VERSION "HNNBNNNYNNNNNNNNNNNNNNNNNNNNNNNNNNNNNNNNNN/4/%%%/4/'%**4NNN///"

NS_ :

BS_:

BU_: AFS_B8 Airbag_B8 Daempfer_B8 Gateway_B8 Getriebe_AL6000 Getriebe_DL5001 Getriebe_VL3002 LWR_B8 Motor_EDC17_003 Motor_EDC17_004 Motor_MED17_B8 Motor_MED9_B8 Motor_SIMOS8_B8 Motor_Slave_B8 Getriebe_AL1000 Motor_MED17_SIMOS8 Motor_EDC17 Gateway_Routing_PAG Gateway_VW EPB_D4 Motor_EDC17_D4 Motor_MED17_003 Hybrid_MSG Hybrid_DQ200 Motor_ME17_BY Motor_MED17_SIMOS8_D4 Motor_EDC17_B8 Getriebe_AL551_951_D4_C7 Getriebe_AL551_Hybrid_D4_C7 Getriebe_DL501_C7 Getriebe_VL381_C7 Motor_MED17_SIMOS8_D4_Hybrid SCU_D4 Gateway_D4C7 Motor_MED17_Q5_Hybrid Fahrwerk STH_D4 Airbag_D4 Gateway_PAG_002 Gateway_VW_T003 Gateway_D4 LEH_Hybrid SCR_C7 BMS_Hybrid Gateway_App_PAG Getriebe_AL1004 Motor_MED17_006 Getriebe_AL5000

BO_ 779 Kombi_01: 8 Gateway_B8
 SG_ KBI_ABS_Lampe : 0|1@1+ (1,0) [0|1] "" Vector__XXX
 SG_ KBI_ESP_Lampe : 1|1@1+ (1,0) [0|1] "" Vector__XXX
 SG_ KBI_BKL_Lampe : 2|1@1+ (1,0) [0|1] "" Vector__XXX
 SG_ KBI_Airbag_Lampe : 3|1@1+ (1,0) [0|1] "" Vector__XXX
 SG_ KBI_SILA_gueltig : 4|1@1+ (1,0) [0|1] "" Vector__XXX
 SG_ KBI_Lenkung_Lampe : 5|1@1+ (1,0) [0|1] "" Vector__XXX
 SG_ KBI_Vorglueh_System_Lampe : 6|1@1+ (1,0) [0|1] "" Vector__XXX
 SG_ KBI_Oeldruck_Schalter : 15|1@1+ (1,0) [0|1] ""  Getriebe_AL551_951_D4_C7
 SG_ KBI_Tankwarnung : 16|1@1+ (1,0) [0|1] ""  Motor_EDC17_003,Motor_EDC17_004,Motor_MED17_B8,Motor_SIMOS8_B8
 SG_ KBI_MFA_v_Einheit_01 : 17|1@1+ (1,0) [0|1] ""  Motor_EDC17_003,Motor_EDC17_004,Motor_MED17_B8,Motor_SIMOS8_B8
 SG_ KBI_im_Stellgliedtest : 18|1@1+ (1,0) [0|1] "" Vector__XXX
 SG_ KBI_Anzeigefehler_LDW : 19|2@1+ (1,0) [0|3] "" Vector__XXX
 SG_ KBI_Variante_USA : 21|1@1+ (1,0) [0|1] "" Vector__XXX
 SG_ KBI_Oeldruckwarnung : 22|1@1+ (1,0) [0|1] "" Vector__XXX
 SG_ KBI_Handbremse : 23|1@1+ (1,0) [0|1] "" Vector__XXX
 SG_ KBI_angez_Geschw : 48|10@1+ (0.32,0) [0|325.12] "km/h"  Getriebe_AL6000,Getriebe_DL5001,Getriebe_VL3002,Motor_EDC17_003,Motor_EDC17_004,Motor_MED17_B8,Motor_SIMOS8_B8
 SG_ KBI_Einheit_Tacho : 58|1@1+ (1,0) [0|1] ""  Getriebe_AL6000,Motor_EDC17_003,Motor_EDC17_004,Motor_MED17_B8,Motor_SIMOS8_B8
 SG_ KBI_Konsistenz_ACC : 59|1@1+ (1,0) [0|1] "" Vector__XXX
 SG_ KBI_Fehler_Anzeige_ACC : 60|1@1+ (1,0) [0|1] "" Vector__XXX
 SG_ KBI_Anzeigefehler_SWA : 61|2@1+ (1,0) [0|3] "" Vector__XXX
 SG_ KBI_KD_Fehler : 63|1@1+ (1,0) [0|1] "" Vector__XXX

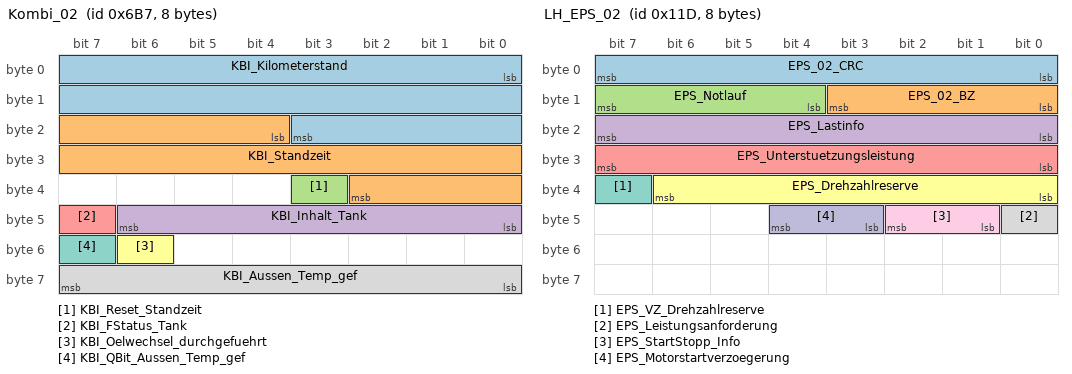
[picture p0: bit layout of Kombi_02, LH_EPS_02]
BO_ 1719 Kombi_02: 8 Gateway_B8
 SG_ KBI_Kilometerstand : 0|20@1+ (1,0) [0|1048573] "km" Vector__XXX
 SG_ KBI_Standzeit : 20|15@1+ (4,0) [0|131068] "s"  Getriebe_AL6000,Getriebe_DL5001,Getriebe_VL3002,Motor_EDC17_003,Motor_EDC17_004,Motor_MED17_B8,Motor_MED9_B8,Motor_SIMOS8_B8
 SG_ KBI_Reset_Standzeit : 35|1@1+ (1,0) [0|1] ""  Getriebe_AL6000,Getriebe_DL5001,Getriebe_VL3002,Motor_EDC17_003,Motor_EDC17_004,Motor_MED17_B8,Motor_MED9_B8,Motor_SIMOS8_B8
 SG_ KBI_Inhalt_Tank : 40|7@1+ (1,0) [0|126] "l"  Motor_EDC17_003,Motor_EDC17_004,Motor_MED17_B8,Motor_MED9_B8,Motor_SIMOS8_B8
 SG_ KBI_FStatus_Tank : 47|1@1+ (1,0) [0|1] ""  Motor_EDC17_003,Motor_EDC17_004,Motor_MED17_B8,Motor_MED9_B8,Motor_SIMOS8_B8
 SG_ KBI_Oelwechsel_durchgefuehrt : 54|1@1+ (1,0) [0|1] ""  Motor_ME17_BY,Motor_MED17_SIMOS8_D4,Motor_MED17_SIMOS8_D4_Hybrid
 SG_ KBI_QBit_Aussen_Temp_gef : 55|1@1+ (1,0) [0|1] ""  Getriebe_AL6000,Getriebe_DL5001,Getriebe_VL3002,Motor_EDC17_003,Motor_EDC17_004,Motor_MED17_B8,Motor_MED9_B8,Motor_SIMOS8_B8
 SG_ KBI_Aussen_Temp_gef : 56|8@1+ (0.5,-50) [-50|75] "°C"  Getriebe_AL6000,Getriebe_DL5001,Getriebe_VL3002,Motor_EDC17_003,Motor_EDC17_004,Motor_MED17_B8,Motor_MED9_B8,Motor_SIMOS8_B8

BO_ 1720 Kombi_03: 8 Gateway_B8
 SG_ KBI_Reifenumfang : 0|12@1+ (1,0) [0|4095] "mm"  Getriebe_AL6000,Getriebe_DL5001,Getriebe_VL3002

BO_ 285 LH_EPS_02: 8 Gateway_D4C7
 SG_ EPS_02_CRC : 0|8@1+ (1,0) [0|255] ""  SCU_D4
 SG_ EPS_02_BZ : 8|4@1+ (1,0) [0|15] ""  SCU_D4
 SG_ EPS_Notlauf : 12|4@1+ (1,0) [0|15] "" Vector__XXX
 SG_ EPS_Lastinfo : 16|8@1+ (1,0) [0|253] "Unit_Amper" Vector__XXX
 SG_ EPS_Unterstuetzungsleistung : 24|8@1+ (0.5,0) [0|100] "Unit_PerCent"  SCU_D4
 SG_ EPS_Drehzahlreserve : 32|7@1+ (10,0) [0|1000] "Unit_DegreOfArcPerSecon"  SCU_D4
 SG_ EPS_VZ_Drehzahlreserve : 39|1@1+ (1,0) [0|1] ""  SCU_D4
 SG_ EPS_Leistungsanforderung : 40|1@1+ (1,0) [0|1] "" Vector__XXX
 SG_ EPS_StartStopp_Info : 41|2@1+ (1,0) [0|3] "" Vector__XXX
 SG_ EPS_Motorstartverzoegerung : 43|2@1+ (1,0) [0|3] "" Vector__XXX

BO_ 1137 Licht_hinten_01: 8 Gateway_B8
 SG_ Licht_hinten_01_BZ : 0|4@1+ (1,0) [0|15] ""  Motor_EDC17_003,Motor_EDC17_004,Motor_MED17_B8,Motor_SIMOS8_B8
 SG_ BCM2_Bremsl_durch_ECD : 5|1@1+ (1,0) [0|1] ""  Motor_EDC17_003,Motor_EDC17_004,Motor_MED17_B8,Motor_SIMOS8_B8
 SG_ LH_Aussenlicht_def : 7|1@1+ (1,0) [0|1] "" Vector__XXX
 SG_ LH_Standlicht_H_aktiv : 8|1@1+ (1,0) [0|1] "" Vector__XXX
 SG_ LH_Parklicht_HL_aktiv : 9|1@1+ (1,0) [0|1] "" Vector__XXX
 SG_ LH_Parklicht_HR_aktiv : 10|1@1+ (1,0) [0|1] "" Vector__XXX
 SG_ LH_Bremslicht_H_aktiv : 11|1@1+ (1,0) [0|1] "" Vector__XXX
 SG_ LH_Nebelschluss_aktiv : 12|1@1+ (1,0) [0|1] "" Vector__XXX
 SG_ LH_Rueckfahrlicht_aktiv : 13|1@1+ (1,0) [0|1] "" Vector__XXX
 SG_ LH_Blinker_HL_akt : 14|1@1+ (1,0) [0|1] "" Vector__XXX
 SG_ LH_Blinker_HR_akt : 15|1@1+ (1,0) [0|1] "" Vector__XXX
 SG_ LH_Blinker_li_def : 16|1@1+ (1,0) [0|1] "" Vector__XXX
 SG_ LH_Bremsl_li_def : 17|1@1+ (1,0) [0|1] "" Vector__XXX
 SG_ LH_Schlusslicht_li_def : 18|1@1+ (1,0) [0|1] "" Vector__XXX
 SG_ LH_Rueckf_li_def : 19|1@1+ (1,0) [0|1] "" Vector__XXX
 SG_ LH_Nebel_li_def : 20|1@1+ (1,0) [0|1] "" Vector__XXX
 SG_ LH_Schluss_Brems_li_def : 24|1@1+ (1,0) [0|1] "" Vector__XXX
 SG_ LH_Schluss_Nebel_li_def : 25|1@1+ (1,0) [0|1] "" Vector__XXX
 SG_ LH_SL_BRL_BLK_li_def : 26|1@1+ (1,0) [0|1] "" Vector__XXX
 SG_ LH_Brems_Blk_li_def : 27|1@1+ (1,0) [0|1] "" Vector__XXX
 SG_ LH_Blinker_re_def : 32|1@1+ (1,0) [0|1] "" Vector__XXX
 SG_ LH_Bremsl_re_def : 33|1@1+ (1,0) [0|1] "" Vector__XXX
 SG_ LH_Schlusslicht_re_def : 34|1@1+ (1,0) [0|1] "" Vector__XXX
 SG_ LH_Rueckf_re_def : 35|1@1+ (1,0) [0|1] "" Vector__XXX
 SG_ LH_Nebel_re_def : 36|1@1+ (1,0) [0|1] "" Vector__XXX
 SG_ LH_Schluss_Brems_re_def : 40|1@1+ (1,0) [0|1] "" Vector__XXX
 SG_ LH_Schluss_Nebel_re_def : 41|1@1+ (1,0) [0|1] "" Vector__XXX
 SG_ LH_SL_BRL_BLK_re_def : 42|1@1+ (1,0) [0|1] "" Vector__XXX
 SG_ LH_Brems_Blk_re_def : 43|1@1+ (1,0) [0|1] "" Vector__XXX
 SG_ LH_Kennzl_def : 48|1@1+ (1,0) [0|1] "" Vector__XXX
 SG_ LH_3_Bremsl_def : 49|1@1+ (1,0) [0|1] ""  Motor_EDC17_003,Motor_EDC17_004,Motor_MED17_B8,Motor_SIMOS8_B8
 SG_ LH_Nebel_mi_def : 50|1@1+ (1,0) [0|1] "" Vector__XXX
 SG_ LH_Rueckf_mi_def : 51|1@1+ (1,0) [0|1] "" Vector__XXX
 SG_ LH_Bremsl_li_ges_def : 54|1@1+ (1,0) [0|1] ""  Motor_EDC17_003,Motor_EDC17_004,Motor_MED17_B8,Motor_SIMOS8_B8
 SG_ LH_Bremsl_re_ges_def : 55|1@1+ (1,0) [0|1] ""  Motor_EDC17_003,Motor_EDC17_004,Motor_MED17_B8,Motor_SIMOS8_B8

BO_ 267 LS_01: 4 Gateway_B8
 SG_ LS_01_CHK : 0|8@1+ (1,0) [0|255] ""  Getriebe_AL6000,Getriebe_DL5001,Getriebe_VL3002,Motor_EDC17_003,Motor_EDC17_004,Motor_MED17_B8,Motor_MED9_B8,Motor_SIMOS8_B8
 SG_ LS_01_BZ : 8|4@1+ (1,0) [0|15] ""  Getriebe_AL6000,Getriebe_DL5001,Getriebe_VL3002,Motor_EDC17_003,Motor_EDC17_004,Motor_MED17_B8,Motor_MED9_B8,Motor_SIMOS8_B8
 SG_ LS_Hauptschalter : 12|1@1+ (1,0) [0|1] ""  Motor_EDC17_003,Motor_EDC17_004,Motor_MED17_B8,Motor_MED9_B8,Motor_SIMOS8_B8
 SG_ LS_Abbrechen : 13|1@1+ (1,0) [0|1] ""  Motor_EDC17_003,Motor_EDC17_004,Motor_MED17_B8,Motor_MED9_B8,Motor_SIMOS8_B8
 SG_ LS_Typ_Hauptschalter : 14|1@1+ (1,0) [0|1] ""  Motor_EDC17_003,Motor_EDC17_004,Motor_MED17_B8,Motor_MED9_B8,Motor_SIMOS8_B8
 SG_ LS_Limiter : 15|1@1+ (1,0) [0|1] ""  Motor_EDC17_003,Motor_EDC17_004,Motor_MED17_B8,Motor_MED9_B8,Motor_SIMOS8_B8
 SG_ LS_Tip_Setzen : 16|1@1+ (1,0) [0|1] ""  Motor_EDC17_003,Motor_EDC17_004,Motor_MED17_B8,Motor_MED9_B8,Motor_SIMOS8_B8
 SG_ LS_Tip_Hoch : 17|1@1+ (1,0) [0|1] ""  Motor_EDC17_003,Motor_EDC17_004,Motor_MED17_B8,Motor_MED9_B8,Motor_SIMOS8_B8
 SG_ LS_Tip_Runter : 18|1@1+ (1,0) [0|1] ""  Motor_EDC17_003,Motor_EDC17_004,Motor_MED17_B8,Motor_MED9_B8,Motor_SIMOS8_B8
 SG_ LS_Tip_Wiederaufnahme : 19|1@1+ (1,0) [0|1] ""  Motor_EDC17_003,Motor_EDC17_004,Motor_MED17_B8,Motor_MED9_B8,Motor_SIMOS8_B8
 SG_ LS_Verstellung_Zeitluecke : 20|2@1+ (1,0) [0|3] "" Vector__XXX
 SG_ MFL_Tip_Down : 22|1@1+ (1,0) [0|1] ""  Getriebe_AL6000,Getriebe_DL5001,Getriebe_VL3002
 SG_ MFL_Tip_Up : 23|1@1+ (1,0) [0|1] ""  Getriebe_AL6000,Getriebe_DL5001,Getriebe_VL3002
 SG_ LS_Tiptronic_Fehler : 24|1@1+ (1,0) [0|1] ""  Getriebe_AL6000,Getriebe_DL5001
 SG_ LS_Fehler : 25|1@1+ (1,0) [0|1] ""  Motor_EDC17_003,Motor_EDC17_004,Motor_MED17_B8,Motor_MED9_B8,Motor_SIMOS8_B8
 SG_ LS_Tip_Stufe_2 : 29|1@1+ (1,0) [0|1] ""  Motor_EDC17,Motor_MED17_SIMOS8
 SG_ LS_GRA_ACC_2stufig : 30|1@1+ (1,0) [0|1] ""  Motor_EDC17,Motor_MED17_SIMOS8
 SG_ LS_Codierung : 26|3@1+ (1,0) [0|7] ""  Motor_EDC17_003,Motor_EDC17_004,Motor_MED17_B8,Motor_MED9_B8,Motor_SIMOS8_B8

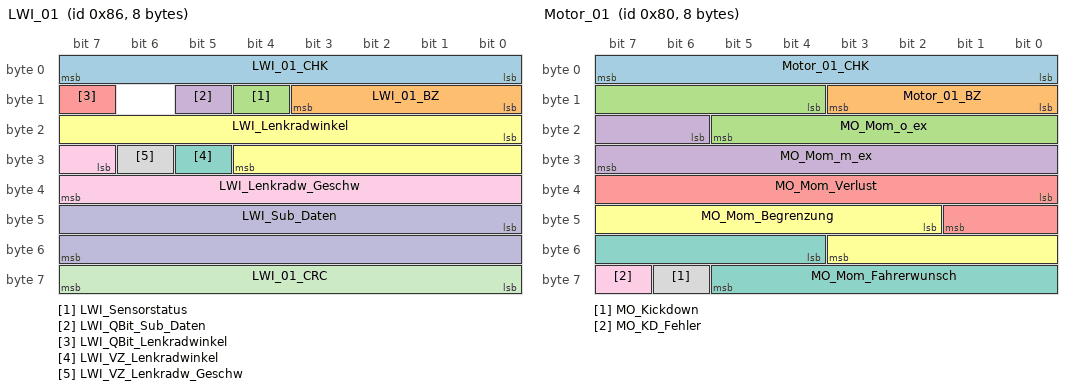
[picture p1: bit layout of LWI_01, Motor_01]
BO_ 134 LWI_01: 8 Gateway_B8
 SG_ LWI_01_CHK : 0|8@1+ (1,0) [0|255] ""  Daempfer_B8,Getriebe_AL6000,Getriebe_DL5001,Getriebe_VL3002,Motor_EDC17_003,Motor_EDC17_004,Motor_MED17_B8,Motor_MED9_B8,Motor_SIMOS8_B8
 SG_ LWI_01_BZ : 8|4@1+ (1,0) [0|15] ""  Daempfer_B8,Getriebe_AL6000,Getriebe_DL5001,Getriebe_VL3002,Motor_EDC17_003,Motor_EDC17_004,Motor_MED17_B8,Motor_MED9_B8,Motor_SIMOS8_B8
 SG_ LWI_Sensorstatus : 12|1@1+ (1,0) [0|1] ""  AFS_B8,Getriebe_AL6000,Motor_EDC17_003,Motor_EDC17_004,Motor_MED17_B8,Motor_MED9_B8,Motor_SIMOS8_B8
 SG_ LWI_QBit_Sub_Daten : 13|1@1+ (1,0) [0|1] "" Vector__XXX
 SG_ LWI_QBit_Lenkradwinkel : 15|1@1+ (1,0) [0|1] ""  Daempfer_B8,Getriebe_AL6000,Motor_EDC17_003,Motor_EDC17_004,Motor_MED17_B8,Motor_MED9_B8,Motor_SIMOS8_B8
 SG_ LWI_Lenkradwinkel : 16|13@1+ (0.1,0) [0|800] "Grad"  AFS_B8,Daempfer_B8,Getriebe_AL6000,Getriebe_DL5001,Getriebe_VL3002,Motor_EDC17_003,Motor_EDC17_004,Motor_MED17_B8,Motor_MED9_B8,Motor_SIMOS8_B8
 SG_ LWI_VZ_Lenkradwinkel : 29|1@1+ (1,0) [0|1] ""  AFS_B8,Daempfer_B8,Getriebe_AL6000,Motor_EDC17_003,Motor_EDC17_004,Motor_MED17_B8,Motor_MED9_B8,Motor_SIMOS8_B8
 SG_ LWI_VZ_Lenkradw_Geschw : 30|1@1+ (1,0) [0|1] "" Vector__XXX
 SG_ LWI_Lenkradw_Geschw : 31|9@1+ (5,0) [0|2500] "Grad/s" Vector__XXX
 SG_ LWI_Sub_Daten : 40|16@1+ (1,0) [0|65535] "" Vector__XXX
 SG_ LWI_01_CRC : 56|8@1+ (1,0) [0|255] "" Vector__XXX

BO_ 917 LWR_AFS_01: 8 AFS_B8
 SG_ LWR_AFS_01_BZ : 8|4@1+ (1,0) [0|15] ""  Gateway_B8
 SG_ AFS_Lampe : 12|1@1+ (1,0) [0|1] ""  Gateway_B8
 SG_ LWR_Lampe : 13|1@1+ (1,0) [0|1] ""  Gateway_B8
 SG_ AFS_Fehlertext : 14|1@1+ (1,0) [0|1] ""  Gateway_B8
 SG_ AFS_LED_Blinkmode : 15|1@1+ (1,0) [0|1] ""  Gateway_B8
 SG_ LWR_Touristenmodus_aktiv : 16|1@1+ (1,0) [0|1] ""  Gateway_B8
 SG_ AFS_Sollwert_LD_EVG : 24|8@1+ (0.4,50) [50|151.2] "%"  Gateway_B8
 SG_ LWR_Pos_Schrittmotor : 32|8@1+ (0.4,0) [0|100] "%"  Gateway_B8
 SG_ LWR_Hoehenwert_VL : 40|8@1+ (1,-127) [-127|126] ""  Gateway_B8
 SG_ LWR_Hoehenwert_HL : 48|8@1+ (1,-127) [-127|126] ""  Gateway_B8
 SG_ AFS_Ersatzlicht_Links : 56|1@1+ (1,0) [0|1] ""  Gateway_B8
 SG_ AFS_Ersatzlicht_Rechts : 57|1@1+ (1,0) [0|1] ""  Gateway_B8
 SG_ LWR_AFS_Grundeinstellung : 58|1@1+ (1,0) [0|1] ""  Gateway_B8
 SG_ LWR_AFS_Parametrisierung : 59|1@1+ (1,0) [0|1] ""  Gateway_B8
 SG_ LWR_Initialisierungslauf : 60|1@1+ (1,0) [0|1] ""  Gateway_B8
 SG_ LWR_Sicherheitsposition : 61|1@1+ (1,0) [0|1] ""  Gateway_B8
 SG_ LWR_Modus : 62|1@1+ (1,0) [0|1] ""  Gateway_B8
 SG_ LWR_KD_Fehler : 63|1@1+ (1,0) [0|1] ""  Gateway_B8

BO_ 128 Motor_01: 8 Motor_EDC17_003
 SG_ Motor_01_CHK : 0|8@1+ (1,0) [0|255] ""  Daempfer_B8,Gateway_B8,Getriebe_AL6000,Getriebe_DL5001,Getriebe_VL3002
 SG_ Motor_01_BZ : 8|4@1+ (1,0) [0|15] ""  Daempfer_B8,Gateway_B8,Getriebe_AL6000,Getriebe_DL5001,Getriebe_VL3002
 SG_ MO_Mom_o_ex : 12|10@1+ (1,0) [0|1021] ""  Gateway_B8,Getriebe_AL6000,Getriebe_DL5001,Getriebe_VL3002
 SG_ MO_Mom_m_ex : 22|10@1+ (1,0) [0|1021] ""  Gateway_B8,Getriebe_AL6000,Getriebe_DL5001,Getriebe_VL3002
 SG_ MO_Mom_Verlust : 32|10@1+ (1,0) [0|1021] ""  Gateway_B8,Getriebe_AL6000,Getriebe_DL5001,Getriebe_VL3002
 SG_ MO_Mom_Begrenzung : 42|10@1+ (1,0) [0|1021] ""  Gateway_B8,Getriebe_AL6000,Getriebe_DL5001,Getriebe_VL3002
 SG_ MO_Mom_Fahrerwunsch : 52|10@1+ (1,0) [0|1021] ""  Daempfer_B8,Gateway_B8,Getriebe_AL6000,Getriebe_DL5001,Getriebe_VL3002
 SG_ MO_Kickdown : 62|1@1+ (1,0) [0|1] ""  Gateway_B8,Getriebe_AL6000,Getriebe_DL5001,Getriebe_VL3002
 SG_ MO_KD_Fehler : 63|1@1+ (1,0) [0|1] ""  Gateway_B8

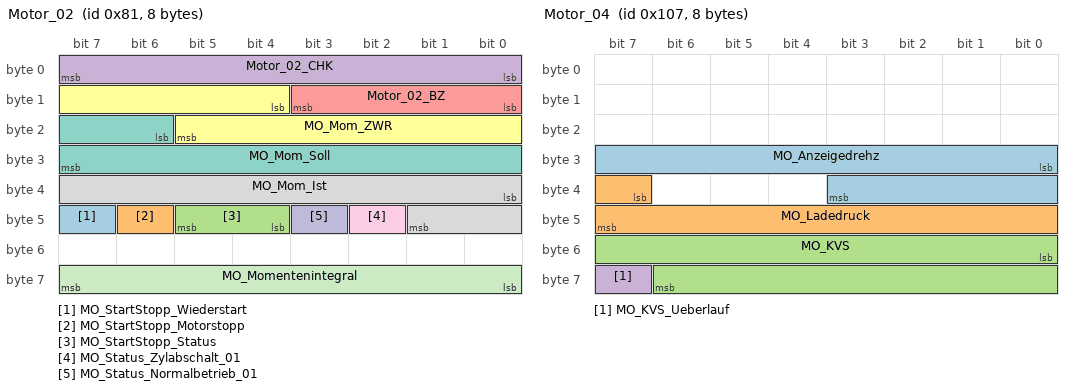
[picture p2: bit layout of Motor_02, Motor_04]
BO_ 129 Motor_02: 8 Motor_EDC17_003
 SG_ MO_StartStopp_Wiederstart : 47|1@1+ (1,0) [0|0] "" Vector__XXX
 SG_ MO_StartStopp_Motorstopp : 46|1@1+ (1,0) [0|0] "" Vector__XXX
 SG_ MO_StartStopp_Status : 44|2@1+ (1,0) [0|0] "" Vector__XXX
 SG_ Motor_02_CHK : 0|8@1+ (1,0) [0|255] ""  Gateway_B8,Getriebe_AL6000,Getriebe_DL5001,Getriebe_VL3002
 SG_ Motor_02_BZ : 8|4@1+ (1,0) [0|15] ""  Gateway_B8,Getriebe_AL6000,Getriebe_DL5001,Getriebe_VL3002
 SG_ MO_Mom_ZWR : 12|10@1+ (1,0) [0|1021] ""  Gateway_B8
 SG_ MO_Mom_Soll : 22|10@1+ (1,0) [0|1021] ""  Gateway_B8,Getriebe_AL6000,Getriebe_DL5001,Getriebe_VL3002
 SG_ MO_Mom_Ist : 32|10@1+ (1,0) [0|1021] ""  Gateway_B8,Getriebe_AL6000,Getriebe_DL5001,Getriebe_VL3002
 SG_ MO_Status_Zylabschalt_01 : 42|1@1+ (1,0) [0|1] ""  Gateway_B8,Getriebe_AL6000,Getriebe_DL5001,Getriebe_VL3002
 SG_ MO_Status_Normalbetrieb_01 : 43|1@1+ (1,0) [0|1] ""  Gateway_B8,Getriebe_AL6000,Getriebe_DL5001,Getriebe_VL3002
 SG_ MO_Momentenintegral : 56|8@1+ (0.3921,0) [0|99.9855] ""  Gateway_B8,Getriebe_AL6000,Getriebe_DL5001,Getriebe_VL3002

BO_ 261 Motor_03: 8 Motor_EDC17_003
 SG_ Motor_03_CHK : 0|8@1+ (1,0) [0|255] ""  Daempfer_B8,Gateway_B8,Getriebe_AL6000,Getriebe_DL5001,Getriebe_VL3002
 SG_ Motor_03_BZ : 8|4@1+ (1,0) [0|15] ""  Daempfer_B8,Gateway_B8,Getriebe_AL6000,Getriebe_DL5001,Getriebe_VL3002
 SG_ MO_QBit_Fahrpedalwerte_01 : 12|1@1+ (1,0) [0|1] ""  Gateway_B8
 SG_ MO_QBit_Motormomente : 13|1@1+ (1,0) [0|1] ""  Gateway_B8,Getriebe_AL6000,Getriebe_DL5001,Getriebe_VL3002
 SG_ MO_QBit_Fahrer_bremst : 14|1@1+ (1,0) [0|1] ""  Gateway_B8,Getriebe_AL6000,Getriebe_DL5001,Getriebe_VL3002
 SG_ MO_QBit_Drehzahl_01 : 15|1@1+ (1,0) [0|1] ""  Gateway_B8
 SG_ MO_Drehzahl_01 : 16|16@1+ (0.25,0) [0|16383] "1/min"  AFS_B8,Gateway_B8,LWR_B8
 SG_ MO_Moment_im_Leerlauf : 32|1@1+ (1,0) [0|1] ""  Gateway_B8
 SG_ MO_Interlock : 33|1@1+ (1,0) [0|1] ""  Gateway_B8
 SG_ MO_BLS : 34|1@1+ (1,0) [0|1] ""  AFS_B8,Daempfer_B8,Gateway_B8,Getriebe_AL6000,Getriebe_DL5001,Getriebe_VL3002,LWR_B8
 SG_ MO_Fahrer_bremst : 35|1@1+ (1,0) [0|1] ""  Gateway_B8,Getriebe_AL6000,Getriebe_DL5001,Getriebe_VL3002
 SG_ MO_Konsistenz_Bremsped : 36|1@1+ (1,0) [0|1] ""  Gateway_B8,Getriebe_AL6000,Getriebe_DL5001,Getriebe_VL3002
 SG_ MO_Kuppl_schalter : 37|1@1+ (1,0) [0|1] ""  Gateway_B8
 SG_ MO_Timeout_ESP : 38|1@1+ (1,0) [0|1] ""  Gateway_B8
 SG_ MO_Motor_laeuft : 39|1@1+ (1,0) [0|1] ""  Gateway_B8
 SG_ MO_Solldrehz_Leerlauf : 40|8@1+ (10,0) [0|2540] "1/min"  Gateway_B8,Getriebe_AL6000,Getriebe_DL5001,Getriebe_VL3002
 SG_ MO_Fahrpedalrohwert_01 : 48|8@1+ (0.4,0) [0|101.6] "%"  Gateway_B8
 SG_ MO_erste_Ungenauschwelle : 56|1@1+ (1,0) [0|1] ""  Gateway_B8,Getriebe_AL6000,Getriebe_DL5001,Getriebe_VL3002
 SG_ MO_QBit_Stressfaktor : 57|1@1+ (1,0) [0|1] ""  Gateway_B8,Getriebe_AL6000,Getriebe_DL5001,Getriebe_VL3002
 SG_ MO_Stressfaktor : 58|6@1+ (1.6,0) [0|100.8] "%"  Gateway_B8,Getriebe_AL6000,Getriebe_DL5001,Getriebe_VL3002

BO_ 263 Motor_04: 8 Motor_EDC17_003
 SG_ MO_Anzeigedrehz : 24|12@1+ (3,0) [0|12282] "1/min"  Gateway_B8
 SG_ MO_Ladedruck : 39|9@1+ (0.01,0) [0|5.1] "bar"  Gateway_B8
 SG_ MO_KVS : 48|15@1+ (1,0) [0|32767] "ul"  Gateway_B8
 SG_ MO_KVS_Ueberlauf : 63|1@1+ (1,0) [0|1] ""  Gateway_B8

BO_ 782 Motor_05: 8 Motor_EDC17_003
 SG_ Motor_05_CHK : 0|8@1+ (1,0) [0|255] ""  Getriebe_AL6000,Getriebe_DL5001,Getriebe_VL3002
 SG_ Motor_05_BZ : 8|4@1+ (1,0) [0|15] ""  Getriebe_AL6000,Getriebe_DL5001,Getriebe_VL3002
 SG_ MO_EKlKomLeiRed : 12|2@1+ (1,0) [0|3] ""  Gateway_PAG_002,Gateway_VW_T003
 SG_ MO_Freig_Reku : 14|2@1+ (1,0) [0|3] ""  Getriebe_AL6000,Getriebe_DL5001,Getriebe_VL3002
 SG_ MO_Klima_Eingr : 16|2@1+ (1,0) [0|3] ""  Gateway_B8
 SG_ MO_Status_Normalbetrieb : 18|1@1+ (1,0) [0|1] ""  Getriebe_AL6000,Getriebe_DL5001
 SG_ MO_Schaltbeeinfl_Leistungsbegr : 19|1@1+ (1,0) [0|1] ""  Getriebe_AL6000,Getriebe_DL5001
 SG_ MO_Schaltbeeinfl_Partikelfilter : 20|1@1+ (1,0) [0|1] ""  Getriebe_AL6000,Getriebe_DL5001
 SG_ MO_Prio_MIN_Wunschdrehzahl : 21|1@1+ (1,0) [0|1] ""  Getriebe_AL6000,Getriebe_DL5001,Getriebe_VL3002
 SG_ MO_Freig_Anlass : 22|1@1+ (1,0) [0|1] ""  Gateway_B8
 SG_ MO_Aussp_Anlass : 23|1@1+ (1,0) [0|1] ""  Gateway_B8
 SG_ MO_MAX_Wunschdrehzahl : 24|9@1+ (25,0) [0|12750] "1/min"  Getriebe_AL6000,Getriebe_DL5001,Getriebe_VL3002
 SG_ MO_Prio_MAX_Wunschdrehzahl : 33|1@1+ (1,0) [0|1] ""  Getriebe_AL6000,Getriebe_DL5001,Getriebe_VL3002
 SG_ MO_Luftpfad_aktiv : 34|1@1+ (1,0) [0|1] ""  Getriebe_AL6000,Getriebe_DL5001
 SG_ MO_v_Begrenz_Aktiv : 35|1@1+ (1,0) [0|1] "" Vector__XXX
 SG_ MO_v_Begrenz_Aktivierbar : 36|1@1+ (1,0) [0|1] "" Vector__XXX
 SG_ MO_Verbot_EKP : 37|1@1+ (1,0) [0|1] ""  Gateway_B8
 SG_ MO_Anf_Pruefimpuls : 38|1@1+ (1,0) [0|1] ""  Gateway_B8
 SG_ MO_Anf_KL75 : 39|1@1+ (1,0) [0|1] ""  Gateway_B8
 SG_ MO_Charisma_FahrPr : 40|3@1+ (1,0) [0|7] ""  Gateway_B8
 SG_ MO_Charisma_Status : 43|2@1+ (1,0) [0|3] ""  Gateway_B8
 SG_ MO_Charisma_Umschaltung : 45|2@1+ (1,0) [0|3] ""  Gateway_B8
 SG_ MO_Handshake_STH : 47|1@1+ (1,0) [0|1] ""  Gateway_B8
 SG_ MO_MIN_Wunschdrehzahl : 48|8@1+ (25,0) [0|6350] "1/min"  Getriebe_AL6000,Getriebe_DL5001,Getriebe_VL3002
 SG_ MO_Drehzahlbeeinflussung : 56|8@1+ (0.39,0) [0|99.45] "%"  Getriebe_AL6000,Getriebe_DL5001,Getriebe_VL3002

BO_ 1088 Motor_06: 8 Motor_EDC17_003
 SG_ MO_Kuehlerluefter_MUX M : 0|1@1+ (1,0) [0|1] ""  Gateway_D4
 SG_ MO_Kuehlerluefter_1 m0 : 1|7@1+ (1,0) [0|100] "Unit_PerCent"  Gateway_D4
 SG_ MO_Kuehlerluefter_2 m1 : 1|7@1+ (1,0) [0|100] "Unit_PerCent"  Gateway_D4
 SG_ WIV_Anzeige_aktiv : 12|1@1+ (1,0) [0|1] ""  Gateway_B8
 SG_ WIV_Oelmin_Warn : 13|1@1+ (1,0) [0|1] ""  Gateway_B8
 SG_ WIV_Sensorfehler : 14|1@1+ (1,0) [0|1] ""  Gateway_B8
 SG_ WIV_Schieflage : 15|1@1+ (1,0) [0|1] ""  Gateway_B8
 SG_ WIV_Oelstand : 16|4@1+ (12.5,0) [0|100] "%"  Gateway_B8
 SG_ WIV_Oelsystem_aktiv : 24|1@1+ (1,0) [0|1] ""  Gateway_B8
 SG_ WIV_nicht_betriebswarm : 25|1@1+ (1,0) [0|1] ""  Gateway_B8
 SG_ WIV_Ueberfuell_Warn : 26|1@1+ (1,0) [0|1] ""  Gateway_B8
 SG_ WIV_laufender_Motor : 27|1@1+ (1,0) [0|1] ""  Gateway_B8
 SG_ MO_Text_Motorstart : 32|4@1+ (1,0) [0|15] ""  Gateway_B8
 SG_ MO_Text_MSG_Werkstatt : 40|1@1+ (1,0) [0|1] ""  Gateway_B8
 SG_ MO_Text_Partikelfil_Reg : 41|1@1+ (1,0) [0|1] ""  Gateway_B8
 SG_ MO_Text_Fehler_Kraftstoffsys : 42|1@1+ (1,0) [0|1] ""  Gateway_B8
 SG_ WIV_Oelmenge : 43|5@1+ (125,0) [0|3875] "ml"  Gateway_B8
 SG_ MO_Systemlampe : 48|1@1+ (1,0) [0|1] ""  Gateway_B8
 SG_ MO_OBD2_Lampe : 49|1@1+ (1,0) [0|1] ""  Gateway_B8
 SG_ MO_Heissleuchte : 50|1@1+ (1,0) [0|1] ""  Gateway_B8
 SG_ MO_Partikel_Lampe : 51|1@1+ (1,0) [0|1] ""  Gateway_B8
 SG_ MO_Winterfahrprog : 52|1@1+ (1,0) [0|1] ""  Gateway_B8
 SG_ WIV_Oelstand_nicht_vorhanden : 53|1@1+ (1,0) [0|1] ""  Gateway_B8
 SG_ WIV_nachfuellanzeige_ein : 54|1@1+ (1,0) [0|1] ""  Gateway_B8
 SG_ WIV_Check_Oil : 55|1@1+ (1,0) [0|1] ""  Gateway_B8
 SG_ WIV_Unterfuell_Warn : 56|1@1+ (1,0) [0|1] ""  Gateway_B8
 SG_ MO_Tankdeckel_Lampe : 57|1@1+ (1,0) [0|1] ""  Gateway_B8
 SG_ MO_Text_Tankdeckelwarn : 58|1@1+ (1,0) [0|1] ""  Gateway_B8
 SG_ WIV_Enable_Oeldr_Motor : 59|1@1+ (1,0) [0|1] ""  Gateway_B8
 SG_ WIV_Oeldr_Warn_Motor : 60|1@1+ (1,0) [0|1] ""  Gateway_B8
 SG_ MO_Avus_Motorschutz : 61|2@1+ (1,0) [0|3] ""  Gateway_B8

BO_ 1600 Motor_07: 8 Motor_EDC17_D4
 SG_ MO_QBit_Ansaugluft_Temp : 0|1@1+ (1,0) [0|1] ""  Gateway_D4C7,Getriebe_AL551_951_D4_C7,Getriebe_AL551_Hybrid_D4_C7,Getriebe_DL501_C7,Getriebe_VL381_C7
 SG_ MO_QBit_Oel_Temp : 1|1@1+ (1,0) [0|1] ""  Gateway_D4C7,Getriebe_AL551_951_D4_C7,Getriebe_AL551_Hybrid_D4_C7
 SG_ MO_QBit_Kuehlmittel_Temp : 2|1@1+ (1,0) [0|1] ""  Gateway_D4C7,Getriebe_AL551_951_D4_C7,Getriebe_AL551_Hybrid_D4_C7,Getriebe_DL501_C7,Getriebe_VL381_C7,LEH_Hybrid
 SG_ MO_Stellgliedtest_Soundaktuator : 3|1@1+ (1,0) [0|1] ""  Gateway_D4C7
 SG_ MO_HYB_Fehler_HV_Netz : 4|1@1+ (1,0) [0|1] ""  Gateway_D4C7
 SG_ MO_aktives_Getriebeheizen : 5|1@1+ (1,0) [0|1] ""  Gateway_D4C7,Getriebe_AL551_951_D4_C7,Getriebe_AL551_Hybrid_D4_C7,Getriebe_DL501_C7,Getriebe_VL381_C7
 SG_ MO_Absperrventil_oeffnen : 6|2@1+ (1,0) [0|3] ""  Gateway_D4C7
 SG_ MO_Ansaugluft_Temp : 8|8@1+ (0.75,-48) [-48|141.75] "Unit_DegreCelsi"  Gateway_D4C7,Getriebe_AL551_951_D4_C7,Getriebe_AL551_Hybrid_D4_C7,Getriebe_DL501_C7,Getriebe_VL381_C7
 SG_ MO_Oel_Temp : 16|8@1+ (1,-60) [-60|192] "Unit_DegreCelsi"  Gateway_D4C7,Getriebe_AL551_951_D4_C7,Getriebe_AL551_Hybrid_D4_C7
 SG_ MO_Kuehlmittel_Temp : 24|8@1+ (0.75,-48) [-48|141.75] "Unit_DegreCelsi"  Gateway_D4C7,Getriebe_AL551_951_D4_C7,Getriebe_AL551_Hybrid_D4_C7,Getriebe_DL501_C7,Getriebe_VL381_C7,LEH_Hybrid
 SG_ MO_Hoeheninfo : 32|8@1+ (0.00781,0) [0|1.98374] ""  Gateway_D4C7,Getriebe_AL551_951_D4_C7,Getriebe_AL551_Hybrid_D4_C7,Getriebe_DL501_C7,Getriebe_VL381_C7
 SG_ MO_Kennfeldk : 40|1@1+ (1,0) [0|1] ""  Gateway_D4C7
 SG_ MO_Versionsinfo : 41|6@1+ (1,0) [0|63] ""  Gateway_D4C7
 SG_ MO_Getriebe_kuehlen : 47|1@1+ (1,0) [0|1] ""  Gateway_D4C7,Getriebe_AL551_951_D4_C7,Getriebe_AL551_Hybrid_D4_C7,Getriebe_DL501_C7,Getriebe_VL381_C7
 SG_ MO_Mom_Traegheit_02 : 48|5@1+ (0.01,0) [0|0.31] "Unit_KiloGramMeterSquar"  Gateway_D4C7,Getriebe_AL551_951_D4_C7,Getriebe_AL551_Hybrid_D4_C7,Getriebe_DL501_C7,Getriebe_VL381_C7
 SG_ MO_Heizungspumpenansteuerung : 53|4@1+ (10,0) [0|100] "Unit_PerCent"  Gateway_D4C7
 SG_ MO_SpannungsAnf : 57|1@1+ (1,0) [0|1] ""  Gateway_D4C7
 SG_ MO_Nachlaufzeit_Heizungspumpe : 58|6@1+ (15,0) [0|945] "Unit_Secon"  Gateway_D4C7

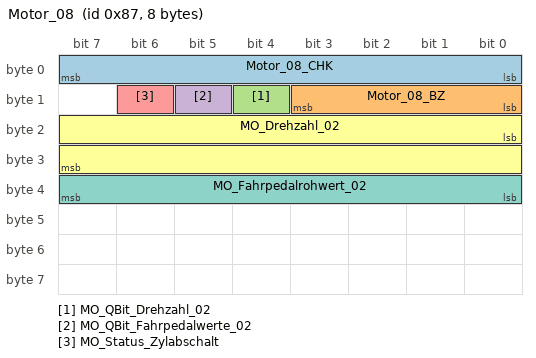
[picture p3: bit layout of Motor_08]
BO_ 135 Motor_08: 8 Motor_EDC17_003
 SG_ Motor_08_CHK : 0|8@1+ (1,0) [0|255] ""  Getriebe_AL6000,Getriebe_DL5001,Getriebe_VL3002
 SG_ Motor_08_BZ : 8|4@1+ (1,0) [0|15] ""  Getriebe_AL6000,Getriebe_DL5001,Getriebe_VL3002
 SG_ MO_QBit_Drehzahl_02 : 12|1@1+ (1,0) [0|1] ""  Getriebe_AL6000,Getriebe_DL5001,Getriebe_VL3002
 SG_ MO_QBit_Fahrpedalwerte_02 : 13|1@1+ (1,0) [0|1] ""  Getriebe_AL6000,Getriebe_DL5001,Getriebe_VL3002
 SG_ MO_Status_Zylabschalt : 14|1@1+ (1,0) [0|1] ""  Getriebe_AL6000,Getriebe_DL5001,Getriebe_VL3002
 SG_ MO_Drehzahl_02 : 16|16@1+ (0.25,0) [0|16383] "1/min"  Getriebe_AL6000,Getriebe_DL5001,Getriebe_VL3002
 SG_ MO_Fahrpedalrohwert_02 : 32|8@1+ (0.4,0) [0|101.6] "%"  Getriebe_AL6000,Getriebe_DL5001,Getriebe_VL3002

BO_ 1607 Motor_09: 8 Motor_EDC17_D4
 SG_ MO_ITM_Kuehlmittel_Temp : 0|8@1+ (0.75,-48) [-45.75|143.25] "Unit_DegreCelsi"  Gateway_D4C7
 SG_ MO_E85_Sensor : 8|4@1+ (10,0) [0|100] "Unit_PerCent"  Gateway_D4C7
 SG_ SCR_Anz_Motorstarts : 12|4@1+ (1,0) [0|8] ""  Gateway_D4C7
 SG_ SCR_Reichweite : 16|15@1+ (1,0) [0|32766] ""  Gateway_D4C7
 SG_ SCR_Warnstufe_1 : 32|1@1+ (1,0) [0|1] ""  Gateway_D4C7
 SG_ SCR_Warnstufe_2 : 33|1@1+ (1,0) [0|1] ""  Gateway_D4C7
 SG_ SCR_Text : 34|3@1+ (1,0) [0|7] ""  Gateway_D4C7
 SG_ SCR_Akustik : 37|2@1+ (1,0) [0|3] ""  Gateway_D4C7
 SG_ MO_Kraftstofffilter_Wasser : 40|1@1+ (1,0) [0|1] ""  Gateway_D4C7
 SG_ SCR_Systemfehler : 41|1@1+ (1,0) [0|1] ""  Gateway_D4C7
 SG_ SCR_Inducement_Strategie : 42|2@1+ (1,0) [0|3] ""  Gateway_D4C7
 SG_ MO_CO2_Faktor : 44|12@1+ (1,0) [1|4094] "Unit_GramPerLiter"  Gateway_D4C7
 SG_ MO_MKB_MUX M : 56|2@1+ (1,0) [0|3] ""  Gateway_D4C7
 SG_ MO_MKB_01 m0 : 59|5@1+ (1,0) [0|31] ""  Gateway_D4C7
 SG_ MO_MKB_02 m1 : 59|5@1+ (1,0) [0|31] ""  Gateway_D4C7
 SG_ MO_MKB_03 m2 : 59|5@1+ (1,0) [0|31] ""  Gateway_D4C7
 SG_ MO_MKB_04 m3 : 59|5@1+ (1,0) [0|31] ""  Gateway_D4C7

BO_TX_BU_ 917 : AFS_B8,LWR_B8;
BO_TX_BU_ 128 : Motor_EDC17_003,Motor_EDC17_004,Motor_MED17_B8,Motor_MED9_B8,Motor_SIMOS8_B8;
BO_TX_BU_ 129 : Motor_EDC17_003,Motor_EDC17_004,Motor_MED17_B8,Motor_MED9_B8,Motor_SIMOS8_B8;
BO_TX_BU_ 261 : Motor_EDC17_003,Motor_EDC17_004,Motor_MED17_B8,Motor_MED9_B8,Motor_SIMOS8_B8;
BO_TX_BU_ 263 : Motor_EDC17_003,Motor_EDC17_004,Motor_MED17_B8,Motor_MED9_B8,Motor_SIMOS8_B8;
BO_TX_BU_ 782 : Motor_EDC17_003,Motor_EDC17_004,Motor_MED17_B8,Motor_MED9_B8,Motor_SIMOS8_B8;
BO_TX_BU_ 1088 : Motor_EDC17_003,Motor_EDC17_004,Motor_MED17_B8,Motor_MED9_B8,Motor_SIMOS8_B8;
BO_TX_BU_ 1600 : Motor_EDC17_003,Motor_EDC17_004,Motor_MED17_B8,Motor_MED9_B8,Motor_SIMOS8_B8;
BO_TX_BU_ 135 : Motor_EDC17_003,Motor_EDC17_004,Motor_MED17_B8,Motor_MED9_B8,Motor_SIMOS8_B8;
CM_ SG_ 779 KBI_ABS_Lampe "ABS-Sicherheits-Lampe wurde eingeschaltet.";
CM_ SG_ 779 KBI_ESP_Lampe "ESP-Sicherheits-Lampe wurde eingeschaltet ";
CM_ SG_ 779 KBI_BKL_Lampe "Sicherheits-Lampe Bremskontrolle wurde eingeschaltet; Besonderheit (VW PQ35/46): Lampe wird auch zur Handbremskontrolle (Audi: auch von EPB) und Bremsflüssigkeitswarnung (auch bei Audi) verwendet und vom Kombi aufgeprüft
";
CM_ SG_ 779 KBI_Airbag_Lampe "Airbag Sicherheits-Lampe wurde eingeschaltet ";
CM_ SG_ 779 KBI_SILA_gueltig "Rückmeldeinformation (Bit 1-6) ist gültig";
CM_ SG_ 779 KBI_Lenkung_Lampe "Sicherheits-Lampe der Lenkung (Lenkhilfe EPS, Audi-Dynamic-Steering ...) wurde eingeschaltet.

0x0 = Lenkungs-Lampe aus
0x1 = Lenkungs-Lampe ein";
CM_ SG_ 779 KBI_Vorglueh_System_Lampe "Rückmeldung der Vorglühlampe bzw. Motor Systemlampe (MO_Systemlampe) an den Motor (bei Diesel und Otto!). Hardwaremässig gleiche LED im Kombi (EPC- oder Glühwendel), Unterscheidung nur über Ziffernblatt.";
CM_ SG_ 779 KBI_Tankwarnung "Fahrer wird gewarnt, z.Zt. liegt die Warnschwelle bei 7 Liter.";
CM_ SG_ 779 KBI_MFA_v_Einheit_01 "Einheit der Geschwindigkeit, die vom Fahrer im Car-Menü gewählt wurde. Veränderliche Grösse, im Gegensatz zur Einheit des Tachokranzes.";
CM_ SG_ 779 KBI_im_Stellgliedtest "Kombi im Stellgliedtest, Signal muss eingelesen werden, um Fehlfunktion aufgrund der Bewegung der Stellglieder (Drehzahlmesser, Tacho) des Kombis zu verhindern";
CM_ SG_ 779 KBI_Variante_USA "In diesem Signal wird die HW-Variante des Kombis ausgegeben, ACC plausibilisiert auf dieses Signal hin seine US-Codierung";
CM_ SG_ 779 KBI_Oeldruckwarnung "Öldruckwarnung im Kombi aktiv";
CM_ SG_ 779 KBI_angez_Geschw "Im Tacho angezeigte Geschwindigkeit inklusive der Voreilung

";
CM_ SG_ 779 KBI_Einheit_Tacho "Information, ob es sich um Meilen- oder Kmh-Kombi handelt, Einheit des Tachos entspricht dem Zifferblatt, Grösse ist nicht veränderlich";
CM_ SG_ 779 KBI_Konsistenz_ACC "Rückmeldung an ACC, dass die Botschaften zur Ansteuerung von Anzeigen nicht bzw. nicht konsistent empfangen wurden (Timeout-, BZ-, CHK- und DLC-Fehler)                                                                                                        ";
CM_ SG_ 779 KBI_Fehler_Anzeige_ACC "Rückmeldung an ACC, dass mindestens eine der ACC-relevanten Anzeigen -rote Fahrerübernahme, Mitteldisplay, Gong - fehlerhaft sind.";
CM_ SG_ 779 KBI_Anzeigefehler_SWA "Signal bezieht sich nur auf die SWA-Lampe, Vorhalt für Kombis mit SWA-Lampe. ";
CM_ SG_ 1719 KBI_Kilometerstand "Fehler wird ausgegeben, falls Kilometerstand nicht restaurierbar
";
CM_ SG_ 1719 KBI_Standzeit "Low Byte 4, High Byte 5;
Standzeit in 4 Sekunden Auflösung; mit diesen 15 Bits läßt sich eine Zeit bis 36 Stunden, 24 Minuten und 28 Sekunden darstellen;
Der Standzeitzähler wird mit KL15_Aus gestartet, er bleibt 2 Minuten vor einem Überlauf stehen, di";
CM_ SG_ 1719 KBI_Inhalt_Tank "Restmenge 2 bzw. 2,5l nicht auflösbar

0x7F = Fehler

";
CM_ SG_ 1719 KBI_FStatus_Tank "Signal wird gesetzt:

a) Während der Fehlerentprellzeit (20 s Entprellung)

b) Bei erkanntem Fehler wird der Tankinhalt während der laufenden KL15-Phase über den
    Verbrauch zurückgerechnet. In dieser Zeit ist das Bit ebenfalls gesetzt. Nach einem";
CM_ SG_ 1719 KBI_QBit_Aussen_Temp_gef "0x0 = gültiger Wert
0x1 = Ersatz-, Init- oder Fehlerwert";
CM_ SG_ 1720 KBI_Reifenumfang "Mittlerer Radumfang aus der K-Zahl gerechnet in Millimeter.  Byte 2 Bit 5,4 reserviert, Byte 2 Bit 3..0 und Byte 1 Bit 7..0; Wertebereich 0..4096 mm
";
CM_ SG_ 1137 Licht_hinten_01_BZ "überlaufender 4bit Botschaftszaehler; wird in jeder Sendebotschaft inkrementiert";
CM_ SG_ 1137 BCM2_Bremsl_durch_ECD "Bremslicht (ECD-Bremsung)
";
CM_ SG_ 1137 LH_Aussenlicht_def "Aussenlicht kann nicht mehr korrekt angesteuert werden (EEPROM Codierung kann nicht mehr ausgelesen werden)
";
CM_ SG_ 1137 LH_Standlicht_H_aktiv "Standlicht hinten
";
CM_ SG_ 1137 LH_Parklicht_HL_aktiv "Parklicht hinten links
";
CM_ SG_ 1137 LH_Parklicht_HR_aktiv "Parklicht hinten rechts
";
CM_ SG_ 1137 LH_Bremslicht_H_aktiv "Bremslicht hinten
";
CM_ SG_ 1137 LH_Nebelschluss_aktiv "Nebelschlusslicht
";
CM_ SG_ 1137 LH_Rueckfahrlicht_aktiv "Rueckfahrlicht
";
CM_ SG_ 1137 LH_Blinker_HL_akt "Blinker hinten links
";
CM_ SG_ 1137 LH_Blinker_HR_akt "Blinker hinten rechts
";
CM_ SG_ 1137 LH_Blinker_li_def "Fehlerstatus Blinker hinten links
";
CM_ SG_ 1137 LH_Bremsl_li_def "Fehlerstatus Bremslicht hinten links (Detektion Einzelausfall)
";
CM_ SG_ 1137 LH_Schlusslicht_li_def "Fehlererkennung Schlusslicht hinten links
";
CM_ SG_ 1137 LH_Rueckf_li_def "Fehlererkennung Rückfahrlicht hinten links
";
CM_ SG_ 1137 LH_Nebel_li_def "Fehlererkennung Nebelschlusslicht hinten links
";
CM_ SG_ 1137 LH_Schluss_Brems_li_def "Konfiguration SL+ BRL + PL links und SL+ BRL  links
";
CM_ SG_ 1137 LH_Schluss_Nebel_li_def "Konfiguration SL + NSL links oder SL + NSL + PL links
";
CM_ SG_ 1137 LH_SL_BRL_BLK_li_def "Konfiguration SL + BRL + BLK links oder SL + BRL + BLK + PL links
";
CM_ SG_ 1137 LH_Brems_Blk_li_def "Konfiguration BRL + BLK links
";
CM_ SG_ 1137 LH_Blinker_re_def "Fehlerstatus Blinker hinten rechts
";
CM_ SG_ 1137 LH_Bremsl_re_def "Fehlerstatus Bremslicht hinten rechts  (Detektion Einzelausfall)
";
CM_ SG_ 1137 LH_Schlusslicht_re_def "Fehlererkennung Schlusslicht hinten rechts
";
CM_ SG_ 1137 LH_Rueckf_re_def "Fehlererkennung Rückfahrlicht hinten rechts
";
CM_ SG_ 1137 LH_Nebel_re_def "Fehlererkennung Nebelschlusslicht hinten rechts
";
CM_ SG_ 1137 LH_Schluss_Brems_re_def "Konfiguration SL+ BRL + PL rechts und SL+ BRL  rechts
";
CM_ SG_ 1137 LH_Schluss_Nebel_re_def "Konfiguration SL + NSL rechts oder SL + NSL + PL rechts
";
CM_ SG_ 1137 LH_SL_BRL_BLK_re_def "Konfiguration SL + BRL + BLK rechts oder SL + BRL + BLK + PL rechts
";
CM_ SG_ 1137 LH_Brems_Blk_re_def "Konfiguration BRL + BLK rechts
";
CM_ SG_ 1137 LH_Kennzl_def "Fehlerstatus Kennzeichenbeleuchtung hinten
";
CM_ SG_ 1137 LH_3_Bremsl_def "Fehlerstatus 3. Bremsleuchte
";
CM_ SG_ 1137 LH_Nebel_mi_def "Fehlererkennung Nebelschlusslicht hinten Mitte


";
CM_ SG_ 1137 LH_Rueckf_mi_def "Fehlererkennung Rückfahrlicht Mitte
";
CM_ SG_ 1137 LH_Bremsl_li_ges_def "Fehlerstatus Bremslicht hinten links (Detektion Totalausfall)
";
CM_ SG_ 1137 LH_Bremsl_re_ges_def "Fehlerstatus Bremslicht hinten links (Detektion Totalausfall)
";
CM_ BO_ 267 "Botschaft vom Lenkstockschalter, enthält Information zur Bedienung der GRA und ACC, sowie MFL-Tasten zum Getriebe für TipTronic.";
CM_ SG_ 267 LS_01_CHK "Bildung der CHK: XOR Byte2 XOR Byte 3 ... XOR Byte n  XOR CHK-Endwert  = CHK

Ab B8 ist CHK-Endwert abhängig vom CAN-ID: CHK-Endwert = MSB XOR LSB
MSB: High-Byte des Identifiers der CAN-Botschaft
LSB: Low-Byte des Identifiers der CAN-Botschaft";
CM_ SG_ 267 LS_Abbrechen "GRA : aus mit speichern
ACC : Soft aus";
CM_ SG_ 267 LS_Limiter "Limiter setzen";
CM_ SG_ 267 LS_Tip_Setzen "ACC : Tippschalter Set";
CM_ SG_ 267 LS_Tip_Hoch "GRA : Tip Up
ACC : Tip Up";
CM_ SG_ 267 LS_Tip_Runter "GRA : Tip Down
ACC : Tip Down";
CM_ SG_ 267 LS_Tip_Wiederaufnahme "ACC : Tippschalter Wiederaufnahme";
CM_ SG_ 267 LS_Verstellung_Zeitluecke "Verstellung der Zeitlücke für ACC

DIST -1 = Zeitluecke um 1 Stufe kleiner
DIST +1 = Zeitluecke um 1 Stufe groeßer";
CM_ SG_ 267 MFL_Tip_Down "Tiptronic Tasten vom MFL für Getriebe

0x0 = kein Tip_Down
0x1 = Tip_Down";
CM_ SG_ 267 MFL_Tip_Up "Tiptronic Tasten vom MFL für Getriebe

0x0 = kein Tip_Up
0x1 = Tip_Up";
CM_ SG_ 267 LS_Fehler "0 = in Ordnung
1 = Fehler Bedienteil";
CM_ SG_ 134 LWI_01_CHK "Bildung der CHK:

XOR Byte2 XOR Byte 3 ... XOR Byte n  XOR CHK-Endwert  = CHK

Ab B8 ist CHK-Endwert abhängig vom CAN-ID: CHK-Endwert = MSB XOR LSB
MSB: High-Byte des Identifiers der CAN-Botschaft
LSB: Low-Byte des Identifiers der CAN-Botschaft";
CM_ SG_ 134 LWI_QBit_Sub_Daten "Im B8 gilt die Signalspezifikation: LAH 8K0953B";
CM_ SG_ 134 LWI_QBit_Lenkradwinkel "Ab B8 wird es möglich sein ungenaue Werte des Lenkradwinkels zu detektieren, und dem Empfänger mitzuteilen. Das QBit wird auch bei nicht abgeglichenem Lenkradwinkelsensor gesetzt";
CM_ SG_ 134 LWI_Lenkradwinkel "Wertebereich = +/- 800 Grad
Auflösung = 0,1 Grad
ACHTUNG: spezifizierte Interne Auflösung des Sensors beträgt aber nur Schrittweite 0,5 Grad!

Im B8 gilt die Signalspezifikation: LAH 8K0953B";
CM_ SG_ 134 LWI_VZ_Lenkradwinkel "Vorzeichen Lenkradwinkel gemäss DIN70000;

Nullstellung = +0";
CM_ SG_ 134 LWI_VZ_Lenkradw_Geschw "Vorzeichen Lenkradwinkelgeschwindigkeit gemäss DIN70000; ";
CM_ SG_ 134 LWI_Lenkradw_Geschw "Wertebereich = +/- 2500 Grad/s
Auflösung = 5 Grad/s

Im B8 gilt die Signalspezifikation: LAH 8K0953B ";
CM_ SG_ 134 LWI_Sub_Daten "Verschlüsseltes Datenpaket vom Sub-Rechner des LWS, Verwendung nur durch SCU und ESP_ADS
Verwendung gemäß 'Sicherheitsanforderungen an Empfängersteuergeräte'

Im B8 gilt die Signalspezifikation: LAH 8K0953B";
CM_ SG_ 134 LWI_01_CRC "CRC8 nach Polynom C2";
CM_ SG_ 917 AFS_Lampe "Status der Fehlerlampe: aktuell anliegender Fehlerzustand des dynamischen oder statischen Kurvenlichtes";
CM_ SG_ 917 LWR_Lampe "Status der Fehlerlampe: aktuell anliegender Fehlerzustand";
CM_ SG_ 917 AFS_Fehlertext "Fehlertext wird im Kombi angezeigt (z.Zt nur bei VW)";
CM_ SG_ 917 AFS_LED_Blinkmode "Lampe soll im Warnfall mit 1Hz blinken, wenn das Bit gesetzt ist (z.Zt nur bei VW)";
CM_ SG_ 917 LWR_Touristenmodus_aktiv "Über MMI sendet BCM1 eine Anforderung Touristenmodus an die LWR. Diese sendet als Rückmeldung an BCM1, dass der Touristenmodus aktiv geschaltet wurde";
CM_ SG_ 917 AFS_Sollwert_LD_EVG "100 % entsprechen 35 Watt. Die Last schaltet nur das ILM

";
CM_ SG_ 917 LWR_Pos_Schrittmotor "Position des Aktuators in Prozent des maximalen Stellweges; vor dem Initialisierungslauf (Motorstart) wird der Initwert ausgegeben:
0% : tiefste Stellung (auf Block) des Schrittmotors;
100% : maximaler Verstellweg des Schrittmotors (nicht die Grenze de";
CM_ SG_ 917 LWR_Hoehenwert_VL "Aktueller Höhensensorwert Vorne Links

0x7F = 0 mm";
CM_ SG_ 917 LWR_Hoehenwert_HL "Aktueller Höhensensorwert Hinten Links

0x7F = 0 mm
";
CM_ SG_ 917 AFS_Ersatzlicht_Links "Bei aktivierter Ersatzlichtfunktion wird das Abblendlicht ausgeschaltet und eine Ersatzlichtquelle eingeschaltet (z.Zt. B7)";
CM_ SG_ 917 AFS_Ersatzlicht_Rechts "Bei aktivierter Ersatzlichtfunktion wird das Abblendlicht ausgeschaltet und eine Ersatzlichtquelle eingeschaltet (z.Zt. B7)";
CM_ SG_ 917 LWR_AFS_Grundeinstellung "Grundeinstellung des Abblendlichtes am Lichteinstellkasten im Service oder Bandende mit Tester erfolgt! (auch für das dynamische Kurvernlicht)";
CM_ SG_ 917 LWR_AFS_Parametrisierung "Parametrisierung wählt die Fahrzeugvariante und die AFS-Variante aus";
CM_ SG_ 917 LWR_Initialisierungslauf "Initialisierungslauf der Schrittmotoren, erfolgt defaultmäßig beim Motorstart";
CM_ SG_ 917 LWR_Sicherheitsposition "LWR Sicherheitsposition beider Scheinwerfers";
CM_ SG_ 917 LWR_Modus "Schnelle oder langsame Regelart der LWR";
CM_ SG_ 917 LWR_KD_Fehler "Bei gesetztem Bit ist mindestens ein Kundendienstfehler eingetragen";
CM_ SG_ 128 Motor_01_CHK "Bildung der CHK:

XOR Byte2 XOR Byte 3 ... XOR Byte n  XOR CHK-Endwert  = CHK

Ab B8 ist CHK-Endwert abhängig vom CAN-ID: CHK-Endwert = MSB XOR LSB
MSB: High-Byte des Identifiers der CAN-Botschaft
LSB: Low-Byte des Identifiers der CAN-Botschaft";
CM_ SG_ 128 MO_Mom_o_ex "Achtung:
Einheitenloser CAN-Wert.
Faktor in MO_Faktor_Momente in Motor_Code_01 beachten!

Indiziertes Motormoment ohne externe Eingriffe (ASR, MSR, Getriebe ...) aber inklusive integrierter GRA";
CM_ SG_ 128 MO_Mom_m_ex "Achtung:
Einheitenloser CAN-Wert.
Faktor in MO_Faktor_Momente in Motor_Code_01 beachten!

Indiziertes Motormoment, d.h. idealisiertes berechnetes Moment ohne mechanische Verluste, aber mit externen Eingriffen.";
CM_ SG_ 128 MO_Mom_Verlust "Achtung:
Einheitenloser CAN-Wert.
Faktor in MO_Faktor_Momente in Motor_Code_01 beachten!

Beinhaltet z.Zt. Reibung vom Motor und Klimakompressor, beim TDI z.T. auch die Generatorverluste";
CM_ SG_ 128 MO_Mom_Begrenzung "Achtung:
Einheitenloser CAN-Wert.
Faktor in MO_Faktor_Momente in Motor_Code_01 beachten!

Inneres maximal mögliches Moment bei einer Drehzahl (z.B. Rauchbegrenzung oder Fehlerfall)";
CM_ SG_ 128 MO_Mom_Fahrerwunsch "Achtung:
Einheitenloser CAN-Wert.
Faktor in MO_Faktor_Momente in Motor_Code_01 beachten!

Moment vor Filter, nutzbar zur Zug- / Schuberkennung beim Getriebe (beim Diesel identisch mit innerem Moment ohne externe Eingriffe)";
CM_ SG_ 128 MO_Kickdown "Es gilt: Signalspec MO_Kickdown v1.0";
CM_ SG_ 128 MO_KD_Fehler "Kundendienstfehlerspeicherbit";
CM_ SG_ 129 Motor_02_CHK "Bildung der CHK:

XOR Byte2 XOR Byte 3 ... XOR Byte n  XOR CHK-Endwert  = CHK

Ab B8 ist CHK-Endwert abhängig vom CAN-ID: CHK-Endwert = MSB XOR LSB
MSB: High-Byte des Identifiers der CAN-Botschaft
LSB: Low-Byte des Identifiers der CAN-Botschaft";
CM_ SG_ 129 MO_Mom_ZWR "Minimales Motormoment bei Zündwinkelrücknahme.

Achtung:
Einheitenloser CAN-Wert.
Faktor in MO_Faktor_Momente in Motor_Code_01 beachten!";
CM_ SG_ 129 MO_Mom_Soll "Achtung:
Einheitenloser CAN-Wert.
Faktor in MO_Faktor_Momente in Motor_Code_01 beachten!

Sollmoment ohne P und D Anteil des Leerlaufreglers, ohne Antiruckelfunktion und ohne Getriebeeingriff";
CM_ SG_ 129 MO_Mom_Ist "Achtung:
Einheitenloser CAN-Wert.
Faktor in MO_Faktor_Momente in Motor_Code_01 beachten!

Istmoment ohne P und D Anteil des Leerlaufreglers, ohne Antiruckelfunktion und ohne Getriebeeingriff";
CM_ SG_ 129 MO_Momentenintegral "100 %  entspricht volle Verfügbarkeit aktuell vorhanden. 0 % entspricht Integral bis Limit gefüllt, erhöhender Eingriff kann aktuell nicht berücksichtigt werden oder erhöhender Eingriff ist in diesem Projekt nicht möglich (applikativ deaktiviert) oder auf";
CM_ SG_ 261 Motor_03_CHK "Bildung der CHK:

XOR Byte2 XOR Byte 3 ... XOR Byte n  XOR CHK-Endwert  = CHK

Ab B8 ist CHK-Endwert abhängig vom CAN-ID: CHK-Endwert = MSB XOR LSB
MSB: High-Byte des Identifiers der CAN-Botschaft
LSB: Low-Byte des Identifiers der CAN-Botschaft";
CM_ SG_ 261 MO_QBit_Fahrpedalwerte_01 "QBit für beide Fahrpedalwerte des Motors (Fahrpedalrohsignal für ESP, EPB, ACC; Fahrpedalwert für Getriebe)";
CM_ SG_ 261 MO_QBit_Motormomente "Ungenaue Momentenangaben, weil die Momente aus Ersatzwerten berechnet wurden (z.B. HFM ausgefallen). Qualifizierungsbit für die Motormomente.";
CM_ SG_ 261 MO_Drehzahl_01 "Im Fehlerfall wird die Motordrehzahl über die Nockenwellendrehzahl als Ersatzgrösse ausgegeben";
CM_ SG_ 261 MO_Moment_im_Leerlauf "Achtung:
Einheitenloser CAN-Wert.
Faktor in MO_Faktor_Momente in Motor_Code_01 beachten!

Motorbetriebszustand ist Leerlauf, keine Momentenerhöhung durch Fahrpedal, ACC, GRA+";
CM_ SG_ 261 MO_Interlock "Der Interlockschalter (= Kupplung komplett getreten) muß beim Handschalter betätigt sein, damit ein Motorstart erlaubt ist";
CM_ SG_ 261 MO_BLS "Ungefiltertes Rohsignal des Bremslichtschalters, nur wenn HW-Eingang bestückt und ausgewertet wird. Bei Motoren ohne genutzten HW-Eingang wird kein Ersatzwert (bspw. SW-Signal über CAN) ausgegeben!
Bei AUDI muss das Signal wg. Bremslichtfunktion immer be";
CM_ SG_ 261 MO_Fahrer_bremst "Redundante Bremsinformation vom Motor. Im B8 wird in diesem Bit der Wert der ESP-CAN-Information 'ESP_Fahrer_bremst' ausgegeben.";
CM_ SG_ 261 MO_Konsistenz_Bremsped "Siehe 'Funktionsspezifikation Bremslichtinfo B8'";
CM_ SG_ 261 MO_Kuppl_schalter "Nur Handschalter; aktiv, wenn Schalter verbaut; sonst konstant auf '0' gesetzt; Bit wird gesetzt, wenn Kupplungspedal betätigt wird (Kupplungsschalter hoch), Triebstrang kann noch eingekuppelt sein.";
CM_ SG_ 261 MO_Timeout_ESP "500 ms Timeout auf Bremsen-Botschaft ist >= 1 mal aufgelaufen, Löschen des Bits nach Neustart (KL15).";
CM_ SG_ 261 MO_Motor_laeuft "Es gilt: Signalspec MO_Motor_laeuft v1.0

Dieses Bit signalisiert, dass der Motor autark läuft und mechanisch belastbar ist. Das Bit wird abhängig von den Umgebungsbedingungen gesetzt, so kann in grosser Höhe (Gebirge) trotz erhöhter Drehzahl der Motor ";
CM_ SG_ 261 MO_Solldrehz_Leerlauf "Leerlaufsolldrehzahl, die im Motor eingestellt ist. Der Motor paßt aufgrund der Anforderung von anderen
Steuergeräten seine Leerlaufsolldrehzahl an, bspw. Kat-Heizen, Anforderung vom Getriebe etc.";
CM_ SG_ 261 MO_Fahrpedalrohwert_01 "Stellung des Fahrpedales (Rohwert, ohne Überlagerung durch GRA-Eingriffe etc.)";
CM_ SG_ 261 MO_erste_Ungenauschwelle "Zusätzliche Ungenauigkeit (zur Grundungenauigkeit). Motormomente ungenau >8% (kleinste Ungenauschwelle)";
CM_ SG_ 261 MO_Stressfaktor "Berücksichtigung von Höhe und Ansauglufttemperatur im aktuellen Betriebspunkt. Berücksichtigung bei Berechnung der ACC-Sollbeschleunigung. Fehlerwert existiert nicht, 0x3F ist gültiger Wert!

100%: kein Stress (Motor verfügt über das ganze Moment, z.B. ";
CM_ SG_ 263 MO_Anzeigedrehz "Optimierte Anzeigedrehzahl wegen sportlicherem Drehzahlmesser im Kombi. ";
CM_ SG_ 263 MO_Ladedruck "Zur Anzeige im Kombi, z.Zt. nur Porsche Colorado und PQ35 Biturbo, ab B8 Vorhalt";
CM_ SG_ 263 MO_KVS "Motorsteuergerätinterner Verbrauchszähler, der vom Kombi zyklisch ausgelesen wird, um die Einspritzmenge zur Verbrauchsmessung aufzusummieren; aus diesem Zählerstand werden Momentan- und Durchschnittsverbrauch berechnet; das Überlauf-Bit ist zu berücksich";
CM_ SG_ 263 MO_KVS_Ueberlauf "Der motorsteuergeräteinterne Verbrauchszähler ist mindestens einmal übergelaufen. Dieses Bit wird genutzt, um erkennen zu können, daß das Motorsteuergerät aus dem Reset-Zustand hochläuft.";
CM_ SG_ 782 Motor_05_CHK "Bildung der CHK:

XOR Byte2 XOR Byte 3 ... XOR Byte n  XOR CHK-Endwert  = CHK

Ab B8 ist CHK-Endwert abhängig vom CAN-ID: CHK-Endwert = MSB XOR LSB
MSB: High-Byte des Identifiers der CAN-Botschaft
LSB: Low-Byte des Identifiers der CAN-Botschaft";
CM_ SG_ 782 MO_Klima_Eingr "Eingriffe des Motor bei der Klima";
CM_ SG_ 782 MO_Status_Normalbetrieb "Das Motorsteuergerät sendet das Informationsbit, wenn die Initialisierungsphase des Steuergerätes abgeschlossen ist. Zusätzlich muss die Klemme 15 eingeschalten sein und eine applizierbare Mindestdrehzahlschwelle (Kennlinie in Abh. von der Kühlwassertempe";
CM_ SG_ 782 MO_Schaltbeeinfl_Leistungsbegr "Schaltbeeinflussung an das Getriebe wegen Leistungsbegrenzung";
CM_ SG_ 782 MO_Schaltbeeinfl_Partikelfilter "Schaltbeeinflussung an das Getriebe wegen Partikelfilter-Regeneration
";
CM_ SG_ 782 MO_Prio_MIN_Wunschdrehzahl "Motorwunschdrehzahl in Byte 7 ist als Zwang oder als Wunsch an das Getriebe zu interpretieren";
CM_ SG_ 782 MO_Freig_Anlass "Bit wird gesetzt, wenn der Motor beim Automatikstart gestartet werden darf (Motorstillstand, Emissionsmaßnahmen sind erfüllt).";
CM_ SG_ 782 MO_Aussp_Anlass "Bit wird gesetzt, wenn der Motorhochlauf ohne Anlasserunterstützung beendet werden kann oder ein Start-Timeout erreicht wurde.";
CM_ SG_ 782 MO_MAX_Wunschdrehzahl "Wenn das Bit 'MO_Prio_MIN_Wunschdrehzahl' gesetzt wird, wird hier vom Motor-SG eine wegen Partikelfilterregeneration bedingte minimale Motordrehzahl ausgegeben, die das Getriebe-SG nicht unterschreiten darf. Zum B8 Anpassung des Wertebereiches auf 9Bit we";
CM_ SG_ 782 MO_Prio_MAX_Wunschdrehzahl "Motorwunschdrehzahl in Byte 4 ist als Zwang oder als Wunsch an das Getriebe zu interpretieren";
CM_ SG_ 782 MO_Luftpfad_aktiv "Getriebeeingriff wird zusätzlich zum Zündungspfad auch über den Luftpfad umgesetzt, kommt zu B8 neu in die PL48-Getriebe";
CM_ SG_ 782 MO_v_Begrenz_Aktiv "Motor begrenzt aktuell die Geschwindigkeit des Fahrzeugs; Reaktion auf externe oder interne Anforderung";
CM_ SG_ 782 MO_v_Begrenz_Aktivierbar "Fehlerbit wird vom Motor-SG gesetzt, wenn dieses nicht in dieGeschwindigkeits-begrenzung gehen kann, ein Fehler während der v-Begrenzung auftritt oder v > v_Begrenzung - v_Delta";
CM_ SG_ 782 MO_Verbot_EKP "Es gilt: Signalspec MO_Verbot_EKP V1.1

MSG sendet Verbot der EKP-Ansteuerung an das BCM";
CM_ SG_ 782 MO_Anf_Pruefimpuls "Es gilt: Signalspec MO_Anf_Pruefimpuls v1.1

Anforderung des MSG an das BCM  zum Senden eines Prüfimpulses zur Diagnose der Wakeup-Leitung auf Dauerlow";
CM_ SG_ 782 MO_Anf_KL75 "Information wann die Kl. 75 während des Startvorgangs abgeschaltet werden soll. Umsetzung durch BCM2.";
CM_ SG_ 782 MO_Charisma_FahrPr "Aktuelles Fahrprogramm des Charisma-Teilnehmers";
CM_ SG_ 782 MO_Charisma_Status "Charisma Systemstatus des Charisma-Teilnehmers";
CM_ SG_ 782 MO_Charisma_Umschaltung "Erkennung  Umschaltaufforderung des Charisma-Teilnehmers";
CM_ SG_ 782 MO_Handshake_STH "Es gilt: Signalspec MO_Handshake v1.0

Handshake zwischen MSG und STH. Wenn das MSG die EKP aufgrund einer STH-Anforderung ansteuert und kein Fehlereintrag bzgl. EKP/KPE/NDR vorliegt, wird das Bit gesetzt.";
CM_ SG_ 782 MO_MIN_Wunschdrehzahl "Wenn das Bit 'MO_Prio_MAX_Wunschdrehzahl' gesetzt wird, wird hier vom Motor-SG eine wegen Partikelfilterregeneration bedingte minimale Motordrehzahl ausgegeben, die das Getriebe-SG nicht unterschreiten darf.";
CM_ SG_ 782 MO_Drehzahlbeeinflussung "Mit diesem Faktor kann das Motorsteuergerät die vom CVT-Getriebe einzustellende Sollmotodrehzahl beeinflussen. Im CVT-Steuergerät ist ein verbrauchsoptimales Kennfeld und ein abgasoptimiertes Kennfeld abgelegt. Mit dem Wert von 0-100% wird zwischen diesen";
CM_ SG_ 1088 WIV_Anzeige_aktiv "Peilstabsanzeigefunktion aktiv";
CM_ SG_ 1088 WIV_Oelmin_Warn "Min-Warnung";
CM_ SG_ 1088 WIV_Sensorfehler "Ölstand/Öltemperatursensor (TOG) defekt";
CM_ SG_ 1088 WIV_Schieflage "Fahrzeug steht nicht waagerecht, Messung ungenau";
CM_ SG_ 1088 WIV_Oelstand "8 Segmente zur Balkenanzeige des Ölstands";
CM_ SG_ 1088 WIV_Oelsystem_aktiv "Gesamtölsystem aktiv (entspricht Ölsensor verbaut)";
CM_ SG_ 1088 WIV_nicht_betriebswarm "Motor nicht betriebswarm, Messung ungenau";
CM_ SG_ 1088 WIV_Ueberfuell_Warn "Überfüllungswarnung";
CM_ SG_ 1088 WIV_laufender_Motor "Messung bei laufendem Motor nicht möglich";
CM_ SG_ 1088 MO_Text_MSG_Werkstatt "Über dieses Bit wird im Kombi ein Fehlerklartextanzeige erzeugt werden: 'Motorsteuergerät Werkstatt'.
";
CM_ SG_ 1088 MO_Text_Partikelfil_Reg "Über dieses Bit im Kombi wird ein Klartextanzeige erzeugt werden: 'Partikelfilter benötigt Regeneration'.
";
CM_ SG_ 1088 MO_Text_Fehler_Kraftstoffsys "Über dieses Bit wird im Kombi ein Fehlerklartextanzeige erzeugt wird: 'Fehler im Kraftstoffsystem'.
";
CM_ SG_ 1088 WIV_Oelmenge "Ölmenge zwischen Min und Max";
CM_ SG_ 1088 MO_Systemlampe "EGas Systemlampe (EPC) oder Vorglühlampe im Kombi, Kombi steuert immer gleiche
LED an, nur über Ziffernblatt wird die EPC von der Vorglühlampe differenziert";
CM_ SG_ 1088 MO_OBD2_Lampe "OBD bzw. MIL-Lampe wird vom Motorsteuergerät angesteuert, die Information in der Getriebe1 Botschaft (Byte 6, Bit 7...4) wird
vom Motorsteuergerät an das Kombi weitergereicht";
CM_ SG_ 1088 MO_Heissleuchte "Ansteuerung der Kühlwassertemperatur-Heißleuchte (Sensor nur noch am Motorsteuergerät): Temperaturschaltschwellen mit Hysterese (bei VW D1/Colorado Kombi derzeit noch nicht genutzt).";
CM_ SG_ 1088 MO_Partikel_Lampe "Partikelfilter-Lampe wird eingeschaltet";
CM_ SG_ 1088 WIV_Oelstand_nicht_vorhanden "Kein aktueller Ölstand vorhanden";
CM_ SG_ 1088 WIV_nachfuellanzeige_ein "Steuert das Aufblenden der Nachfüllanzeige im Kombi, nach Klemme 15 ein und geöffneter Motorhaube";
CM_ SG_ 1088 WIV_Check_Oil "Anzeige 'Check Oil' im Kombiinstrument ohne Aufruf durch Kunden";
CM_ SG_ 1088 WIV_Unterfuell_Warn "Unterfüllungswarnung";
CM_ SG_ 1088 MO_Tankdeckel_Lampe "Ansteuerung Tankdeckel-Warnlampe Kombiinstrument (nur Ottomotoren) z.Zt. Vorhalt VW";
CM_ SG_ 1088 MO_Text_Tankdeckelwarn "Textbit der Tankdeckelwarnung, z.Zt. Vorhalt VW";
CM_ SG_ 1088 WIV_Enable_Oeldr_Motor "Schaltet die interne Öldruckauswertung im Kombiinstrument ab und aktiviert die Auswertung des Bits 'WIV_Oeldr_Warn_Motor'";
CM_ SG_ 1088 WIV_Oeldr_Warn_Motor "Löst im Kombiinstrument die rote Prio1-Öldruckwarnung (inkl. 3xBeep) aus; die Warnauslösung erfolgt nur bei gleichzeitig gesetztem 'WIV_Enable_Oeldr_Motor'";
CM_ SG_ 1088 MO_Avus_Motorschutz "Warntexten zum Kombi für den Fall des Avus-Notlauf. Priowarnung, kann parallel mit anderen Warnungen
im Mitteldisplay angezeigt werden.";
CM_ SG_ 1600 MO_QBit_Ansaugluft_Temp "
";
CM_ SG_ 1600 MO_QBit_Kuehlmittel_Temp "
";
CM_ SG_ 1600 MO_Ansaugluft_Temp "In Fahrzeugen ohne Außentemperatur vom Kombi kann aus der Ansauglufttemperatur auf die Außentemperatur geschlossen werden. Beim SDI ist das mit einer gewissen Genauigkeit gegeben. Genutzt wird es vom ASG.";
CM_ SG_ 1600 MO_Oel_Temp "Realer Meßbereich ca. -40..150 Grad";
CM_ SG_ 1600 MO_Kuehlmittel_Temp "Kuehlmitteltemperatur";
CM_ SG_ 1600 MO_Hoeheninfo "Korrekturfaktor Höhe (1 entspricht 1013 mbar)";
CM_ SG_ 1600 MO_Kennfeldk "Die Kennfeldkühlung ist in diesem Fahrzeug verbaut und hat keinen Systemfehler";
CM_ SG_ 1600 MO_Versionsinfo "Versioninformation vom Motor zur Steuerung bei inkompatiblen KMatrix-Änderung bzw. Einführung von neuen Funktionen, die in den Empfängern verriegelt werden müssen. Freilaufender Zähler, der nach Änderungsereignis festgelegt wird. Zu jedem Ereignis wird ei";
CM_ SG_ 1600 MO_Mom_Traegheit_02 "Massenträgheit des Motors (J) in kgm²
Bei Handschaltern wird das Zweimassenschwungrad mit berücksichtigt.
Bei eingebautem Getriebesteuergerät wird nur das Motorträgheitsmoment angegeben (Ohne Anteile des Massenschwungrades).";
CM_ BO_ 135 "nur AUDI fuer Stufenautomaten: Teilweise redundant zu Motor_03";
CM_ SG_ 135 Motor_08_CHK "Bildung der CHK:

XOR Byte2 XOR Byte 3 ... XOR Byte n  XOR CHK-Endwert  = CHK

Ab B8 ist CHK-Endwert abhängig vom CAN-ID: CHK-Endwert = MSB XOR LSB
MSB: High-Byte des Identifiers der CAN-Botschaft
LSB: Low-Byte des Identifiers der CAN-Botschaft";
CM_ SG_ 135 MO_QBit_Drehzahl_02 "In Motor_08-Botschaft reduzierte Zykluszeit fuer AUDI Stufenautomaten:
Motor_03: 20ms (wird auf den D-CAN geroutet)
Motor_08: 10ms (reine A-CAN-Botschaft)";
CM_ SG_ 135 MO_QBit_Fahrpedalwerte_02 "QBit für beide Fahrpedalwerte des Motors (Fahrpedalrohsignal für ESP, EPB, ACC; Fahrpedalwert für Getriebe)

In Motor_08-Botschaft reduzierte Zykluszeit fuer AUDI Stufenautomaten:
Motor_03: 20ms (wird auf den D-CAN geroutet)
Motor_08: 10ms (reine A-C";
CM_ SG_ 135 MO_Status_Zylabschalt "Statusbit: Motor ist in Zylinderabschaltregelung:";
CM_ SG_ 135 MO_Drehzahl_02 "Im Fehlerfall wird die Motordrehzahl über die Nockenwellendrehzahl als Ersatzgrösse ausgegeben

In Motor_08-Botschaft reduzierte Zykluszeit fuer AUDI Stufenautomaten:
Motor_03: 20ms (wird auf den D-CAN geroutet)
Motor_08: 10ms (reine A-CAN-Botschaft)";
CM_ SG_ 135 MO_Fahrpedalrohwert_02 "Stellung des Fahrpedales (Rohwert, ohne Überlagerung durch GRA-Eingriffe etc.)

In Motor_08-Botschaft reduzierte Zykluszeit fuer AUDI Stufenautomaten:
Motor_03: 20ms (wird auf den D-CAN geroutet)
Motor_08: 10ms (reine A-CAN-Botschaft)";
CM_ SG_ 1607 MO_ITM_Kuehlmittel_Temp "Kuehlmitteltemperatur: Ersatzkühlmitteltemperatur für Motoren mit ITM (Thermomanagement)";
CM_ SG_ 1607 MO_E85_Sensor "Information über den E85 Gehalt (%-mass.) im Ottokraftstoff";
CM_ SG_ 1607 MO_Kraftstofffilter_Wasser "Für Schlechtkraftstoffländer wird das Wasserabscheidevolumen im Dieselkraftstofffilter mit einem  Wassersensor überwacht. Ist das Volumen erschöpft, erfolgt im Kombi eine entsprechende Anzeige.";
CM_ SG_ 1607 SCR_Systemfehler "Ansteuerung Anzeige für SCR-Systemfehler";
CM_ SG_ 1607 SCR_Inducement_Strategie "Art des Motor-Inducement-Konzepts. Abhängig von diesem Signal sind die Warntexte zwischen 'Kein Motorstart (in...km)' und 'eingeschränkte Fahrbarkeit (in ...km)' auszuwählen.";
CM_ SG_ 1607 MO_CO2_Faktor "dynamischer Umrechnungsfaktor von l in CO2";
CM_ SG_ 1607 MO_MKB_MUX "Die vier Motorkennbuchstaben werden gemultiplext in MO_MKB übertragen. Das Signal MO_MKB_MUX stellt das Steuersignal für diesen Multiplexer dar.";
CM_ SG_ 1607 MO_MKB_01 "Motorkennbuchstabe 1";
CM_ SG_ 1607 MO_MKB_02 "Motorkennbuchstabe 2";
CM_ SG_ 1607 MO_MKB_03 "Motorkennbuchstabe 3";
CM_ SG_ 1607 MO_MKB_04 "Motorkennbuchstabe 4";
BA_DEF_ BO_  "GenMsgAutoGenDsp" ENUM  "No","Yes";
BA_DEF_ BO_  "GenMsgAutoGenSnd" ENUM  "No","Yes";
BA_DEF_ BO_  "GenMsgCycleTime" INT 0 65535;
BA_DEF_ BO_  "GenMsgCycleTimeFast" INT 0 65535;
BA_DEF_ BO_  "GenMsgDelayTime" INT 0 100000;
BA_DEF_ BO_  "GenMsgILSupport" ENUM  "No","Yes";
BA_DEF_ BO_  "GenMsgNrOfRepetition" INT 0 100;
BA_DEF_ BO_  "GenMsgSendType" ENUM  "cyclicX","spontanX","cyclicIfActiveX","spontanWithDelay","cyclicAndSpontanX","cyclicAndSpontanWithDelay","spontanWithRepetition","cyclicIfActiveAndSpontanWD","cyclicIfActiveFast","cyclicWithRepeatOnDemand";
BA_DEF_ BO_  "GenMsgStartDelayTime" INT 0 100000;
BA_DEF_ BO_  "NmMessage" ENUM  "No","Yes";
BA_DEF_ BO_  "NmhMessage" ENUM  "No","Yes";
BA_DEF_ BO_  "NWM-Botschaft" ENUM  "No","Yes";
BA_DEF_ BO_  "VAGTP20_API" HEX 0 255;
BA_DEF_ BO_  "VAGTP20_DynConnection" ENUM  "No","Yes";
BA_DEF_ BO_  "VAGTP20_DynSetup" ENUM  "No","Yes";
BA_DEF_ BO_  "VAGTP20_StatConnection" ENUM  "No","Yes";
BA_DEF_ BO_  "Timeoutzeit" INT 0 1000000;
BA_DEF_ BO_  "akt_Dateninh_NM_Betr" ENUM  "No","Yes";
BA_DEF_ SG_  "GenSigAltSetting" STRING ;
BA_DEF_ SG_  "GenSigAssignSetting" STRING ;
BA_DEF_ SG_  "GenSigAutoGenDsp" ENUM  "No","Yes";
BA_DEF_ SG_  "GenSigAutoGenSnd" ENUM  "No","Yes";
BA_DEF_ SG_  "GenSigConditionalSend" STRING ;
BA_DEF_ SG_  "GenSigEnvVarType" ENUM  "int","float","undef";
BA_DEF_ SG_  "GenSigEVName" STRING ;
BA_DEF_ SG_  "GenSigInactiveValue" INT -2147483648 2147483647;
BA_DEF_ SG_  "GenSigPostIfSetting" STRING ;
BA_DEF_ SG_  "GenSigPostSetting" STRING ;
BA_DEF_ SG_  "GenSigPreIfSetting" STRING ;
BA_DEF_ SG_  "GenSigPreSetting" STRING ;
BA_DEF_ SG_  "GenSigSendType" ENUM  "Cyclic","OnWrite","OnWriteWithRepetition","OnChange","OnChangeWithRepetition","IfActive","IfActiveWithRepetition","NoSigSendType";
BA_DEF_ SG_  "GenSigStartValue" INT -2147483648 2147483647;
BA_DEF_ SG_  "NWM-WakeupAllowed" ENUM  "No","Yes";
BA_DEF_ SG_  "NMH-WakeupAllowed" ENUM  "No","Yes";
BA_DEF_ SG_  "GenSigTimeoutMsg_Motor_EDC17_003" HEX 0 2047;
BA_DEF_ SG_  "GenSigTimeoutMsg_Motor_EDC17_004" HEX 0 2047;
BA_DEF_ SG_  "GenSigTimeoutMsg_Motor_MED17_B8" HEX 0 2047;
BA_DEF_ SG_  "GenSigTimeoutMsg_Motor_MED9_B8" HEX 0 2047;
BA_DEF_ SG_  "GenSigTimeoutMsg_Motor_SIMOS8_B8" HEX 0 2047;
BA_DEF_ SG_  "GenSigTimeoutMsg_Daempfer_B8" HEX 0 2047;
BA_DEF_ SG_  "GenSigTimeoutMsg_Gateway_B8" HEX 0 2047;
BA_DEF_ SG_  "GenSigTimeoutMsg_Getriebe_AL6000" HEX 0 2047;
BA_DEF_ SG_  "GenSigTimeoutMsg_Getriebe_DL5001" HEX 0 2047;
BA_DEF_ SG_  "GenSigTimeoutMsg_Getriebe_VL3002" HEX 0 2047;
BA_DEF_ SG_  "GenSigTimeoutMsg_AFS_B8" HEX 0 2047;
BA_DEF_ SG_  "GenSigTimeoutMsg_Motor_Slave_B8" HEX 0 2047;
BA_DEF_ SG_  "GenSigTimeoutMsg_Airbag_B8" HEX 0 2047;
BA_DEF_ SG_  "GenSigTimeoutMsg_LWR_B8" HEX 0 2047;
BA_DEF_ SG_  "GenSigFuncType" ENUM  "NoFunction","MsgCounter","CRC-8","XOR","XOR-2","DatedBit","SW-Kl15","CHK","Constant","Protocol";
BA_DEF_ SG_  "GenSigSwitchedByIgnition" ENUM  "No","Yes";
BA_DEF_ SG_  "Fehlerwert" HEX 0 2147483647;
BA_DEF_ SG_  "GenSigMissingSourceValue" HEX 0 2147483647;
BA_DEF_ SG_  "SystemSignalLongSymbol" STRING ;
BA_DEF_DEF_  "GenMsgAutoGenDsp" "Yes";
BA_DEF_DEF_  "GenMsgAutoGenSnd" "Yes";
BA_DEF_DEF_  "GenMsgCycleTime" 0;
BA_DEF_DEF_  "GenMsgCycleTimeFast" 0;
BA_DEF_DEF_  "GenMsgDelayTime" 0;
BA_DEF_DEF_  "GenMsgILSupport" "";
BA_DEF_DEF_  "GenMsgNrOfRepetition" 0;
BA_DEF_DEF_  "GenMsgSendType" "cyclicX";
BA_DEF_DEF_  "GenMsgStartDelayTime" 0;
BA_DEF_DEF_  "NmMessage" "No";
BA_DEF_DEF_  "NmhMessage" "No";
BA_DEF_DEF_  "NWM-Botschaft" "No";
BA_DEF_DEF_  "VAGTP20_API" 0;
BA_DEF_DEF_  "VAGTP20_DynConnection" "No";
BA_DEF_DEF_  "VAGTP20_DynSetup" "No";
BA_DEF_DEF_  "VAGTP20_StatConnection" "No";
BA_DEF_DEF_  "Timeoutzeit" 0;
BA_DEF_DEF_  "akt_Dateninh_NM_Betr" "";
BA_DEF_DEF_  "GenSigAltSetting" "";
BA_DEF_DEF_  "GenSigAssignSetting" "";
BA_DEF_DEF_  "GenSigAutoGenDsp" "";
BA_DEF_DEF_  "GenSigAutoGenSnd" "";
BA_DEF_DEF_  "GenSigConditionalSend" "";
BA_DEF_DEF_  "GenSigEnvVarType" "undef";
BA_DEF_DEF_  "GenSigEVName" "";
BA_DEF_DEF_  "GenSigInactiveValue" 0;
BA_DEF_DEF_  "GenSigPostIfSetting" "";
BA_DEF_DEF_  "GenSigPostSetting" "";
BA_DEF_DEF_  "GenSigPreIfSetting" "";
BA_DEF_DEF_  "GenSigPreSetting" "";
BA_DEF_DEF_  "GenSigSendType" "Cyclic";
BA_DEF_DEF_  "GenSigStartValue" 0;
BA_DEF_DEF_  "NWM-WakeupAllowed" "";
BA_DEF_DEF_  "NMH-WakeupAllowed" "";
BA_DEF_DEF_  "GenSigTimeoutMsg_Motor_EDC17_003" 0;
BA_DEF_DEF_  "GenSigTimeoutMsg_Motor_EDC17_004" 0;
BA_DEF_DEF_  "GenSigTimeoutMsg_Motor_MED17_B8" 0;
BA_DEF_DEF_  "GenSigTimeoutMsg_Motor_MED9_B8" 0;
BA_DEF_DEF_  "GenSigTimeoutMsg_Motor_SIMOS8_B8" 0;
BA_DEF_DEF_  "GenSigTimeoutMsg_Daempfer_B8" 0;
BA_DEF_DEF_  "GenSigTimeoutMsg_Gateway_B8" 0;
BA_DEF_DEF_  "GenSigTimeoutMsg_Getriebe_AL6000" 0;
BA_DEF_DEF_  "GenSigTimeoutMsg_Getriebe_DL5001" 0;
BA_DEF_DEF_  "GenSigTimeoutMsg_Getriebe_VL3002" 0;
BA_DEF_DEF_  "GenSigTimeoutMsg_AFS_B8" 0;
BA_DEF_DEF_  "GenSigTimeoutMsg_Motor_Slave_B8" 0;
BA_DEF_DEF_  "GenSigTimeoutMsg_Airbag_B8" 0;
BA_DEF_DEF_  "GenSigTimeoutMsg_LWR_B8" 0;
BA_DEF_DEF_  "GenSigFuncType" "";
BA_DEF_DEF_  "GenSigSwitchedByIgnition" "";
BA_DEF_DEF_  "Fehlerwert" 0;
BA_DEF_DEF_  "GenSigMissingSourceValue" 0;
BA_DEF_DEF_  "SystemSignalLongSymbol" "";
BA_ "GenMsgCycleTime" BO_ 779 50;
BA_ "GenMsgILSupport" BO_ 779 1;
BA_ "akt_Dateninh_NM_Betr" BO_ 779 1;
BA_ "GenMsgCycleTime" BO_ 1719 1000;
BA_ "GenMsgILSupport" BO_ 1719 1;
BA_ "akt_Dateninh_NM_Betr" BO_ 1719 1;
BA_ "GenMsgCycleTime" BO_ 1720 1000;
BA_ "GenMsgILSupport" BO_ 1720 1;
BA_ "akt_Dateninh_NM_Betr" BO_ 1720 1;
BA_ "GenMsgCycleTime" BO_ 1137 100;
BA_ "GenMsgILSupport" BO_ 1137 1;
BA_ "akt_Dateninh_NM_Betr" BO_ 1137 1;
BA_ "GenMsgCycleTime" BO_ 267 100;
BA_ "GenMsgCycleTimeFast" BO_ 267 20;
BA_ "GenMsgDelayTime" BO_ 267 20;
BA_ "GenMsgILSupport" BO_ 267 1;
BA_ "GenMsgSendType" BO_ 267 5;
BA_ "akt_Dateninh_NM_Betr" BO_ 267 0;
BA_ "GenMsgCycleTime" BO_ 134 10;
BA_ "GenMsgILSupport" BO_ 134 1;
BA_ "akt_Dateninh_NM_Betr" BO_ 134 0;
BA_ "GenMsgCycleTime" BO_ 917 100;
BA_ "GenMsgILSupport" BO_ 917 1;
BA_ "akt_Dateninh_NM_Betr" BO_ 917 0;
BA_ "GenMsgCycleTime" BO_ 128 10;
BA_ "GenMsgILSupport" BO_ 128 1;
BA_ "akt_Dateninh_NM_Betr" BO_ 128 1;
BA_ "GenMsgCycleTime" BO_ 129 10;
BA_ "GenMsgILSupport" BO_ 129 1;
BA_ "akt_Dateninh_NM_Betr" BO_ 129 1;
BA_ "GenMsgCycleTime" BO_ 261 20;
BA_ "GenMsgILSupport" BO_ 261 1;
BA_ "akt_Dateninh_NM_Betr" BO_ 261 1;
BA_ "GenMsgCycleTime" BO_ 263 20;
BA_ "GenMsgILSupport" BO_ 263 1;
BA_ "akt_Dateninh_NM_Betr" BO_ 263 1;
BA_ "GenMsgCycleTime" BO_ 782 50;
BA_ "GenMsgILSupport" BO_ 782 1;
BA_ "akt_Dateninh_NM_Betr" BO_ 782 1;
BA_ "GenMsgCycleTime" BO_ 1088 100;
BA_ "GenMsgILSupport" BO_ 1088 1;
BA_ "akt_Dateninh_NM_Betr" BO_ 1088 1;
BA_ "GenMsgCycleTime" BO_ 1600 500;
BA_ "GenMsgILSupport" BO_ 1600 1;
BA_ "akt_Dateninh_NM_Betr" BO_ 1600 1;
BA_ "GenMsgCycleTime" BO_ 135 10;
BA_ "GenMsgILSupport" BO_ 135 1;
BA_ "akt_Dateninh_NM_Betr" BO_ 135 1;
BA_ "GenSigAutoGenDsp" SG_ 779 KBI_ABS_Lampe 1;
BA_ "GenSigAutoGenSnd" SG_ 779 KBI_ABS_Lampe 1;
BA_ "GenSigEnvVarType" SG_ 779 KBI_ABS_Lampe 0;
BA_ "GenSigSendType" SG_ 779 KBI_ABS_Lampe 7;
BA_ "NWM-WakeupAllowed" SG_ 779 KBI_ABS_Lampe 0;
BA_ "NMH-WakeupAllowed" SG_ 779 KBI_ABS_Lampe 0;
BA_ "GenSigAutoGenDsp" SG_ 779 KBI_ESP_Lampe 1;
BA_ "GenSigAutoGenSnd" SG_ 779 KBI_ESP_Lampe 1;
BA_ "GenSigEnvVarType" SG_ 779 KBI_ESP_Lampe 0;
BA_ "GenSigSendType" SG_ 779 KBI_ESP_Lampe 7;
BA_ "NWM-WakeupAllowed" SG_ 779 KBI_ESP_Lampe 0;
BA_ "NMH-WakeupAllowed" SG_ 779 KBI_ESP_Lampe 0;
BA_ "GenSigAutoGenDsp" SG_ 779 KBI_BKL_Lampe 1;
BA_ "GenSigAutoGenSnd" SG_ 779 KBI_BKL_Lampe 1;
BA_ "GenSigEnvVarType" SG_ 779 KBI_BKL_Lampe 0;
BA_ "GenSigSendType" SG_ 779 KBI_BKL_Lampe 7;
BA_ "NWM-WakeupAllowed" SG_ 779 KBI_BKL_Lampe 0;
BA_ "NMH-WakeupAllowed" SG_ 779 KBI_BKL_Lampe 0;
BA_ "GenSigAutoGenDsp" SG_ 779 KBI_Airbag_Lampe 1;
BA_ "GenSigAutoGenSnd" SG_ 779 KBI_Airbag_Lampe 1;
BA_ "GenSigEnvVarType" SG_ 779 KBI_Airbag_Lampe 0;
BA_ "GenSigSendType" SG_ 779 KBI_Airbag_Lampe 7;
BA_ "NWM-WakeupAllowed" SG_ 779 KBI_Airbag_Lampe 0;
BA_ "NMH-WakeupAllowed" SG_ 779 KBI_Airbag_Lampe 0;
BA_ "GenSigAutoGenDsp" SG_ 779 KBI_SILA_gueltig 1;
BA_ "GenSigAutoGenSnd" SG_ 779 KBI_SILA_gueltig 1;
BA_ "GenSigEnvVarType" SG_ 779 KBI_SILA_gueltig 0;
BA_ "GenSigSendType" SG_ 779 KBI_SILA_gueltig 7;
BA_ "NWM-WakeupAllowed" SG_ 779 KBI_SILA_gueltig 0;
BA_ "NMH-WakeupAllowed" SG_ 779 KBI_SILA_gueltig 0;
BA_ "GenSigAutoGenDsp" SG_ 779 KBI_Lenkung_Lampe 1;
BA_ "GenSigAutoGenSnd" SG_ 779 KBI_Lenkung_Lampe 1;
BA_ "GenSigSendType" SG_ 779 KBI_Lenkung_Lampe 7;
BA_ "NWM-WakeupAllowed" SG_ 779 KBI_Lenkung_Lampe 0;
BA_ "NMH-WakeupAllowed" SG_ 779 KBI_Lenkung_Lampe 0;
BA_ "GenSigAutoGenDsp" SG_ 779 KBI_Vorglueh_System_Lampe 1;
BA_ "GenSigAutoGenSnd" SG_ 779 KBI_Vorglueh_System_Lampe 1;
BA_ "GenSigSendType" SG_ 779 KBI_Vorglueh_System_Lampe 7;
BA_ "NWM-WakeupAllowed" SG_ 779 KBI_Vorglueh_System_Lampe 0;
BA_ "NMH-WakeupAllowed" SG_ 779 KBI_Vorglueh_System_Lampe 0;
BA_ "GenSigAutoGenDsp" SG_ 779 KBI_Tankwarnung 1;
BA_ "GenSigAutoGenSnd" SG_ 779 KBI_Tankwarnung 1;
BA_ "GenSigEnvVarType" SG_ 779 KBI_Tankwarnung 0;
BA_ "GenSigSendType" SG_ 779 KBI_Tankwarnung 7;
BA_ "NWM-WakeupAllowed" SG_ 779 KBI_Tankwarnung 0;
BA_ "NMH-WakeupAllowed" SG_ 779 KBI_Tankwarnung 0;
BA_ "GenSigTimeoutMsg_Motor_EDC17_003" SG_ 779 KBI_Tankwarnung 779;
BA_ "GenSigTimeoutMsg_Motor_EDC17_004" SG_ 779 KBI_Tankwarnung 779;
BA_ "GenSigTimeoutMsg_Motor_MED17_B8" SG_ 779 KBI_Tankwarnung 779;
BA_ "GenSigTimeoutMsg_Motor_SIMOS8_B8" SG_ 779 KBI_Tankwarnung 779;
BA_ "GenSigAutoGenDsp" SG_ 779 KBI_MFA_v_Einheit_01 1;
BA_ "GenSigAutoGenSnd" SG_ 779 KBI_MFA_v_Einheit_01 1;
BA_ "GenSigSendType" SG_ 779 KBI_MFA_v_Einheit_01 7;
BA_ "NWM-WakeupAllowed" SG_ 779 KBI_MFA_v_Einheit_01 0;
BA_ "NMH-WakeupAllowed" SG_ 779 KBI_MFA_v_Einheit_01 0;
BA_ "GenSigTimeoutMsg_Motor_EDC17_003" SG_ 779 KBI_MFA_v_Einheit_01 779;
BA_ "GenSigTimeoutMsg_Motor_EDC17_004" SG_ 779 KBI_MFA_v_Einheit_01 779;
BA_ "GenSigTimeoutMsg_Motor_MED17_B8" SG_ 779 KBI_MFA_v_Einheit_01 779;
BA_ "GenSigTimeoutMsg_Motor_SIMOS8_B8" SG_ 779 KBI_MFA_v_Einheit_01 779;
BA_ "GenSigAutoGenDsp" SG_ 779 KBI_im_Stellgliedtest 1;
BA_ "GenSigAutoGenSnd" SG_ 779 KBI_im_Stellgliedtest 1;
BA_ "GenSigSendType" SG_ 779 KBI_im_Stellgliedtest 7;
BA_ "NWM-WakeupAllowed" SG_ 779 KBI_im_Stellgliedtest 0;
BA_ "NMH-WakeupAllowed" SG_ 779 KBI_im_Stellgliedtest 0;
BA_ "GenSigAutoGenDsp" SG_ 779 KBI_Anzeigefehler_LDW 1;
BA_ "GenSigAutoGenSnd" SG_ 779 KBI_Anzeigefehler_LDW 1;
BA_ "GenSigSendType" SG_ 779 KBI_Anzeigefehler_LDW 7;
BA_ "NWM-WakeupAllowed" SG_ 779 KBI_Anzeigefehler_LDW 0;
BA_ "NMH-WakeupAllowed" SG_ 779 KBI_Anzeigefehler_LDW 0;
BA_ "GenSigAutoGenDsp" SG_ 779 KBI_Variante_USA 1;
BA_ "GenSigAutoGenSnd" SG_ 779 KBI_Variante_USA 1;
BA_ "GenSigSendType" SG_ 779 KBI_Variante_USA 7;
BA_ "NWM-WakeupAllowed" SG_ 779 KBI_Variante_USA 0;
BA_ "NMH-WakeupAllowed" SG_ 779 KBI_Variante_USA 0;
BA_ "GenSigAutoGenDsp" SG_ 779 KBI_Oeldruckwarnung 1;
BA_ "GenSigAutoGenSnd" SG_ 779 KBI_Oeldruckwarnung 1;
BA_ "GenSigSendType" SG_ 779 KBI_Oeldruckwarnung 7;
BA_ "NWM-WakeupAllowed" SG_ 779 KBI_Oeldruckwarnung 0;
BA_ "NMH-WakeupAllowed" SG_ 779 KBI_Oeldruckwarnung 0;
BA_ "GenSigAutoGenDsp" SG_ 779 KBI_angez_Geschw 1;
BA_ "GenSigAutoGenSnd" SG_ 779 KBI_angez_Geschw 1;
BA_ "GenSigEnvVarType" SG_ 779 KBI_angez_Geschw 1;
BA_ "GenSigSendType" SG_ 779 KBI_angez_Geschw 7;
BA_ "NWM-WakeupAllowed" SG_ 779 KBI_angez_Geschw 0;
BA_ "NMH-WakeupAllowed" SG_ 779 KBI_angez_Geschw 0;
BA_ "GenSigTimeoutMsg_Getriebe_AL6000" SG_ 779 KBI_angez_Geschw 779;
BA_ "GenSigTimeoutMsg_Getriebe_DL5001" SG_ 779 KBI_angez_Geschw 779;
BA_ "GenSigTimeoutMsg_Getriebe_VL3002" SG_ 779 KBI_angez_Geschw 779;
BA_ "GenSigTimeoutMsg_Motor_EDC17_003" SG_ 779 KBI_angez_Geschw 779;
BA_ "GenSigTimeoutMsg_Motor_EDC17_004" SG_ 779 KBI_angez_Geschw 779;
BA_ "GenSigTimeoutMsg_Motor_MED17_B8" SG_ 779 KBI_angez_Geschw 779;
BA_ "GenSigTimeoutMsg_Motor_SIMOS8_B8" SG_ 779 KBI_angez_Geschw 779;
BA_ "GenSigAutoGenDsp" SG_ 779 KBI_Einheit_Tacho 1;
BA_ "GenSigAutoGenSnd" SG_ 779 KBI_Einheit_Tacho 1;
BA_ "GenSigEnvVarType" SG_ 779 KBI_Einheit_Tacho 0;
BA_ "GenSigSendType" SG_ 779 KBI_Einheit_Tacho 7;
BA_ "NWM-WakeupAllowed" SG_ 779 KBI_Einheit_Tacho 0;
BA_ "NMH-WakeupAllowed" SG_ 779 KBI_Einheit_Tacho 0;
BA_ "GenSigTimeoutMsg_Getriebe_AL6000" SG_ 779 KBI_Einheit_Tacho 779;
BA_ "GenSigTimeoutMsg_Motor_EDC17_003" SG_ 779 KBI_Einheit_Tacho 779;
BA_ "GenSigTimeoutMsg_Motor_EDC17_004" SG_ 779 KBI_Einheit_Tacho 779;
BA_ "GenSigTimeoutMsg_Motor_MED17_B8" SG_ 779 KBI_Einheit_Tacho 779;
BA_ "GenSigTimeoutMsg_Motor_SIMOS8_B8" SG_ 779 KBI_Einheit_Tacho 779;
BA_ "GenSigAutoGenDsp" SG_ 779 KBI_Konsistenz_ACC 0;
BA_ "GenSigAutoGenSnd" SG_ 779 KBI_Konsistenz_ACC 0;
BA_ "GenSigSendType" SG_ 779 KBI_Konsistenz_ACC 7;
BA_ "NWM-WakeupAllowed" SG_ 779 KBI_Konsistenz_ACC 0;
BA_ "NMH-WakeupAllowed" SG_ 779 KBI_Konsistenz_ACC 0;
BA_ "GenSigAutoGenDsp" SG_ 779 KBI_Fehler_Anzeige_ACC 1;
BA_ "GenSigAutoGenSnd" SG_ 779 KBI_Fehler_Anzeige_ACC 1;
BA_ "GenSigSendType" SG_ 779 KBI_Fehler_Anzeige_ACC 7;
BA_ "NWM-WakeupAllowed" SG_ 779 KBI_Fehler_Anzeige_ACC 0;
BA_ "NMH-WakeupAllowed" SG_ 779 KBI_Fehler_Anzeige_ACC 0;
BA_ "GenSigAutoGenDsp" SG_ 779 KBI_Anzeigefehler_SWA 1;
BA_ "GenSigAutoGenSnd" SG_ 779 KBI_Anzeigefehler_SWA 1;
BA_ "GenSigSendType" SG_ 779 KBI_Anzeigefehler_SWA 7;
BA_ "NWM-WakeupAllowed" SG_ 779 KBI_Anzeigefehler_SWA 0;
BA_ "NMH-WakeupAllowed" SG_ 779 KBI_Anzeigefehler_SWA 0;
BA_ "GenSigAutoGenDsp" SG_ 779 KBI_KD_Fehler 1;
BA_ "GenSigAutoGenSnd" SG_ 779 KBI_KD_Fehler 1;
BA_ "GenSigEnvVarType" SG_ 779 KBI_KD_Fehler 0;
BA_ "GenSigSendType" SG_ 779 KBI_KD_Fehler 7;
BA_ "NWM-WakeupAllowed" SG_ 779 KBI_KD_Fehler 0;
BA_ "NMH-WakeupAllowed" SG_ 779 KBI_KD_Fehler 0;
BA_ "GenSigAutoGenDsp" SG_ 1719 KBI_Kilometerstand 1;
BA_ "GenSigAutoGenSnd" SG_ 1719 KBI_Kilometerstand 1;
BA_ "GenSigEnvVarType" SG_ 1719 KBI_Kilometerstand 0;
BA_ "GenSigSendType" SG_ 1719 KBI_Kilometerstand 7;
BA_ "GenSigStartValue" SG_ 1719 KBI_Kilometerstand 1048574;
BA_ "NWM-WakeupAllowed" SG_ 1719 KBI_Kilometerstand 0;
BA_ "NMH-WakeupAllowed" SG_ 1719 KBI_Kilometerstand 0;
BA_ "GenSigAutoGenDsp" SG_ 1719 KBI_Standzeit 1;
BA_ "GenSigAutoGenSnd" SG_ 1719 KBI_Standzeit 1;
BA_ "GenSigEnvVarType" SG_ 1719 KBI_Standzeit 1;
BA_ "GenSigSendType" SG_ 1719 KBI_Standzeit 7;
BA_ "NWM-WakeupAllowed" SG_ 1719 KBI_Standzeit 0;
BA_ "NMH-WakeupAllowed" SG_ 1719 KBI_Standzeit 0;
BA_ "GenSigTimeoutMsg_Getriebe_AL6000" SG_ 1719 KBI_Standzeit 1719;
BA_ "GenSigTimeoutMsg_Getriebe_DL5001" SG_ 1719 KBI_Standzeit 1719;
BA_ "GenSigTimeoutMsg_Getriebe_VL3002" SG_ 1719 KBI_Standzeit 1719;
BA_ "GenSigTimeoutMsg_Motor_EDC17_003" SG_ 1719 KBI_Standzeit 1719;
BA_ "GenSigTimeoutMsg_Motor_EDC17_004" SG_ 1719 KBI_Standzeit 1719;
BA_ "GenSigTimeoutMsg_Motor_MED17_B8" SG_ 1719 KBI_Standzeit 1719;
BA_ "GenSigTimeoutMsg_Motor_MED9_B8" SG_ 1719 KBI_Standzeit 1719;
BA_ "GenSigTimeoutMsg_Motor_SIMOS8_B8" SG_ 1719 KBI_Standzeit 1719;
BA_ "GenSigAutoGenDsp" SG_ 1719 KBI_Reset_Standzeit 1;
BA_ "GenSigAutoGenSnd" SG_ 1719 KBI_Reset_Standzeit 1;
BA_ "GenSigEnvVarType" SG_ 1719 KBI_Reset_Standzeit 0;
BA_ "GenSigSendType" SG_ 1719 KBI_Reset_Standzeit 7;
BA_ "NWM-WakeupAllowed" SG_ 1719 KBI_Reset_Standzeit 0;
BA_ "NMH-WakeupAllowed" SG_ 1719 KBI_Reset_Standzeit 0;
BA_ "GenSigTimeoutMsg_Getriebe_AL6000" SG_ 1719 KBI_Reset_Standzeit 1719;
BA_ "GenSigTimeoutMsg_Getriebe_DL5001" SG_ 1719 KBI_Reset_Standzeit 1719;
BA_ "GenSigTimeoutMsg_Getriebe_VL3002" SG_ 1719 KBI_Reset_Standzeit 1719;
BA_ "GenSigTimeoutMsg_Motor_EDC17_003" SG_ 1719 KBI_Reset_Standzeit 1719;
BA_ "GenSigTimeoutMsg_Motor_EDC17_004" SG_ 1719 KBI_Reset_Standzeit 1719;
BA_ "GenSigTimeoutMsg_Motor_MED17_B8" SG_ 1719 KBI_Reset_Standzeit 1719;
BA_ "GenSigTimeoutMsg_Motor_MED9_B8" SG_ 1719 KBI_Reset_Standzeit 1719;
BA_ "GenSigTimeoutMsg_Motor_SIMOS8_B8" SG_ 1719 KBI_Reset_Standzeit 1719;
BA_ "GenSigAutoGenDsp" SG_ 1719 KBI_Inhalt_Tank 1;
BA_ "GenSigAutoGenSnd" SG_ 1719 KBI_Inhalt_Tank 1;
BA_ "GenSigEnvVarType" SG_ 1719 KBI_Inhalt_Tank 0;
BA_ "GenSigSendType" SG_ 1719 KBI_Inhalt_Tank 7;
BA_ "NWM-WakeupAllowed" SG_ 1719 KBI_Inhalt_Tank 0;
BA_ "NMH-WakeupAllowed" SG_ 1719 KBI_Inhalt_Tank 0;
BA_ "GenSigTimeoutMsg_Motor_EDC17_003" SG_ 1719 KBI_Inhalt_Tank 1719;
BA_ "GenSigTimeoutMsg_Motor_EDC17_004" SG_ 1719 KBI_Inhalt_Tank 1719;
BA_ "GenSigTimeoutMsg_Motor_MED17_B8" SG_ 1719 KBI_Inhalt_Tank 1719;
BA_ "GenSigTimeoutMsg_Motor_MED9_B8" SG_ 1719 KBI_Inhalt_Tank 1719;
BA_ "GenSigTimeoutMsg_Motor_SIMOS8_B8" SG_ 1719 KBI_Inhalt_Tank 1719;
BA_ "GenSigAutoGenDsp" SG_ 1719 KBI_FStatus_Tank 1;
BA_ "GenSigAutoGenSnd" SG_ 1719 KBI_FStatus_Tank 1;
BA_ "GenSigEnvVarType" SG_ 1719 KBI_FStatus_Tank 0;
BA_ "GenSigSendType" SG_ 1719 KBI_FStatus_Tank 7;
BA_ "NWM-WakeupAllowed" SG_ 1719 KBI_FStatus_Tank 0;
BA_ "NMH-WakeupAllowed" SG_ 1719 KBI_FStatus_Tank 0;
BA_ "GenSigTimeoutMsg_Motor_EDC17_003" SG_ 1719 KBI_FStatus_Tank 1719;
BA_ "GenSigTimeoutMsg_Motor_EDC17_004" SG_ 1719 KBI_FStatus_Tank 1719;
BA_ "GenSigTimeoutMsg_Motor_MED17_B8" SG_ 1719 KBI_FStatus_Tank 1719;
BA_ "GenSigTimeoutMsg_Motor_MED9_B8" SG_ 1719 KBI_FStatus_Tank 1719;
BA_ "GenSigTimeoutMsg_Motor_SIMOS8_B8" SG_ 1719 KBI_FStatus_Tank 1719;
BA_ "GenSigAutoGenDsp" SG_ 1719 KBI_QBit_Aussen_Temp_gef 1;
BA_ "GenSigAutoGenSnd" SG_ 1719 KBI_QBit_Aussen_Temp_gef 1;
BA_ "GenSigEnvVarType" SG_ 1719 KBI_QBit_Aussen_Temp_gef 0;
BA_ "GenSigSendType" SG_ 1719 KBI_QBit_Aussen_Temp_gef 7;
BA_ "GenSigStartValue" SG_ 1719 KBI_QBit_Aussen_Temp_gef 1;
BA_ "NWM-WakeupAllowed" SG_ 1719 KBI_QBit_Aussen_Temp_gef 0;
BA_ "NMH-WakeupAllowed" SG_ 1719 KBI_QBit_Aussen_Temp_gef 0;
BA_ "GenSigTimeoutMsg_Getriebe_AL6000" SG_ 1719 KBI_QBit_Aussen_Temp_gef 1719;
BA_ "GenSigTimeoutMsg_Getriebe_DL5001" SG_ 1719 KBI_QBit_Aussen_Temp_gef 1719;
BA_ "GenSigTimeoutMsg_Getriebe_VL3002" SG_ 1719 KBI_QBit_Aussen_Temp_gef 1719;
BA_ "GenSigTimeoutMsg_Motor_EDC17_003" SG_ 1719 KBI_QBit_Aussen_Temp_gef 1719;
BA_ "GenSigTimeoutMsg_Motor_EDC17_004" SG_ 1719 KBI_QBit_Aussen_Temp_gef 1719;
BA_ "GenSigTimeoutMsg_Motor_MED17_B8" SG_ 1719 KBI_QBit_Aussen_Temp_gef 1719;
BA_ "GenSigTimeoutMsg_Motor_MED9_B8" SG_ 1719 KBI_QBit_Aussen_Temp_gef 1719;
BA_ "GenSigTimeoutMsg_Motor_SIMOS8_B8" SG_ 1719 KBI_QBit_Aussen_Temp_gef 1719;
BA_ "GenSigAutoGenDsp" SG_ 1719 KBI_Aussen_Temp_gef 1;
BA_ "GenSigAutoGenSnd" SG_ 1719 KBI_Aussen_Temp_gef 1;
BA_ "GenSigEnvVarType" SG_ 1719 KBI_Aussen_Temp_gef 1;
BA_ "GenSigSendType" SG_ 1719 KBI_Aussen_Temp_gef 7;
BA_ "GenSigStartValue" SG_ 1719 KBI_Aussen_Temp_gef 254;
BA_ "NWM-WakeupAllowed" SG_ 1719 KBI_Aussen_Temp_gef 0;
BA_ "NMH-WakeupAllowed" SG_ 1719 KBI_Aussen_Temp_gef 0;
BA_ "GenSigTimeoutMsg_Getriebe_AL6000" SG_ 1719 KBI_Aussen_Temp_gef 1719;
BA_ "GenSigTimeoutMsg_Getriebe_DL5001" SG_ 1719 KBI_Aussen_Temp_gef 1719;
BA_ "GenSigTimeoutMsg_Getriebe_VL3002" SG_ 1719 KBI_Aussen_Temp_gef 1719;
BA_ "GenSigTimeoutMsg_Motor_EDC17_003" SG_ 1719 KBI_Aussen_Temp_gef 1719;
BA_ "GenSigTimeoutMsg_Motor_EDC17_004" SG_ 1719 KBI_Aussen_Temp_gef 1719;
BA_ "GenSigTimeoutMsg_Motor_MED17_B8" SG_ 1719 KBI_Aussen_Temp_gef 1719;
BA_ "GenSigTimeoutMsg_Motor_MED9_B8" SG_ 1719 KBI_Aussen_Temp_gef 1719;
BA_ "GenSigTimeoutMsg_Motor_SIMOS8_B8" SG_ 1719 KBI_Aussen_Temp_gef 1719;
BA_ "GenSigAutoGenDsp" SG_ 1720 KBI_Reifenumfang 1;
BA_ "GenSigAutoGenSnd" SG_ 1720 KBI_Reifenumfang 1;
BA_ "GenSigEnvVarType" SG_ 1720 KBI_Reifenumfang 0;
BA_ "GenSigSendType" SG_ 1720 KBI_Reifenumfang 7;
BA_ "NWM-WakeupAllowed" SG_ 1720 KBI_Reifenumfang 0;
BA_ "NMH-WakeupAllowed" SG_ 1720 KBI_Reifenumfang 0;
BA_ "GenSigTimeoutMsg_Getriebe_AL6000" SG_ 1720 KBI_Reifenumfang 1720;
BA_ "GenSigTimeoutMsg_Getriebe_DL5001" SG_ 1720 KBI_Reifenumfang 1720;
BA_ "GenSigTimeoutMsg_Getriebe_VL3002" SG_ 1720 KBI_Reifenumfang 1720;
BA_ "GenSigAutoGenDsp" SG_ 1137 Licht_hinten_01_BZ 1;
BA_ "GenSigAutoGenSnd" SG_ 1137 Licht_hinten_01_BZ 1;
BA_ "GenSigEnvVarType" SG_ 1137 Licht_hinten_01_BZ 0;
BA_ "GenSigSendType" SG_ 1137 Licht_hinten_01_BZ 7;
BA_ "NWM-WakeupAllowed" SG_ 1137 Licht_hinten_01_BZ 0;
BA_ "NMH-WakeupAllowed" SG_ 1137 Licht_hinten_01_BZ 0;
BA_ "GenSigTimeoutMsg_Motor_EDC17_003" SG_ 1137 Licht_hinten_01_BZ 1137;
BA_ "GenSigTimeoutMsg_Motor_EDC17_004" SG_ 1137 Licht_hinten_01_BZ 1137;
BA_ "GenSigTimeoutMsg_Motor_MED17_B8" SG_ 1137 Licht_hinten_01_BZ 1137;
BA_ "GenSigTimeoutMsg_Motor_SIMOS8_B8" SG_ 1137 Licht_hinten_01_BZ 1137;
BA_ "GenSigAutoGenDsp" SG_ 1137 BCM2_Bremsl_durch_ECD 1;
BA_ "GenSigAutoGenSnd" SG_ 1137 BCM2_Bremsl_durch_ECD 1;
BA_ "GenSigEnvVarType" SG_ 1137 BCM2_Bremsl_durch_ECD 0;
BA_ "GenSigSendType" SG_ 1137 BCM2_Bremsl_durch_ECD 7;
BA_ "NWM-WakeupAllowed" SG_ 1137 BCM2_Bremsl_durch_ECD 0;
BA_ "NMH-WakeupAllowed" SG_ 1137 BCM2_Bremsl_durch_ECD 0;
BA_ "GenSigTimeoutMsg_Motor_EDC17_003" SG_ 1137 BCM2_Bremsl_durch_ECD 1137;
BA_ "GenSigTimeoutMsg_Motor_EDC17_004" SG_ 1137 BCM2_Bremsl_durch_ECD 1137;
BA_ "GenSigTimeoutMsg_Motor_MED17_B8" SG_ 1137 BCM2_Bremsl_durch_ECD 1137;
BA_ "GenSigTimeoutMsg_Motor_SIMOS8_B8" SG_ 1137 BCM2_Bremsl_durch_ECD 1137;
BA_ "GenSigAutoGenDsp" SG_ 1137 LH_Aussenlicht_def 1;
BA_ "GenSigAutoGenSnd" SG_ 1137 LH_Aussenlicht_def 1;
BA_ "GenSigEnvVarType" SG_ 1137 LH_Aussenlicht_def 0;
BA_ "GenSigSendType" SG_ 1137 LH_Aussenlicht_def 7;
BA_ "NWM-WakeupAllowed" SG_ 1137 LH_Aussenlicht_def 0;
BA_ "NMH-WakeupAllowed" SG_ 1137 LH_Aussenlicht_def 0;
BA_ "GenSigAutoGenDsp" SG_ 1137 LH_Standlicht_H_aktiv 1;
BA_ "GenSigAutoGenSnd" SG_ 1137 LH_Standlicht_H_aktiv 1;
BA_ "GenSigEnvVarType" SG_ 1137 LH_Standlicht_H_aktiv 0;
BA_ "GenSigSendType" SG_ 1137 LH_Standlicht_H_aktiv 7;
BA_ "NWM-WakeupAllowed" SG_ 1137 LH_Standlicht_H_aktiv 0;
BA_ "NMH-WakeupAllowed" SG_ 1137 LH_Standlicht_H_aktiv 0;
BA_ "GenSigAutoGenDsp" SG_ 1137 LH_Parklicht_HL_aktiv 1;
BA_ "GenSigAutoGenSnd" SG_ 1137 LH_Parklicht_HL_aktiv 1;
BA_ "GenSigEnvVarType" SG_ 1137 LH_Parklicht_HL_aktiv 0;
BA_ "GenSigSendType" SG_ 1137 LH_Parklicht_HL_aktiv 7;
BA_ "NWM-WakeupAllowed" SG_ 1137 LH_Parklicht_HL_aktiv 0;
BA_ "NMH-WakeupAllowed" SG_ 1137 LH_Parklicht_HL_aktiv 0;
BA_ "GenSigAutoGenDsp" SG_ 1137 LH_Parklicht_HR_aktiv 1;
BA_ "GenSigAutoGenSnd" SG_ 1137 LH_Parklicht_HR_aktiv 1;
BA_ "GenSigEnvVarType" SG_ 1137 LH_Parklicht_HR_aktiv 0;
BA_ "GenSigSendType" SG_ 1137 LH_Parklicht_HR_aktiv 7;
BA_ "NWM-WakeupAllowed" SG_ 1137 LH_Parklicht_HR_aktiv 0;
BA_ "NMH-WakeupAllowed" SG_ 1137 LH_Parklicht_HR_aktiv 0;
BA_ "GenSigAutoGenDsp" SG_ 1137 LH_Bremslicht_H_aktiv 1;
BA_ "GenSigAutoGenSnd" SG_ 1137 LH_Bremslicht_H_aktiv 1;
BA_ "GenSigEnvVarType" SG_ 1137 LH_Bremslicht_H_aktiv 0;
BA_ "GenSigSendType" SG_ 1137 LH_Bremslicht_H_aktiv 7;
BA_ "NWM-WakeupAllowed" SG_ 1137 LH_Bremslicht_H_aktiv 0;
BA_ "NMH-WakeupAllowed" SG_ 1137 LH_Bremslicht_H_aktiv 0;
BA_ "GenSigAutoGenDsp" SG_ 1137 LH_Nebelschluss_aktiv 1;
BA_ "GenSigAutoGenSnd" SG_ 1137 LH_Nebelschluss_aktiv 1;
BA_ "GenSigEnvVarType" SG_ 1137 LH_Nebelschluss_aktiv 0;
BA_ "GenSigSendType" SG_ 1137 LH_Nebelschluss_aktiv 7;
BA_ "NWM-WakeupAllowed" SG_ 1137 LH_Nebelschluss_aktiv 0;
BA_ "NMH-WakeupAllowed" SG_ 1137 LH_Nebelschluss_aktiv 0;
BA_ "GenSigAutoGenDsp" SG_ 1137 LH_Rueckfahrlicht_aktiv 1;
BA_ "GenSigAutoGenSnd" SG_ 1137 LH_Rueckfahrlicht_aktiv 1;
BA_ "GenSigEnvVarType" SG_ 1137 LH_Rueckfahrlicht_aktiv 0;
BA_ "GenSigSendType" SG_ 1137 LH_Rueckfahrlicht_aktiv 7;
BA_ "NWM-WakeupAllowed" SG_ 1137 LH_Rueckfahrlicht_aktiv 0;
BA_ "NMH-WakeupAllowed" SG_ 1137 LH_Rueckfahrlicht_aktiv 0;
BA_ "GenSigAutoGenDsp" SG_ 1137 LH_Blinker_HL_akt 1;
BA_ "GenSigAutoGenSnd" SG_ 1137 LH_Blinker_HL_akt 1;
BA_ "GenSigEnvVarType" SG_ 1137 LH_Blinker_HL_akt 0;
BA_ "GenSigSendType" SG_ 1137 LH_Blinker_HL_akt 7;
BA_ "NWM-WakeupAllowed" SG_ 1137 LH_Blinker_HL_akt 0;
BA_ "NMH-WakeupAllowed" SG_ 1137 LH_Blinker_HL_akt 0;
BA_ "GenSigAutoGenDsp" SG_ 1137 LH_Blinker_HR_akt 1;
BA_ "GenSigAutoGenSnd" SG_ 1137 LH_Blinker_HR_akt 1;
BA_ "GenSigEnvVarType" SG_ 1137 LH_Blinker_HR_akt 0;
BA_ "GenSigSendType" SG_ 1137 LH_Blinker_HR_akt 7;
BA_ "NWM-WakeupAllowed" SG_ 1137 LH_Blinker_HR_akt 0;
BA_ "NMH-WakeupAllowed" SG_ 1137 LH_Blinker_HR_akt 0;
BA_ "GenSigAutoGenDsp" SG_ 1137 LH_Blinker_li_def 1;
BA_ "GenSigAutoGenSnd" SG_ 1137 LH_Blinker_li_def 1;
BA_ "GenSigEnvVarType" SG_ 1137 LH_Blinker_li_def 0;
BA_ "GenSigSendType" SG_ 1137 LH_Blinker_li_def 7;
BA_ "NWM-WakeupAllowed" SG_ 1137 LH_Blinker_li_def 0;
BA_ "NMH-WakeupAllowed" SG_ 1137 LH_Blinker_li_def 0;
BA_ "GenSigAutoGenDsp" SG_ 1137 LH_Bremsl_li_def 1;
BA_ "GenSigAutoGenSnd" SG_ 1137 LH_Bremsl_li_def 1;
BA_ "GenSigEnvVarType" SG_ 1137 LH_Bremsl_li_def 0;
BA_ "GenSigSendType" SG_ 1137 LH_Bremsl_li_def 7;
BA_ "NWM-WakeupAllowed" SG_ 1137 LH_Bremsl_li_def 0;
BA_ "NMH-WakeupAllowed" SG_ 1137 LH_Bremsl_li_def 0;
BA_ "GenSigAutoGenDsp" SG_ 1137 LH_Schlusslicht_li_def 1;
BA_ "GenSigAutoGenSnd" SG_ 1137 LH_Schlusslicht_li_def 1;
BA_ "GenSigEnvVarType" SG_ 1137 LH_Schlusslicht_li_def 0;
BA_ "GenSigSendType" SG_ 1137 LH_Schlusslicht_li_def 7;
BA_ "NWM-WakeupAllowed" SG_ 1137 LH_Schlusslicht_li_def 0;
BA_ "NMH-WakeupAllowed" SG_ 1137 LH_Schlusslicht_li_def 0;
BA_ "GenSigAutoGenDsp" SG_ 1137 LH_Rueckf_li_def 1;
BA_ "GenSigAutoGenSnd" SG_ 1137 LH_Rueckf_li_def 1;
BA_ "GenSigEnvVarType" SG_ 1137 LH_Rueckf_li_def 0;
BA_ "GenSigSendType" SG_ 1137 LH_Rueckf_li_def 7;
BA_ "NWM-WakeupAllowed" SG_ 1137 LH_Rueckf_li_def 0;
BA_ "NMH-WakeupAllowed" SG_ 1137 LH_Rueckf_li_def 0;
BA_ "GenSigAutoGenDsp" SG_ 1137 LH_Nebel_li_def 1;
BA_ "GenSigAutoGenSnd" SG_ 1137 LH_Nebel_li_def 1;
BA_ "GenSigEnvVarType" SG_ 1137 LH_Nebel_li_def 0;
BA_ "GenSigSendType" SG_ 1137 LH_Nebel_li_def 7;
BA_ "NWM-WakeupAllowed" SG_ 1137 LH_Nebel_li_def 0;
BA_ "NMH-WakeupAllowed" SG_ 1137 LH_Nebel_li_def 0;
BA_ "GenSigAutoGenDsp" SG_ 1137 LH_Schluss_Brems_li_def 1;
BA_ "GenSigAutoGenSnd" SG_ 1137 LH_Schluss_Brems_li_def 1;
BA_ "GenSigEnvVarType" SG_ 1137 LH_Schluss_Brems_li_def 0;
BA_ "GenSigSendType" SG_ 1137 LH_Schluss_Brems_li_def 7;
BA_ "NWM-WakeupAllowed" SG_ 1137 LH_Schluss_Brems_li_def 0;
BA_ "NMH-WakeupAllowed" SG_ 1137 LH_Schluss_Brems_li_def 0;
BA_ "GenSigAutoGenDsp" SG_ 1137 LH_Schluss_Nebel_li_def 1;
BA_ "GenSigAutoGenSnd" SG_ 1137 LH_Schluss_Nebel_li_def 1;
BA_ "GenSigEnvVarType" SG_ 1137 LH_Schluss_Nebel_li_def 0;
BA_ "GenSigSendType" SG_ 1137 LH_Schluss_Nebel_li_def 7;
BA_ "NWM-WakeupAllowed" SG_ 1137 LH_Schluss_Nebel_li_def 0;
BA_ "NMH-WakeupAllowed" SG_ 1137 LH_Schluss_Nebel_li_def 0;
BA_ "GenSigAutoGenDsp" SG_ 1137 LH_SL_BRL_BLK_li_def 1;
BA_ "GenSigAutoGenSnd" SG_ 1137 LH_SL_BRL_BLK_li_def 1;
BA_ "GenSigEnvVarType" SG_ 1137 LH_SL_BRL_BLK_li_def 0;
BA_ "GenSigSendType" SG_ 1137 LH_SL_BRL_BLK_li_def 7;
BA_ "NWM-WakeupAllowed" SG_ 1137 LH_SL_BRL_BLK_li_def 0;
BA_ "NMH-WakeupAllowed" SG_ 1137 LH_SL_BRL_BLK_li_def 0;
BA_ "GenSigAutoGenDsp" SG_ 1137 LH_Brems_Blk_li_def 1;
BA_ "GenSigAutoGenSnd" SG_ 1137 LH_Brems_Blk_li_def 1;
BA_ "GenSigEnvVarType" SG_ 1137 LH_Brems_Blk_li_def 0;
BA_ "GenSigSendType" SG_ 1137 LH_Brems_Blk_li_def 7;
BA_ "NWM-WakeupAllowed" SG_ 1137 LH_Brems_Blk_li_def 0;
BA_ "NMH-WakeupAllowed" SG_ 1137 LH_Brems_Blk_li_def 0;
BA_ "GenSigAutoGenDsp" SG_ 1137 LH_Blinker_re_def 1;
BA_ "GenSigAutoGenSnd" SG_ 1137 LH_Blinker_re_def 1;
BA_ "GenSigEnvVarType" SG_ 1137 LH_Blinker_re_def 0;
BA_ "GenSigSendType" SG_ 1137 LH_Blinker_re_def 7;
BA_ "NWM-WakeupAllowed" SG_ 1137 LH_Blinker_re_def 0;
BA_ "NMH-WakeupAllowed" SG_ 1137 LH_Blinker_re_def 0;
BA_ "GenSigAutoGenDsp" SG_ 1137 LH_Bremsl_re_def 1;
BA_ "GenSigAutoGenSnd" SG_ 1137 LH_Bremsl_re_def 1;
BA_ "GenSigEnvVarType" SG_ 1137 LH_Bremsl_re_def 0;
BA_ "GenSigSendType" SG_ 1137 LH_Bremsl_re_def 7;
BA_ "NWM-WakeupAllowed" SG_ 1137 LH_Bremsl_re_def 0;
BA_ "NMH-WakeupAllowed" SG_ 1137 LH_Bremsl_re_def 0;
BA_ "GenSigAutoGenDsp" SG_ 1137 LH_Schlusslicht_re_def 1;
BA_ "GenSigAutoGenSnd" SG_ 1137 LH_Schlusslicht_re_def 1;
BA_ "GenSigEnvVarType" SG_ 1137 LH_Schlusslicht_re_def 0;
BA_ "GenSigSendType" SG_ 1137 LH_Schlusslicht_re_def 7;
BA_ "NWM-WakeupAllowed" SG_ 1137 LH_Schlusslicht_re_def 0;
BA_ "NMH-WakeupAllowed" SG_ 1137 LH_Schlusslicht_re_def 0;
BA_ "GenSigAutoGenDsp" SG_ 1137 LH_Rueckf_re_def 1;
BA_ "GenSigAutoGenSnd" SG_ 1137 LH_Rueckf_re_def 1;
BA_ "GenSigEnvVarType" SG_ 1137 LH_Rueckf_re_def 0;
BA_ "GenSigSendType" SG_ 1137 LH_Rueckf_re_def 7;
BA_ "NWM-WakeupAllowed" SG_ 1137 LH_Rueckf_re_def 0;
BA_ "NMH-WakeupAllowed" SG_ 1137 LH_Rueckf_re_def 0;
BA_ "GenSigAutoGenDsp" SG_ 1137 LH_Nebel_re_def 1;
BA_ "GenSigAutoGenSnd" SG_ 1137 LH_Nebel_re_def 1;
BA_ "GenSigEnvVarType" SG_ 1137 LH_Nebel_re_def 0;
BA_ "GenSigSendType" SG_ 1137 LH_Nebel_re_def 7;
BA_ "NWM-WakeupAllowed" SG_ 1137 LH_Nebel_re_def 0;
BA_ "NMH-WakeupAllowed" SG_ 1137 LH_Nebel_re_def 0;
BA_ "GenSigAutoGenDsp" SG_ 1137 LH_Schluss_Brems_re_def 1;
BA_ "GenSigAutoGenSnd" SG_ 1137 LH_Schluss_Brems_re_def 1;
BA_ "GenSigEnvVarType" SG_ 1137 LH_Schluss_Brems_re_def 0;
BA_ "GenSigSendType" SG_ 1137 LH_Schluss_Brems_re_def 7;
BA_ "NWM-WakeupAllowed" SG_ 1137 LH_Schluss_Brems_re_def 0;
BA_ "NMH-WakeupAllowed" SG_ 1137 LH_Schluss_Brems_re_def 0;
BA_ "GenSigAutoGenDsp" SG_ 1137 LH_Schluss_Nebel_re_def 1;
BA_ "GenSigAutoGenSnd" SG_ 1137 LH_Schluss_Nebel_re_def 1;
BA_ "GenSigEnvVarType" SG_ 1137 LH_Schluss_Nebel_re_def 0;
BA_ "GenSigSendType" SG_ 1137 LH_Schluss_Nebel_re_def 7;
BA_ "NWM-WakeupAllowed" SG_ 1137 LH_Schluss_Nebel_re_def 0;
BA_ "NMH-WakeupAllowed" SG_ 1137 LH_Schluss_Nebel_re_def 0;
BA_ "GenSigAutoGenDsp" SG_ 1137 LH_SL_BRL_BLK_re_def 1;
BA_ "GenSigAutoGenSnd" SG_ 1137 LH_SL_BRL_BLK_re_def 1;
BA_ "GenSigEnvVarType" SG_ 1137 LH_SL_BRL_BLK_re_def 0;
BA_ "GenSigSendType" SG_ 1137 LH_SL_BRL_BLK_re_def 7;
BA_ "NWM-WakeupAllowed" SG_ 1137 LH_SL_BRL_BLK_re_def 0;
BA_ "NMH-WakeupAllowed" SG_ 1137 LH_SL_BRL_BLK_re_def 0;
BA_ "GenSigAutoGenDsp" SG_ 1137 LH_Brems_Blk_re_def 1;
BA_ "GenSigAutoGenSnd" SG_ 1137 LH_Brems_Blk_re_def 1;
BA_ "GenSigEnvVarType" SG_ 1137 LH_Brems_Blk_re_def 0;
BA_ "GenSigSendType" SG_ 1137 LH_Brems_Blk_re_def 7;
BA_ "NWM-WakeupAllowed" SG_ 1137 LH_Brems_Blk_re_def 0;
BA_ "NMH-WakeupAllowed" SG_ 1137 LH_Brems_Blk_re_def 0;
BA_ "GenSigAutoGenDsp" SG_ 1137 LH_Kennzl_def 1;
BA_ "GenSigAutoGenSnd" SG_ 1137 LH_Kennzl_def 1;
BA_ "GenSigEnvVarType" SG_ 1137 LH_Kennzl_def 0;
BA_ "GenSigSendType" SG_ 1137 LH_Kennzl_def 7;
BA_ "NWM-WakeupAllowed" SG_ 1137 LH_Kennzl_def 0;
BA_ "NMH-WakeupAllowed" SG_ 1137 LH_Kennzl_def 0;
BA_ "GenSigAutoGenDsp" SG_ 1137 LH_3_Bremsl_def 1;
BA_ "GenSigAutoGenSnd" SG_ 1137 LH_3_Bremsl_def 1;
BA_ "GenSigEnvVarType" SG_ 1137 LH_3_Bremsl_def 0;
BA_ "GenSigSendType" SG_ 1137 LH_3_Bremsl_def 7;
BA_ "NWM-WakeupAllowed" SG_ 1137 LH_3_Bremsl_def 0;
BA_ "NMH-WakeupAllowed" SG_ 1137 LH_3_Bremsl_def 0;
BA_ "GenSigTimeoutMsg_Motor_EDC17_003" SG_ 1137 LH_3_Bremsl_def 1137;
BA_ "GenSigTimeoutMsg_Motor_EDC17_004" SG_ 1137 LH_3_Bremsl_def 1137;
BA_ "GenSigTimeoutMsg_Motor_MED17_B8" SG_ 1137 LH_3_Bremsl_def 1137;
BA_ "GenSigTimeoutMsg_Motor_SIMOS8_B8" SG_ 1137 LH_3_Bremsl_def 1137;
BA_ "GenSigAutoGenDsp" SG_ 1137 LH_Nebel_mi_def 1;
BA_ "GenSigAutoGenSnd" SG_ 1137 LH_Nebel_mi_def 1;
BA_ "GenSigEnvVarType" SG_ 1137 LH_Nebel_mi_def 0;
BA_ "GenSigSendType" SG_ 1137 LH_Nebel_mi_def 7;
BA_ "NWM-WakeupAllowed" SG_ 1137 LH_Nebel_mi_def 0;
BA_ "NMH-WakeupAllowed" SG_ 1137 LH_Nebel_mi_def 0;
BA_ "GenSigAutoGenDsp" SG_ 1137 LH_Rueckf_mi_def 1;
BA_ "GenSigAutoGenSnd" SG_ 1137 LH_Rueckf_mi_def 1;
BA_ "GenSigEnvVarType" SG_ 1137 LH_Rueckf_mi_def 0;
BA_ "GenSigSendType" SG_ 1137 LH_Rueckf_mi_def 7;
BA_ "NWM-WakeupAllowed" SG_ 1137 LH_Rueckf_mi_def 0;
BA_ "NMH-WakeupAllowed" SG_ 1137 LH_Rueckf_mi_def 0;
BA_ "GenSigAutoGenDsp" SG_ 1137 LH_Bremsl_li_ges_def 1;
BA_ "GenSigAutoGenSnd" SG_ 1137 LH_Bremsl_li_ges_def 1;
BA_ "GenSigEnvVarType" SG_ 1137 LH_Bremsl_li_ges_def 0;
BA_ "GenSigSendType" SG_ 1137 LH_Bremsl_li_ges_def 7;
BA_ "NWM-WakeupAllowed" SG_ 1137 LH_Bremsl_li_ges_def 0;
BA_ "NMH-WakeupAllowed" SG_ 1137 LH_Bremsl_li_ges_def 0;
BA_ "GenSigTimeoutMsg_Motor_EDC17_003" SG_ 1137 LH_Bremsl_li_ges_def 1137;
BA_ "GenSigTimeoutMsg_Motor_EDC17_004" SG_ 1137 LH_Bremsl_li_ges_def 1137;
BA_ "GenSigTimeoutMsg_Motor_MED17_B8" SG_ 1137 LH_Bremsl_li_ges_def 1137;
BA_ "GenSigTimeoutMsg_Motor_SIMOS8_B8" SG_ 1137 LH_Bremsl_li_ges_def 1137;
BA_ "GenSigAutoGenDsp" SG_ 1137 LH_Bremsl_re_ges_def 1;
BA_ "GenSigAutoGenSnd" SG_ 1137 LH_Bremsl_re_ges_def 1;
BA_ "GenSigSendType" SG_ 1137 LH_Bremsl_re_ges_def 7;
BA_ "NWM-WakeupAllowed" SG_ 1137 LH_Bremsl_re_ges_def 0;
BA_ "NMH-WakeupAllowed" SG_ 1137 LH_Bremsl_re_ges_def 0;
BA_ "GenSigTimeoutMsg_Motor_EDC17_003" SG_ 1137 LH_Bremsl_re_ges_def 1137;
BA_ "GenSigTimeoutMsg_Motor_EDC17_004" SG_ 1137 LH_Bremsl_re_ges_def 1137;
BA_ "GenSigTimeoutMsg_Motor_MED17_B8" SG_ 1137 LH_Bremsl_re_ges_def 1137;
BA_ "GenSigTimeoutMsg_Motor_SIMOS8_B8" SG_ 1137 LH_Bremsl_re_ges_def 1137;
BA_ "GenSigAutoGenDsp" SG_ 267 LS_01_CHK 1;
BA_ "GenSigAutoGenSnd" SG_ 267 LS_01_CHK 1;
BA_ "GenSigEnvVarType" SG_ 267 LS_01_CHK 0;
BA_ "GenSigSendType" SG_ 267 LS_01_CHK 7;
BA_ "NWM-WakeupAllowed" SG_ 267 LS_01_CHK 0;
BA_ "NMH-WakeupAllowed" SG_ 267 LS_01_CHK 0;
BA_ "GenSigTimeoutMsg_Getriebe_AL6000" SG_ 267 LS_01_CHK 267;
BA_ "GenSigTimeoutMsg_Getriebe_DL5001" SG_ 267 LS_01_CHK 267;
BA_ "GenSigTimeoutMsg_Getriebe_VL3002" SG_ 267 LS_01_CHK 267;
BA_ "GenSigTimeoutMsg_Motor_EDC17_003" SG_ 267 LS_01_CHK 267;
BA_ "GenSigTimeoutMsg_Motor_EDC17_004" SG_ 267 LS_01_CHK 267;
BA_ "GenSigTimeoutMsg_Motor_MED17_B8" SG_ 267 LS_01_CHK 267;
BA_ "GenSigTimeoutMsg_Motor_MED9_B8" SG_ 267 LS_01_CHK 267;
BA_ "GenSigTimeoutMsg_Motor_SIMOS8_B8" SG_ 267 LS_01_CHK 267;
BA_ "GenSigAutoGenDsp" SG_ 267 LS_01_BZ 1;
BA_ "GenSigAutoGenSnd" SG_ 267 LS_01_BZ 1;
BA_ "GenSigEnvVarType" SG_ 267 LS_01_BZ 0;
BA_ "GenSigSendType" SG_ 267 LS_01_BZ 7;
BA_ "NWM-WakeupAllowed" SG_ 267 LS_01_BZ 0;
BA_ "NMH-WakeupAllowed" SG_ 267 LS_01_BZ 0;
BA_ "GenSigTimeoutMsg_Getriebe_AL6000" SG_ 267 LS_01_BZ 267;
BA_ "GenSigTimeoutMsg_Getriebe_DL5001" SG_ 267 LS_01_BZ 267;
BA_ "GenSigTimeoutMsg_Getriebe_VL3002" SG_ 267 LS_01_BZ 267;
BA_ "GenSigTimeoutMsg_Motor_EDC17_003" SG_ 267 LS_01_BZ 267;
BA_ "GenSigTimeoutMsg_Motor_EDC17_004" SG_ 267 LS_01_BZ 267;
BA_ "GenSigTimeoutMsg_Motor_MED17_B8" SG_ 267 LS_01_BZ 267;
BA_ "GenSigTimeoutMsg_Motor_MED9_B8" SG_ 267 LS_01_BZ 267;
BA_ "GenSigTimeoutMsg_Motor_SIMOS8_B8" SG_ 267 LS_01_BZ 267;
BA_ "GenSigAutoGenDsp" SG_ 267 LS_Hauptschalter 1;
BA_ "GenSigAutoGenSnd" SG_ 267 LS_Hauptschalter 1;
BA_ "GenSigEnvVarType" SG_ 267 LS_Hauptschalter 0;
BA_ "GenSigSendType" SG_ 267 LS_Hauptschalter 7;
BA_ "NWM-WakeupAllowed" SG_ 267 LS_Hauptschalter 0;
BA_ "NMH-WakeupAllowed" SG_ 267 LS_Hauptschalter 0;
BA_ "GenSigTimeoutMsg_Motor_EDC17_003" SG_ 267 LS_Hauptschalter 267;
BA_ "GenSigTimeoutMsg_Motor_EDC17_004" SG_ 267 LS_Hauptschalter 267;
BA_ "GenSigTimeoutMsg_Motor_MED17_B8" SG_ 267 LS_Hauptschalter 267;
BA_ "GenSigTimeoutMsg_Motor_MED9_B8" SG_ 267 LS_Hauptschalter 267;
BA_ "GenSigTimeoutMsg_Motor_SIMOS8_B8" SG_ 267 LS_Hauptschalter 267;
BA_ "GenSigAutoGenDsp" SG_ 267 LS_Abbrechen 1;
BA_ "GenSigAutoGenSnd" SG_ 267 LS_Abbrechen 1;
BA_ "GenSigEnvVarType" SG_ 267 LS_Abbrechen 0;
BA_ "GenSigSendType" SG_ 267 LS_Abbrechen 7;
BA_ "NWM-WakeupAllowed" SG_ 267 LS_Abbrechen 0;
BA_ "NMH-WakeupAllowed" SG_ 267 LS_Abbrechen 0;
BA_ "GenSigTimeoutMsg_Motor_EDC17_003" SG_ 267 LS_Abbrechen 267;
BA_ "GenSigTimeoutMsg_Motor_EDC17_004" SG_ 267 LS_Abbrechen 267;
BA_ "GenSigTimeoutMsg_Motor_MED17_B8" SG_ 267 LS_Abbrechen 267;
BA_ "GenSigTimeoutMsg_Motor_MED9_B8" SG_ 267 LS_Abbrechen 267;
BA_ "GenSigTimeoutMsg_Motor_SIMOS8_B8" SG_ 267 LS_Abbrechen 267;
BA_ "GenSigAutoGenDsp" SG_ 267 LS_Typ_Hauptschalter 1;
BA_ "GenSigAutoGenSnd" SG_ 267 LS_Typ_Hauptschalter 1;
BA_ "GenSigEnvVarType" SG_ 267 LS_Typ_Hauptschalter 0;
BA_ "GenSigSendType" SG_ 267 LS_Typ_Hauptschalter 7;
BA_ "NWM-WakeupAllowed" SG_ 267 LS_Typ_Hauptschalter 0;
BA_ "NMH-WakeupAllowed" SG_ 267 LS_Typ_Hauptschalter 0;
BA_ "GenSigTimeoutMsg_Motor_EDC17_003" SG_ 267 LS_Typ_Hauptschalter 267;
BA_ "GenSigTimeoutMsg_Motor_EDC17_004" SG_ 267 LS_Typ_Hauptschalter 267;
BA_ "GenSigTimeoutMsg_Motor_MED17_B8" SG_ 267 LS_Typ_Hauptschalter 267;
BA_ "GenSigTimeoutMsg_Motor_MED9_B8" SG_ 267 LS_Typ_Hauptschalter 267;
BA_ "GenSigTimeoutMsg_Motor_SIMOS8_B8" SG_ 267 LS_Typ_Hauptschalter 267;
BA_ "GenSigAutoGenDsp" SG_ 267 LS_Limiter 1;
BA_ "GenSigAutoGenSnd" SG_ 267 LS_Limiter 1;
BA_ "GenSigEnvVarType" SG_ 267 LS_Limiter 0;
BA_ "GenSigSendType" SG_ 267 LS_Limiter 7;
BA_ "NWM-WakeupAllowed" SG_ 267 LS_Limiter 0;
BA_ "NMH-WakeupAllowed" SG_ 267 LS_Limiter 0;
BA_ "GenSigTimeoutMsg_Motor_EDC17_003" SG_ 267 LS_Limiter 267;
BA_ "GenSigTimeoutMsg_Motor_EDC17_004" SG_ 267 LS_Limiter 267;
BA_ "GenSigTimeoutMsg_Motor_MED17_B8" SG_ 267 LS_Limiter 267;
BA_ "GenSigTimeoutMsg_Motor_MED9_B8" SG_ 267 LS_Limiter 267;
BA_ "GenSigTimeoutMsg_Motor_SIMOS8_B8" SG_ 267 LS_Limiter 267;
BA_ "GenSigAutoGenDsp" SG_ 267 LS_Tip_Setzen 1;
BA_ "GenSigAutoGenSnd" SG_ 267 LS_Tip_Setzen 1;
BA_ "GenSigEnvVarType" SG_ 267 LS_Tip_Setzen 0;
BA_ "GenSigSendType" SG_ 267 LS_Tip_Setzen 7;
BA_ "NWM-WakeupAllowed" SG_ 267 LS_Tip_Setzen 0;
BA_ "NMH-WakeupAllowed" SG_ 267 LS_Tip_Setzen 0;
BA_ "GenSigTimeoutMsg_Motor_EDC17_003" SG_ 267 LS_Tip_Setzen 267;
BA_ "GenSigTimeoutMsg_Motor_EDC17_004" SG_ 267 LS_Tip_Setzen 267;
BA_ "GenSigTimeoutMsg_Motor_MED17_B8" SG_ 267 LS_Tip_Setzen 267;
BA_ "GenSigTimeoutMsg_Motor_MED9_B8" SG_ 267 LS_Tip_Setzen 267;
BA_ "GenSigTimeoutMsg_Motor_SIMOS8_B8" SG_ 267 LS_Tip_Setzen 267;
BA_ "GenSigAutoGenDsp" SG_ 267 LS_Tip_Hoch 1;
BA_ "GenSigAutoGenSnd" SG_ 267 LS_Tip_Hoch 1;
BA_ "GenSigEnvVarType" SG_ 267 LS_Tip_Hoch 0;
BA_ "GenSigSendType" SG_ 267 LS_Tip_Hoch 7;
BA_ "NWM-WakeupAllowed" SG_ 267 LS_Tip_Hoch 0;
BA_ "NMH-WakeupAllowed" SG_ 267 LS_Tip_Hoch 0;
BA_ "GenSigTimeoutMsg_Motor_EDC17_003" SG_ 267 LS_Tip_Hoch 267;
BA_ "GenSigTimeoutMsg_Motor_EDC17_004" SG_ 267 LS_Tip_Hoch 267;
BA_ "GenSigTimeoutMsg_Motor_MED17_B8" SG_ 267 LS_Tip_Hoch 267;
BA_ "GenSigTimeoutMsg_Motor_MED9_B8" SG_ 267 LS_Tip_Hoch 267;
BA_ "GenSigTimeoutMsg_Motor_SIMOS8_B8" SG_ 267 LS_Tip_Hoch 267;
BA_ "GenSigAutoGenDsp" SG_ 267 LS_Tip_Runter 1;
BA_ "GenSigAutoGenSnd" SG_ 267 LS_Tip_Runter 1;
BA_ "GenSigEnvVarType" SG_ 267 LS_Tip_Runter 0;
BA_ "GenSigSendType" SG_ 267 LS_Tip_Runter 7;
BA_ "NWM-WakeupAllowed" SG_ 267 LS_Tip_Runter 0;
BA_ "NMH-WakeupAllowed" SG_ 267 LS_Tip_Runter 0;
BA_ "GenSigTimeoutMsg_Motor_EDC17_003" SG_ 267 LS_Tip_Runter 267;
BA_ "GenSigTimeoutMsg_Motor_EDC17_004" SG_ 267 LS_Tip_Runter 267;
BA_ "GenSigTimeoutMsg_Motor_MED17_B8" SG_ 267 LS_Tip_Runter 267;
BA_ "GenSigTimeoutMsg_Motor_MED9_B8" SG_ 267 LS_Tip_Runter 267;
BA_ "GenSigTimeoutMsg_Motor_SIMOS8_B8" SG_ 267 LS_Tip_Runter 267;
BA_ "GenSigAutoGenDsp" SG_ 267 LS_Tip_Wiederaufnahme 1;
BA_ "GenSigAutoGenSnd" SG_ 267 LS_Tip_Wiederaufnahme 1;
BA_ "GenSigEnvVarType" SG_ 267 LS_Tip_Wiederaufnahme 0;
BA_ "GenSigSendType" SG_ 267 LS_Tip_Wiederaufnahme 7;
BA_ "NWM-WakeupAllowed" SG_ 267 LS_Tip_Wiederaufnahme 0;
BA_ "NMH-WakeupAllowed" SG_ 267 LS_Tip_Wiederaufnahme 0;
BA_ "GenSigTimeoutMsg_Motor_EDC17_003" SG_ 267 LS_Tip_Wiederaufnahme 267;
BA_ "GenSigTimeoutMsg_Motor_EDC17_004" SG_ 267 LS_Tip_Wiederaufnahme 267;
BA_ "GenSigTimeoutMsg_Motor_MED17_B8" SG_ 267 LS_Tip_Wiederaufnahme 267;
BA_ "GenSigTimeoutMsg_Motor_MED9_B8" SG_ 267 LS_Tip_Wiederaufnahme 267;
BA_ "GenSigTimeoutMsg_Motor_SIMOS8_B8" SG_ 267 LS_Tip_Wiederaufnahme 267;
BA_ "GenSigAutoGenDsp" SG_ 267 LS_Verstellung_Zeitluecke 1;
BA_ "GenSigAutoGenSnd" SG_ 267 LS_Verstellung_Zeitluecke 1;
BA_ "GenSigEnvVarType" SG_ 267 LS_Verstellung_Zeitluecke 0;
BA_ "GenSigSendType" SG_ 267 LS_Verstellung_Zeitluecke 7;
BA_ "NWM-WakeupAllowed" SG_ 267 LS_Verstellung_Zeitluecke 0;
BA_ "NMH-WakeupAllowed" SG_ 267 LS_Verstellung_Zeitluecke 0;
BA_ "GenSigAutoGenDsp" SG_ 267 MFL_Tip_Down 1;
BA_ "GenSigAutoGenSnd" SG_ 267 MFL_Tip_Down 1;
BA_ "GenSigEnvVarType" SG_ 267 MFL_Tip_Down 0;
BA_ "GenSigSendType" SG_ 267 MFL_Tip_Down 7;
BA_ "NWM-WakeupAllowed" SG_ 267 MFL_Tip_Down 0;
BA_ "NMH-WakeupAllowed" SG_ 267 MFL_Tip_Down 0;
BA_ "GenSigTimeoutMsg_Getriebe_AL6000" SG_ 267 MFL_Tip_Down 267;
BA_ "GenSigTimeoutMsg_Getriebe_DL5001" SG_ 267 MFL_Tip_Down 267;
BA_ "GenSigTimeoutMsg_Getriebe_VL3002" SG_ 267 MFL_Tip_Down 267;
BA_ "GenSigAutoGenDsp" SG_ 267 MFL_Tip_Up 1;
BA_ "GenSigAutoGenSnd" SG_ 267 MFL_Tip_Up 1;
BA_ "GenSigEnvVarType" SG_ 267 MFL_Tip_Up 0;
BA_ "GenSigSendType" SG_ 267 MFL_Tip_Up 7;
BA_ "NWM-WakeupAllowed" SG_ 267 MFL_Tip_Up 0;
BA_ "NMH-WakeupAllowed" SG_ 267 MFL_Tip_Up 0;
BA_ "GenSigTimeoutMsg_Getriebe_AL6000" SG_ 267 MFL_Tip_Up 267;
BA_ "GenSigTimeoutMsg_Getriebe_DL5001" SG_ 267 MFL_Tip_Up 267;
BA_ "GenSigTimeoutMsg_Getriebe_VL3002" SG_ 267 MFL_Tip_Up 267;
BA_ "GenSigAutoGenDsp" SG_ 267 LS_Tiptronic_Fehler 1;
BA_ "GenSigAutoGenSnd" SG_ 267 LS_Tiptronic_Fehler 1;
BA_ "GenSigEnvVarType" SG_ 267 LS_Tiptronic_Fehler 0;
BA_ "GenSigSendType" SG_ 267 LS_Tiptronic_Fehler 7;
BA_ "NWM-WakeupAllowed" SG_ 267 LS_Tiptronic_Fehler 0;
BA_ "NMH-WakeupAllowed" SG_ 267 LS_Tiptronic_Fehler 0;
BA_ "GenSigTimeoutMsg_Getriebe_AL6000" SG_ 267 LS_Tiptronic_Fehler 267;
BA_ "GenSigTimeoutMsg_Getriebe_DL5001" SG_ 267 LS_Tiptronic_Fehler 267;
BA_ "GenSigAutoGenDsp" SG_ 267 LS_Fehler 1;
BA_ "GenSigAutoGenSnd" SG_ 267 LS_Fehler 1;
BA_ "GenSigEnvVarType" SG_ 267 LS_Fehler 0;
BA_ "GenSigSendType" SG_ 267 LS_Fehler 7;
BA_ "NWM-WakeupAllowed" SG_ 267 LS_Fehler 0;
BA_ "NMH-WakeupAllowed" SG_ 267 LS_Fehler 0;
BA_ "GenSigTimeoutMsg_Motor_EDC17_003" SG_ 267 LS_Fehler 267;
BA_ "GenSigTimeoutMsg_Motor_EDC17_004" SG_ 267 LS_Fehler 267;
BA_ "GenSigTimeoutMsg_Motor_MED17_B8" SG_ 267 LS_Fehler 267;
BA_ "GenSigTimeoutMsg_Motor_MED9_B8" SG_ 267 LS_Fehler 267;
BA_ "GenSigTimeoutMsg_Motor_SIMOS8_B8" SG_ 267 LS_Fehler 267;
BA_ "GenSigAutoGenDsp" SG_ 267 LS_Codierung 1;
BA_ "GenSigAutoGenSnd" SG_ 267 LS_Codierung 1;
BA_ "GenSigEnvVarType" SG_ 267 LS_Codierung 0;
BA_ "GenSigSendType" SG_ 267 LS_Codierung 7;
BA_ "NWM-WakeupAllowed" SG_ 267 LS_Codierung 0;
BA_ "NMH-WakeupAllowed" SG_ 267 LS_Codierung 0;
BA_ "GenSigTimeoutMsg_Motor_EDC17_003" SG_ 267 LS_Codierung 267;
BA_ "GenSigTimeoutMsg_Motor_EDC17_004" SG_ 267 LS_Codierung 267;
BA_ "GenSigTimeoutMsg_Motor_MED17_B8" SG_ 267 LS_Codierung 267;
BA_ "GenSigTimeoutMsg_Motor_MED9_B8" SG_ 267 LS_Codierung 267;
BA_ "GenSigTimeoutMsg_Motor_SIMOS8_B8" SG_ 267 LS_Codierung 267;
BA_ "GenSigAutoGenDsp" SG_ 134 LWI_01_CHK 1;
BA_ "GenSigAutoGenSnd" SG_ 134 LWI_01_CHK 1;
BA_ "GenSigEnvVarType" SG_ 134 LWI_01_CHK 0;
BA_ "GenSigSendType" SG_ 134 LWI_01_CHK 7;
BA_ "NWM-WakeupAllowed" SG_ 134 LWI_01_CHK 0;
BA_ "NMH-WakeupAllowed" SG_ 134 LWI_01_CHK 0;
BA_ "GenSigTimeoutMsg_Daempfer_B8" SG_ 134 LWI_01_CHK 134;
BA_ "GenSigTimeoutMsg_Getriebe_AL6000" SG_ 134 LWI_01_CHK 134;
BA_ "GenSigTimeoutMsg_Getriebe_DL5001" SG_ 134 LWI_01_CHK 134;
BA_ "GenSigTimeoutMsg_Getriebe_VL3002" SG_ 134 LWI_01_CHK 134;
BA_ "GenSigTimeoutMsg_Motor_EDC17_003" SG_ 134 LWI_01_CHK 134;
BA_ "GenSigTimeoutMsg_Motor_EDC17_004" SG_ 134 LWI_01_CHK 134;
BA_ "GenSigTimeoutMsg_Motor_MED17_B8" SG_ 134 LWI_01_CHK 134;
BA_ "GenSigTimeoutMsg_Motor_MED9_B8" SG_ 134 LWI_01_CHK 134;
BA_ "GenSigTimeoutMsg_Motor_SIMOS8_B8" SG_ 134 LWI_01_CHK 134;
BA_ "GenSigAutoGenDsp" SG_ 134 LWI_01_BZ 1;
BA_ "GenSigAutoGenSnd" SG_ 134 LWI_01_BZ 1;
BA_ "GenSigEnvVarType" SG_ 134 LWI_01_BZ 0;
BA_ "GenSigSendType" SG_ 134 LWI_01_BZ 7;
BA_ "NWM-WakeupAllowed" SG_ 134 LWI_01_BZ 0;
BA_ "NMH-WakeupAllowed" SG_ 134 LWI_01_BZ 0;
BA_ "GenSigTimeoutMsg_Daempfer_B8" SG_ 134 LWI_01_BZ 134;
BA_ "GenSigTimeoutMsg_Getriebe_AL6000" SG_ 134 LWI_01_BZ 134;
BA_ "GenSigTimeoutMsg_Getriebe_DL5001" SG_ 134 LWI_01_BZ 134;
BA_ "GenSigTimeoutMsg_Getriebe_VL3002" SG_ 134 LWI_01_BZ 134;
BA_ "GenSigTimeoutMsg_Motor_EDC17_003" SG_ 134 LWI_01_BZ 134;
BA_ "GenSigTimeoutMsg_Motor_EDC17_004" SG_ 134 LWI_01_BZ 134;
BA_ "GenSigTimeoutMsg_Motor_MED17_B8" SG_ 134 LWI_01_BZ 134;
BA_ "GenSigTimeoutMsg_Motor_MED9_B8" SG_ 134 LWI_01_BZ 134;
BA_ "GenSigTimeoutMsg_Motor_SIMOS8_B8" SG_ 134 LWI_01_BZ 134;
BA_ "GenSigAutoGenDsp" SG_ 134 LWI_Sensorstatus 1;
BA_ "GenSigAutoGenSnd" SG_ 134 LWI_Sensorstatus 1;
BA_ "GenSigEnvVarType" SG_ 134 LWI_Sensorstatus 0;
BA_ "GenSigSendType" SG_ 134 LWI_Sensorstatus 7;
BA_ "NWM-WakeupAllowed" SG_ 134 LWI_Sensorstatus 0;
BA_ "NMH-WakeupAllowed" SG_ 134 LWI_Sensorstatus 0;
BA_ "GenSigTimeoutMsg_AFS_B8" SG_ 134 LWI_Sensorstatus 134;
BA_ "GenSigTimeoutMsg_Getriebe_AL6000" SG_ 134 LWI_Sensorstatus 134;
BA_ "GenSigTimeoutMsg_Motor_EDC17_003" SG_ 134 LWI_Sensorstatus 134;
BA_ "GenSigTimeoutMsg_Motor_EDC17_004" SG_ 134 LWI_Sensorstatus 134;
BA_ "GenSigTimeoutMsg_Motor_MED17_B8" SG_ 134 LWI_Sensorstatus 134;
BA_ "GenSigTimeoutMsg_Motor_MED9_B8" SG_ 134 LWI_Sensorstatus 134;
BA_ "GenSigTimeoutMsg_Motor_SIMOS8_B8" SG_ 134 LWI_Sensorstatus 134;
BA_ "GenSigAutoGenDsp" SG_ 134 LWI_QBit_Sub_Daten 1;
BA_ "GenSigAutoGenSnd" SG_ 134 LWI_QBit_Sub_Daten 1;
BA_ "GenSigSendType" SG_ 134 LWI_QBit_Sub_Daten 7;
BA_ "NWM-WakeupAllowed" SG_ 134 LWI_QBit_Sub_Daten 0;
BA_ "NMH-WakeupAllowed" SG_ 134 LWI_QBit_Sub_Daten 0;
BA_ "GenSigAutoGenDsp" SG_ 134 LWI_QBit_Lenkradwinkel 1;
BA_ "GenSigAutoGenSnd" SG_ 134 LWI_QBit_Lenkradwinkel 1;
BA_ "GenSigEnvVarType" SG_ 134 LWI_QBit_Lenkradwinkel 0;
BA_ "GenSigSendType" SG_ 134 LWI_QBit_Lenkradwinkel 7;
BA_ "GenSigStartValue" SG_ 134 LWI_QBit_Lenkradwinkel 1;
BA_ "NWM-WakeupAllowed" SG_ 134 LWI_QBit_Lenkradwinkel 0;
BA_ "NMH-WakeupAllowed" SG_ 134 LWI_QBit_Lenkradwinkel 0;
BA_ "GenSigTimeoutMsg_Daempfer_B8" SG_ 134 LWI_QBit_Lenkradwinkel 134;
BA_ "GenSigTimeoutMsg_Getriebe_AL6000" SG_ 134 LWI_QBit_Lenkradwinkel 134;
BA_ "GenSigTimeoutMsg_Motor_EDC17_003" SG_ 134 LWI_QBit_Lenkradwinkel 134;
BA_ "GenSigTimeoutMsg_Motor_EDC17_004" SG_ 134 LWI_QBit_Lenkradwinkel 134;
BA_ "GenSigTimeoutMsg_Motor_MED17_B8" SG_ 134 LWI_QBit_Lenkradwinkel 134;
BA_ "GenSigTimeoutMsg_Motor_MED9_B8" SG_ 134 LWI_QBit_Lenkradwinkel 134;
BA_ "GenSigTimeoutMsg_Motor_SIMOS8_B8" SG_ 134 LWI_QBit_Lenkradwinkel 134;
BA_ "GenSigAutoGenDsp" SG_ 134 LWI_Lenkradwinkel 1;
BA_ "GenSigAutoGenSnd" SG_ 134 LWI_Lenkradwinkel 1;
BA_ "GenSigEnvVarType" SG_ 134 LWI_Lenkradwinkel 1;
BA_ "GenSigSendType" SG_ 134 LWI_Lenkradwinkel 7;
BA_ "GenSigStartValue" SG_ 134 LWI_Lenkradwinkel 8190;
BA_ "NWM-WakeupAllowed" SG_ 134 LWI_Lenkradwinkel 0;
BA_ "NMH-WakeupAllowed" SG_ 134 LWI_Lenkradwinkel 0;
BA_ "GenSigTimeoutMsg_AFS_B8" SG_ 134 LWI_Lenkradwinkel 134;
BA_ "GenSigTimeoutMsg_Daempfer_B8" SG_ 134 LWI_Lenkradwinkel 134;
BA_ "GenSigTimeoutMsg_Getriebe_AL6000" SG_ 134 LWI_Lenkradwinkel 134;
BA_ "GenSigTimeoutMsg_Getriebe_DL5001" SG_ 134 LWI_Lenkradwinkel 134;
BA_ "GenSigTimeoutMsg_Getriebe_VL3002" SG_ 134 LWI_Lenkradwinkel 134;
BA_ "GenSigTimeoutMsg_Motor_EDC17_003" SG_ 134 LWI_Lenkradwinkel 134;
BA_ "GenSigTimeoutMsg_Motor_EDC17_004" SG_ 134 LWI_Lenkradwinkel 134;
BA_ "GenSigTimeoutMsg_Motor_MED17_B8" SG_ 134 LWI_Lenkradwinkel 134;
BA_ "GenSigTimeoutMsg_Motor_MED9_B8" SG_ 134 LWI_Lenkradwinkel 134;
BA_ "GenSigTimeoutMsg_Motor_SIMOS8_B8" SG_ 134 LWI_Lenkradwinkel 134;
BA_ "GenSigAutoGenDsp" SG_ 134 LWI_VZ_Lenkradwinkel 1;
BA_ "GenSigAutoGenSnd" SG_ 134 LWI_VZ_Lenkradwinkel 1;
BA_ "GenSigEnvVarType" SG_ 134 LWI_VZ_Lenkradwinkel 0;
BA_ "GenSigSendType" SG_ 134 LWI_VZ_Lenkradwinkel 7;
BA_ "NWM-WakeupAllowed" SG_ 134 LWI_VZ_Lenkradwinkel 0;
BA_ "NMH-WakeupAllowed" SG_ 134 LWI_VZ_Lenkradwinkel 0;
BA_ "GenSigTimeoutMsg_AFS_B8" SG_ 134 LWI_VZ_Lenkradwinkel 134;
BA_ "GenSigTimeoutMsg_Daempfer_B8" SG_ 134 LWI_VZ_Lenkradwinkel 134;
BA_ "GenSigTimeoutMsg_Getriebe_AL6000" SG_ 134 LWI_VZ_Lenkradwinkel 134;
BA_ "GenSigTimeoutMsg_Motor_EDC17_003" SG_ 134 LWI_VZ_Lenkradwinkel 134;
BA_ "GenSigTimeoutMsg_Motor_EDC17_004" SG_ 134 LWI_VZ_Lenkradwinkel 134;
BA_ "GenSigTimeoutMsg_Motor_MED17_B8" SG_ 134 LWI_VZ_Lenkradwinkel 134;
BA_ "GenSigTimeoutMsg_Motor_MED9_B8" SG_ 134 LWI_VZ_Lenkradwinkel 134;
BA_ "GenSigTimeoutMsg_Motor_SIMOS8_B8" SG_ 134 LWI_VZ_Lenkradwinkel 134;
BA_ "GenSigAutoGenDsp" SG_ 134 LWI_VZ_Lenkradw_Geschw 1;
BA_ "GenSigAutoGenSnd" SG_ 134 LWI_VZ_Lenkradw_Geschw 1;
BA_ "GenSigSendType" SG_ 134 LWI_VZ_Lenkradw_Geschw 7;
BA_ "NWM-WakeupAllowed" SG_ 134 LWI_VZ_Lenkradw_Geschw 0;
BA_ "NMH-WakeupAllowed" SG_ 134 LWI_VZ_Lenkradw_Geschw 0;
BA_ "GenSigAutoGenDsp" SG_ 134 LWI_Lenkradw_Geschw 1;
BA_ "GenSigAutoGenSnd" SG_ 134 LWI_Lenkradw_Geschw 1;
BA_ "GenSigSendType" SG_ 134 LWI_Lenkradw_Geschw 7;
BA_ "GenSigStartValue" SG_ 134 LWI_Lenkradw_Geschw 510;
BA_ "NWM-WakeupAllowed" SG_ 134 LWI_Lenkradw_Geschw 0;
BA_ "NMH-WakeupAllowed" SG_ 134 LWI_Lenkradw_Geschw 0;
BA_ "GenSigAutoGenDsp" SG_ 134 LWI_Sub_Daten 1;
BA_ "GenSigAutoGenSnd" SG_ 134 LWI_Sub_Daten 1;
BA_ "GenSigSendType" SG_ 134 LWI_Sub_Daten 7;
BA_ "NWM-WakeupAllowed" SG_ 134 LWI_Sub_Daten 0;
BA_ "NMH-WakeupAllowed" SG_ 134 LWI_Sub_Daten 0;
BA_ "GenSigAutoGenDsp" SG_ 134 LWI_01_CRC 1;
BA_ "GenSigAutoGenSnd" SG_ 134 LWI_01_CRC 1;
BA_ "GenSigSendType" SG_ 134 LWI_01_CRC 7;
BA_ "NWM-WakeupAllowed" SG_ 134 LWI_01_CRC 0;
BA_ "NMH-WakeupAllowed" SG_ 134 LWI_01_CRC 0;
BA_ "GenSigAutoGenDsp" SG_ 917 LWR_AFS_01_BZ 1;
BA_ "GenSigAutoGenSnd" SG_ 917 LWR_AFS_01_BZ 1;
BA_ "GenSigSendType" SG_ 917 LWR_AFS_01_BZ 7;
BA_ "NWM-WakeupAllowed" SG_ 917 LWR_AFS_01_BZ 0;
BA_ "NMH-WakeupAllowed" SG_ 917 LWR_AFS_01_BZ 0;
BA_ "GenSigTimeoutMsg_Gateway_B8" SG_ 917 LWR_AFS_01_BZ 917;
BA_ "GenSigAutoGenDsp" SG_ 917 AFS_Lampe 1;
BA_ "GenSigAutoGenSnd" SG_ 917 AFS_Lampe 1;
BA_ "GenSigSendType" SG_ 917 AFS_Lampe 7;
BA_ "NWM-WakeupAllowed" SG_ 917 AFS_Lampe 0;
BA_ "NMH-WakeupAllowed" SG_ 917 AFS_Lampe 0;
BA_ "GenSigTimeoutMsg_Gateway_B8" SG_ 917 AFS_Lampe 917;
BA_ "GenSigAutoGenDsp" SG_ 917 LWR_Lampe 1;
BA_ "GenSigAutoGenSnd" SG_ 917 LWR_Lampe 1;
BA_ "GenSigSendType" SG_ 917 LWR_Lampe 7;
BA_ "NWM-WakeupAllowed" SG_ 917 LWR_Lampe 0;
BA_ "NMH-WakeupAllowed" SG_ 917 LWR_Lampe 0;
BA_ "GenSigTimeoutMsg_Gateway_B8" SG_ 917 LWR_Lampe 917;
BA_ "GenSigAutoGenDsp" SG_ 917 AFS_Fehlertext 1;
BA_ "GenSigAutoGenSnd" SG_ 917 AFS_Fehlertext 1;
BA_ "GenSigSendType" SG_ 917 AFS_Fehlertext 7;
BA_ "NWM-WakeupAllowed" SG_ 917 AFS_Fehlertext 0;
BA_ "NMH-WakeupAllowed" SG_ 917 AFS_Fehlertext 0;
BA_ "GenSigTimeoutMsg_Gateway_B8" SG_ 917 AFS_Fehlertext 917;
BA_ "GenSigAutoGenDsp" SG_ 917 AFS_LED_Blinkmode 1;
BA_ "GenSigAutoGenSnd" SG_ 917 AFS_LED_Blinkmode 1;
BA_ "GenSigSendType" SG_ 917 AFS_LED_Blinkmode 7;
BA_ "NWM-WakeupAllowed" SG_ 917 AFS_LED_Blinkmode 0;
BA_ "NMH-WakeupAllowed" SG_ 917 AFS_LED_Blinkmode 0;
BA_ "GenSigTimeoutMsg_Gateway_B8" SG_ 917 AFS_LED_Blinkmode 917;
BA_ "GenSigAutoGenDsp" SG_ 917 LWR_Touristenmodus_aktiv 1;
BA_ "GenSigAutoGenSnd" SG_ 917 LWR_Touristenmodus_aktiv 1;
BA_ "GenSigSendType" SG_ 917 LWR_Touristenmodus_aktiv 7;
BA_ "NWM-WakeupAllowed" SG_ 917 LWR_Touristenmodus_aktiv 0;
BA_ "NMH-WakeupAllowed" SG_ 917 LWR_Touristenmodus_aktiv 0;
BA_ "GenSigTimeoutMsg_Gateway_B8" SG_ 917 LWR_Touristenmodus_aktiv 917;
BA_ "GenSigAutoGenDsp" SG_ 917 AFS_Sollwert_LD_EVG 1;
BA_ "GenSigAutoGenSnd" SG_ 917 AFS_Sollwert_LD_EVG 1;
BA_ "GenSigSendType" SG_ 917 AFS_Sollwert_LD_EVG 7;
BA_ "GenSigStartValue" SG_ 917 AFS_Sollwert_LD_EVG 254;
BA_ "NWM-WakeupAllowed" SG_ 917 AFS_Sollwert_LD_EVG 0;
BA_ "NMH-WakeupAllowed" SG_ 917 AFS_Sollwert_LD_EVG 0;
BA_ "GenSigTimeoutMsg_Gateway_B8" SG_ 917 AFS_Sollwert_LD_EVG 917;
BA_ "GenSigAutoGenDsp" SG_ 917 LWR_Pos_Schrittmotor 1;
BA_ "GenSigAutoGenSnd" SG_ 917 LWR_Pos_Schrittmotor 1;
BA_ "GenSigSendType" SG_ 917 LWR_Pos_Schrittmotor 7;
BA_ "GenSigStartValue" SG_ 917 LWR_Pos_Schrittmotor 254;
BA_ "NWM-WakeupAllowed" SG_ 917 LWR_Pos_Schrittmotor 0;
BA_ "NMH-WakeupAllowed" SG_ 917 LWR_Pos_Schrittmotor 0;
BA_ "GenSigTimeoutMsg_Gateway_B8" SG_ 917 LWR_Pos_Schrittmotor 917;
BA_ "GenSigAutoGenDsp" SG_ 917 LWR_Hoehenwert_VL 1;
BA_ "GenSigAutoGenSnd" SG_ 917 LWR_Hoehenwert_VL 1;
BA_ "GenSigSendType" SG_ 917 LWR_Hoehenwert_VL 7;
BA_ "GenSigStartValue" SG_ 917 LWR_Hoehenwert_VL 254;
BA_ "NWM-WakeupAllowed" SG_ 917 LWR_Hoehenwert_VL 0;
BA_ "NMH-WakeupAllowed" SG_ 917 LWR_Hoehenwert_VL 0;
BA_ "GenSigTimeoutMsg_Gateway_B8" SG_ 917 LWR_Hoehenwert_VL 917;
BA_ "GenSigAutoGenDsp" SG_ 917 LWR_Hoehenwert_HL 1;
BA_ "GenSigAutoGenSnd" SG_ 917 LWR_Hoehenwert_HL 1;
BA_ "GenSigSendType" SG_ 917 LWR_Hoehenwert_HL 7;
BA_ "GenSigStartValue" SG_ 917 LWR_Hoehenwert_HL 254;
BA_ "NWM-WakeupAllowed" SG_ 917 LWR_Hoehenwert_HL 0;
BA_ "NMH-WakeupAllowed" SG_ 917 LWR_Hoehenwert_HL 0;
BA_ "GenSigTimeoutMsg_Gateway_B8" SG_ 917 LWR_Hoehenwert_HL 917;
BA_ "GenSigAutoGenDsp" SG_ 917 AFS_Ersatzlicht_Links 1;
BA_ "GenSigAutoGenSnd" SG_ 917 AFS_Ersatzlicht_Links 1;
BA_ "GenSigSendType" SG_ 917 AFS_Ersatzlicht_Links 7;
BA_ "NWM-WakeupAllowed" SG_ 917 AFS_Ersatzlicht_Links 0;
BA_ "NMH-WakeupAllowed" SG_ 917 AFS_Ersatzlicht_Links 0;
BA_ "GenSigTimeoutMsg_Gateway_B8" SG_ 917 AFS_Ersatzlicht_Links 917;
BA_ "GenSigAutoGenDsp" SG_ 917 AFS_Ersatzlicht_Rechts 1;
BA_ "GenSigAutoGenSnd" SG_ 917 AFS_Ersatzlicht_Rechts 1;
BA_ "GenSigSendType" SG_ 917 AFS_Ersatzlicht_Rechts 7;
BA_ "NWM-WakeupAllowed" SG_ 917 AFS_Ersatzlicht_Rechts 0;
BA_ "NMH-WakeupAllowed" SG_ 917 AFS_Ersatzlicht_Rechts 0;
BA_ "GenSigTimeoutMsg_Gateway_B8" SG_ 917 AFS_Ersatzlicht_Rechts 917;
BA_ "GenSigAutoGenDsp" SG_ 917 LWR_AFS_Grundeinstellung 1;
BA_ "GenSigAutoGenSnd" SG_ 917 LWR_AFS_Grundeinstellung 1;
BA_ "GenSigSendType" SG_ 917 LWR_AFS_Grundeinstellung 7;
BA_ "NWM-WakeupAllowed" SG_ 917 LWR_AFS_Grundeinstellung 0;
BA_ "NMH-WakeupAllowed" SG_ 917 LWR_AFS_Grundeinstellung 0;
BA_ "GenSigTimeoutMsg_Gateway_B8" SG_ 917 LWR_AFS_Grundeinstellung 917;
BA_ "GenSigAutoGenDsp" SG_ 917 LWR_AFS_Parametrisierung 1;
BA_ "GenSigAutoGenSnd" SG_ 917 LWR_AFS_Parametrisierung 1;
BA_ "GenSigSendType" SG_ 917 LWR_AFS_Parametrisierung 7;
BA_ "NWM-WakeupAllowed" SG_ 917 LWR_AFS_Parametrisierung 0;
BA_ "NMH-WakeupAllowed" SG_ 917 LWR_AFS_Parametrisierung 0;
BA_ "GenSigTimeoutMsg_Gateway_B8" SG_ 917 LWR_AFS_Parametrisierung 917;
BA_ "GenSigAutoGenDsp" SG_ 917 LWR_Initialisierungslauf 1;
BA_ "GenSigAutoGenSnd" SG_ 917 LWR_Initialisierungslauf 1;
BA_ "GenSigSendType" SG_ 917 LWR_Initialisierungslauf 7;
BA_ "NWM-WakeupAllowed" SG_ 917 LWR_Initialisierungslauf 0;
BA_ "NMH-WakeupAllowed" SG_ 917 LWR_Initialisierungslauf 0;
BA_ "GenSigTimeoutMsg_Gateway_B8" SG_ 917 LWR_Initialisierungslauf 917;
BA_ "GenSigAutoGenDsp" SG_ 917 LWR_Sicherheitsposition 1;
BA_ "GenSigAutoGenSnd" SG_ 917 LWR_Sicherheitsposition 1;
BA_ "GenSigSendType" SG_ 917 LWR_Sicherheitsposition 7;
BA_ "NWM-WakeupAllowed" SG_ 917 LWR_Sicherheitsposition 0;
BA_ "NMH-WakeupAllowed" SG_ 917 LWR_Sicherheitsposition 0;
BA_ "GenSigTimeoutMsg_Gateway_B8" SG_ 917 LWR_Sicherheitsposition 917;
BA_ "GenSigAutoGenDsp" SG_ 917 LWR_Modus 1;
BA_ "GenSigAutoGenSnd" SG_ 917 LWR_Modus 1;
BA_ "GenSigSendType" SG_ 917 LWR_Modus 7;
BA_ "NWM-WakeupAllowed" SG_ 917 LWR_Modus 0;
BA_ "NMH-WakeupAllowed" SG_ 917 LWR_Modus 0;
BA_ "GenSigTimeoutMsg_Gateway_B8" SG_ 917 LWR_Modus 917;
BA_ "GenSigAutoGenDsp" SG_ 917 LWR_KD_Fehler 1;
BA_ "GenSigAutoGenSnd" SG_ 917 LWR_KD_Fehler 1;
BA_ "GenSigEnvVarType" SG_ 917 LWR_KD_Fehler 0;
BA_ "GenSigSendType" SG_ 917 LWR_KD_Fehler 7;
BA_ "NWM-WakeupAllowed" SG_ 917 LWR_KD_Fehler 0;
BA_ "NMH-WakeupAllowed" SG_ 917 LWR_KD_Fehler 0;
BA_ "GenSigTimeoutMsg_Gateway_B8" SG_ 917 LWR_KD_Fehler 917;
BA_ "GenSigAutoGenDsp" SG_ 128 Motor_01_CHK 1;
BA_ "GenSigAutoGenSnd" SG_ 128 Motor_01_CHK 1;
BA_ "GenSigEnvVarType" SG_ 128 Motor_01_CHK 0;
BA_ "GenSigSendType" SG_ 128 Motor_01_CHK 7;
BA_ "NWM-WakeupAllowed" SG_ 128 Motor_01_CHK 0;
BA_ "NMH-WakeupAllowed" SG_ 128 Motor_01_CHK 0;
BA_ "GenSigTimeoutMsg_Daempfer_B8" SG_ 128 Motor_01_CHK 128;
BA_ "GenSigTimeoutMsg_Gateway_B8" SG_ 128 Motor_01_CHK 128;
BA_ "GenSigTimeoutMsg_Getriebe_AL6000" SG_ 128 Motor_01_CHK 128;
BA_ "GenSigTimeoutMsg_Getriebe_DL5001" SG_ 128 Motor_01_CHK 128;
BA_ "GenSigTimeoutMsg_Getriebe_VL3002" SG_ 128 Motor_01_CHK 128;
BA_ "GenSigAutoGenDsp" SG_ 128 Motor_01_BZ 1;
BA_ "GenSigAutoGenSnd" SG_ 128 Motor_01_BZ 1;
BA_ "GenSigEnvVarType" SG_ 128 Motor_01_BZ 0;
BA_ "GenSigSendType" SG_ 128 Motor_01_BZ 7;
BA_ "NWM-WakeupAllowed" SG_ 128 Motor_01_BZ 0;
BA_ "NMH-WakeupAllowed" SG_ 128 Motor_01_BZ 0;
BA_ "GenSigTimeoutMsg_Daempfer_B8" SG_ 128 Motor_01_BZ 128;
BA_ "GenSigTimeoutMsg_Gateway_B8" SG_ 128 Motor_01_BZ 128;
BA_ "GenSigTimeoutMsg_Getriebe_AL6000" SG_ 128 Motor_01_BZ 128;
BA_ "GenSigTimeoutMsg_Getriebe_DL5001" SG_ 128 Motor_01_BZ 128;
BA_ "GenSigTimeoutMsg_Getriebe_VL3002" SG_ 128 Motor_01_BZ 128;
BA_ "GenSigAutoGenDsp" SG_ 128 MO_Mom_o_ex 1;
BA_ "GenSigAutoGenSnd" SG_ 128 MO_Mom_o_ex 1;
BA_ "GenSigEnvVarType" SG_ 128 MO_Mom_o_ex 1;
BA_ "GenSigSendType" SG_ 128 MO_Mom_o_ex 7;
BA_ "GenSigStartValue" SG_ 128 MO_Mom_o_ex 1022;
BA_ "NWM-WakeupAllowed" SG_ 128 MO_Mom_o_ex 0;
BA_ "NMH-WakeupAllowed" SG_ 128 MO_Mom_o_ex 0;
BA_ "GenSigTimeoutMsg_Gateway_B8" SG_ 128 MO_Mom_o_ex 128;
BA_ "GenSigTimeoutMsg_Getriebe_AL6000" SG_ 128 MO_Mom_o_ex 128;
BA_ "GenSigTimeoutMsg_Getriebe_DL5001" SG_ 128 MO_Mom_o_ex 128;
BA_ "GenSigTimeoutMsg_Getriebe_VL3002" SG_ 128 MO_Mom_o_ex 128;
BA_ "GenSigAutoGenDsp" SG_ 128 MO_Mom_m_ex 1;
BA_ "GenSigAutoGenSnd" SG_ 128 MO_Mom_m_ex 1;
BA_ "GenSigEnvVarType" SG_ 128 MO_Mom_m_ex 1;
BA_ "GenSigSendType" SG_ 128 MO_Mom_m_ex 7;
BA_ "GenSigStartValue" SG_ 128 MO_Mom_m_ex 1022;
BA_ "NWM-WakeupAllowed" SG_ 128 MO_Mom_m_ex 0;
BA_ "NMH-WakeupAllowed" SG_ 128 MO_Mom_m_ex 0;
BA_ "GenSigTimeoutMsg_Gateway_B8" SG_ 128 MO_Mom_m_ex 128;
BA_ "GenSigTimeoutMsg_Getriebe_AL6000" SG_ 128 MO_Mom_m_ex 128;
BA_ "GenSigTimeoutMsg_Getriebe_DL5001" SG_ 128 MO_Mom_m_ex 128;
BA_ "GenSigTimeoutMsg_Getriebe_VL3002" SG_ 128 MO_Mom_m_ex 128;
BA_ "GenSigAutoGenDsp" SG_ 128 MO_Mom_Verlust 1;
BA_ "GenSigAutoGenSnd" SG_ 128 MO_Mom_Verlust 1;
BA_ "GenSigEnvVarType" SG_ 128 MO_Mom_Verlust 1;
BA_ "GenSigSendType" SG_ 128 MO_Mom_Verlust 7;
BA_ "GenSigStartValue" SG_ 128 MO_Mom_Verlust 1022;
BA_ "NWM-WakeupAllowed" SG_ 128 MO_Mom_Verlust 0;
BA_ "NMH-WakeupAllowed" SG_ 128 MO_Mom_Verlust 0;
BA_ "GenSigTimeoutMsg_Gateway_B8" SG_ 128 MO_Mom_Verlust 128;
BA_ "GenSigTimeoutMsg_Getriebe_AL6000" SG_ 128 MO_Mom_Verlust 128;
BA_ "GenSigTimeoutMsg_Getriebe_DL5001" SG_ 128 MO_Mom_Verlust 128;
BA_ "GenSigTimeoutMsg_Getriebe_VL3002" SG_ 128 MO_Mom_Verlust 128;
BA_ "GenSigAutoGenDsp" SG_ 128 MO_Mom_Begrenzung 1;
BA_ "GenSigAutoGenSnd" SG_ 128 MO_Mom_Begrenzung 1;
BA_ "GenSigEnvVarType" SG_ 128 MO_Mom_Begrenzung 1;
BA_ "GenSigSendType" SG_ 128 MO_Mom_Begrenzung 7;
BA_ "GenSigStartValue" SG_ 128 MO_Mom_Begrenzung 1022;
BA_ "NWM-WakeupAllowed" SG_ 128 MO_Mom_Begrenzung 0;
BA_ "NMH-WakeupAllowed" SG_ 128 MO_Mom_Begrenzung 0;
BA_ "GenSigTimeoutMsg_Gateway_B8" SG_ 128 MO_Mom_Begrenzung 128;
BA_ "GenSigTimeoutMsg_Getriebe_AL6000" SG_ 128 MO_Mom_Begrenzung 128;
BA_ "GenSigTimeoutMsg_Getriebe_DL5001" SG_ 128 MO_Mom_Begrenzung 128;
BA_ "GenSigTimeoutMsg_Getriebe_VL3002" SG_ 128 MO_Mom_Begrenzung 128;
BA_ "GenSigAutoGenDsp" SG_ 128 MO_Mom_Fahrerwunsch 1;
BA_ "GenSigAutoGenSnd" SG_ 128 MO_Mom_Fahrerwunsch 1;
BA_ "GenSigEnvVarType" SG_ 128 MO_Mom_Fahrerwunsch 1;
BA_ "GenSigSendType" SG_ 128 MO_Mom_Fahrerwunsch 7;
BA_ "GenSigStartValue" SG_ 128 MO_Mom_Fahrerwunsch 1022;
BA_ "NWM-WakeupAllowed" SG_ 128 MO_Mom_Fahrerwunsch 0;
BA_ "NMH-WakeupAllowed" SG_ 128 MO_Mom_Fahrerwunsch 0;
BA_ "GenSigTimeoutMsg_Daempfer_B8" SG_ 128 MO_Mom_Fahrerwunsch 128;
BA_ "GenSigTimeoutMsg_Gateway_B8" SG_ 128 MO_Mom_Fahrerwunsch 128;
BA_ "GenSigTimeoutMsg_Getriebe_AL6000" SG_ 128 MO_Mom_Fahrerwunsch 128;
BA_ "GenSigTimeoutMsg_Getriebe_DL5001" SG_ 128 MO_Mom_Fahrerwunsch 128;
BA_ "GenSigTimeoutMsg_Getriebe_VL3002" SG_ 128 MO_Mom_Fahrerwunsch 128;
BA_ "GenSigAutoGenDsp" SG_ 128 MO_Kickdown 1;
BA_ "GenSigAutoGenSnd" SG_ 128 MO_Kickdown 1;
BA_ "GenSigEnvVarType" SG_ 128 MO_Kickdown 0;
BA_ "GenSigSendType" SG_ 128 MO_Kickdown 7;
BA_ "NWM-WakeupAllowed" SG_ 128 MO_Kickdown 0;
BA_ "NMH-WakeupAllowed" SG_ 128 MO_Kickdown 0;
BA_ "GenSigTimeoutMsg_Gateway_B8" SG_ 128 MO_Kickdown 128;
BA_ "GenSigTimeoutMsg_Getriebe_AL6000" SG_ 128 MO_Kickdown 128;
BA_ "GenSigTimeoutMsg_Getriebe_DL5001" SG_ 128 MO_Kickdown 128;
BA_ "GenSigTimeoutMsg_Getriebe_VL3002" SG_ 128 MO_Kickdown 128;
BA_ "GenSigAutoGenDsp" SG_ 128 MO_KD_Fehler 1;
BA_ "GenSigAutoGenSnd" SG_ 128 MO_KD_Fehler 1;
BA_ "GenSigEnvVarType" SG_ 128 MO_KD_Fehler 0;
BA_ "GenSigSendType" SG_ 128 MO_KD_Fehler 7;
BA_ "NWM-WakeupAllowed" SG_ 128 MO_KD_Fehler 0;
BA_ "NMH-WakeupAllowed" SG_ 128 MO_KD_Fehler 0;
BA_ "GenSigTimeoutMsg_Gateway_B8" SG_ 128 MO_KD_Fehler 128;
BA_ "GenSigAutoGenDsp" SG_ 129 Motor_02_CHK 1;
BA_ "GenSigAutoGenSnd" SG_ 129 Motor_02_CHK 1;
BA_ "GenSigEnvVarType" SG_ 129 Motor_02_CHK 0;
BA_ "GenSigSendType" SG_ 129 Motor_02_CHK 7;
BA_ "NWM-WakeupAllowed" SG_ 129 Motor_02_CHK 0;
BA_ "NMH-WakeupAllowed" SG_ 129 Motor_02_CHK 0;
BA_ "GenSigTimeoutMsg_Gateway_B8" SG_ 129 Motor_02_CHK 129;
BA_ "GenSigTimeoutMsg_Getriebe_AL6000" SG_ 129 Motor_02_CHK 129;
BA_ "GenSigTimeoutMsg_Getriebe_DL5001" SG_ 129 Motor_02_CHK 129;
BA_ "GenSigTimeoutMsg_Getriebe_VL3002" SG_ 129 Motor_02_CHK 129;
BA_ "GenSigAutoGenDsp" SG_ 129 Motor_02_BZ 1;
BA_ "GenSigAutoGenSnd" SG_ 129 Motor_02_BZ 1;
BA_ "GenSigEnvVarType" SG_ 129 Motor_02_BZ 0;
BA_ "GenSigSendType" SG_ 129 Motor_02_BZ 7;
BA_ "NWM-WakeupAllowed" SG_ 129 Motor_02_BZ 0;
BA_ "NMH-WakeupAllowed" SG_ 129 Motor_02_BZ 0;
BA_ "GenSigTimeoutMsg_Gateway_B8" SG_ 129 Motor_02_BZ 129;
BA_ "GenSigTimeoutMsg_Getriebe_AL6000" SG_ 129 Motor_02_BZ 129;
BA_ "GenSigTimeoutMsg_Getriebe_DL5001" SG_ 129 Motor_02_BZ 129;
BA_ "GenSigTimeoutMsg_Getriebe_VL3002" SG_ 129 Motor_02_BZ 129;
BA_ "GenSigAutoGenDsp" SG_ 129 MO_Mom_ZWR 1;
BA_ "GenSigAutoGenSnd" SG_ 129 MO_Mom_ZWR 1;
BA_ "GenSigEnvVarType" SG_ 129 MO_Mom_ZWR 1;
BA_ "GenSigSendType" SG_ 129 MO_Mom_ZWR 7;
BA_ "GenSigStartValue" SG_ 129 MO_Mom_ZWR 1022;
BA_ "NWM-WakeupAllowed" SG_ 129 MO_Mom_ZWR 0;
BA_ "NMH-WakeupAllowed" SG_ 129 MO_Mom_ZWR 0;
BA_ "GenSigTimeoutMsg_Gateway_B8" SG_ 129 MO_Mom_ZWR 129;
BA_ "GenSigAutoGenDsp" SG_ 129 MO_Mom_Soll 1;
BA_ "GenSigAutoGenSnd" SG_ 129 MO_Mom_Soll 1;
BA_ "GenSigEnvVarType" SG_ 129 MO_Mom_Soll 1;
BA_ "GenSigSendType" SG_ 129 MO_Mom_Soll 7;
BA_ "GenSigStartValue" SG_ 129 MO_Mom_Soll 1022;
BA_ "NWM-WakeupAllowed" SG_ 129 MO_Mom_Soll 0;
BA_ "NMH-WakeupAllowed" SG_ 129 MO_Mom_Soll 0;
BA_ "GenSigTimeoutMsg_Gateway_B8" SG_ 129 MO_Mom_Soll 129;
BA_ "GenSigTimeoutMsg_Getriebe_AL6000" SG_ 129 MO_Mom_Soll 129;
BA_ "GenSigTimeoutMsg_Getriebe_DL5001" SG_ 129 MO_Mom_Soll 129;
BA_ "GenSigTimeoutMsg_Getriebe_VL3002" SG_ 129 MO_Mom_Soll 129;
BA_ "GenSigAutoGenDsp" SG_ 129 MO_Mom_Ist 1;
BA_ "GenSigAutoGenSnd" SG_ 129 MO_Mom_Ist 1;
BA_ "GenSigEnvVarType" SG_ 129 MO_Mom_Ist 1;
BA_ "GenSigSendType" SG_ 129 MO_Mom_Ist 7;
BA_ "GenSigStartValue" SG_ 129 MO_Mom_Ist 1022;
BA_ "NWM-WakeupAllowed" SG_ 129 MO_Mom_Ist 0;
BA_ "NMH-WakeupAllowed" SG_ 129 MO_Mom_Ist 0;
BA_ "GenSigTimeoutMsg_Gateway_B8" SG_ 129 MO_Mom_Ist 129;
BA_ "GenSigTimeoutMsg_Getriebe_AL6000" SG_ 129 MO_Mom_Ist 129;
BA_ "GenSigTimeoutMsg_Getriebe_DL5001" SG_ 129 MO_Mom_Ist 129;
BA_ "GenSigTimeoutMsg_Getriebe_VL3002" SG_ 129 MO_Mom_Ist 129;
BA_ "GenSigAutoGenDsp" SG_ 129 MO_Momentenintegral 1;
BA_ "GenSigAutoGenSnd" SG_ 129 MO_Momentenintegral 1;
BA_ "GenSigEnvVarType" SG_ 129 MO_Momentenintegral 1;
BA_ "GenSigSendType" SG_ 129 MO_Momentenintegral 7;
BA_ "NWM-WakeupAllowed" SG_ 129 MO_Momentenintegral 0;
BA_ "NMH-WakeupAllowed" SG_ 129 MO_Momentenintegral 0;
BA_ "GenSigTimeoutMsg_Gateway_B8" SG_ 129 MO_Momentenintegral 129;
BA_ "GenSigTimeoutMsg_Getriebe_AL6000" SG_ 129 MO_Momentenintegral 129;
BA_ "GenSigTimeoutMsg_Getriebe_DL5001" SG_ 129 MO_Momentenintegral 129;
BA_ "GenSigTimeoutMsg_Getriebe_VL3002" SG_ 129 MO_Momentenintegral 129;
BA_ "GenSigAutoGenDsp" SG_ 261 Motor_03_CHK 1;
BA_ "GenSigAutoGenSnd" SG_ 261 Motor_03_CHK 1;
BA_ "GenSigEnvVarType" SG_ 261 Motor_03_CHK 0;
BA_ "GenSigSendType" SG_ 261 Motor_03_CHK 7;
BA_ "NWM-WakeupAllowed" SG_ 261 Motor_03_CHK 0;
BA_ "NMH-WakeupAllowed" SG_ 261 Motor_03_CHK 0;
BA_ "GenSigTimeoutMsg_Daempfer_B8" SG_ 261 Motor_03_CHK 261;
BA_ "GenSigTimeoutMsg_Gateway_B8" SG_ 261 Motor_03_CHK 261;
BA_ "GenSigTimeoutMsg_Getriebe_AL6000" SG_ 261 Motor_03_CHK 261;
BA_ "GenSigTimeoutMsg_Getriebe_DL5001" SG_ 261 Motor_03_CHK 261;
BA_ "GenSigTimeoutMsg_Getriebe_VL3002" SG_ 261 Motor_03_CHK 261;
BA_ "GenSigAutoGenDsp" SG_ 261 Motor_03_BZ 1;
BA_ "GenSigAutoGenSnd" SG_ 261 Motor_03_BZ 1;
BA_ "GenSigEnvVarType" SG_ 261 Motor_03_BZ 0;
BA_ "GenSigSendType" SG_ 261 Motor_03_BZ 7;
BA_ "NWM-WakeupAllowed" SG_ 261 Motor_03_BZ 0;
BA_ "NMH-WakeupAllowed" SG_ 261 Motor_03_BZ 0;
BA_ "GenSigTimeoutMsg_Daempfer_B8" SG_ 261 Motor_03_BZ 261;
BA_ "GenSigTimeoutMsg_Gateway_B8" SG_ 261 Motor_03_BZ 261;
BA_ "GenSigTimeoutMsg_Getriebe_AL6000" SG_ 261 Motor_03_BZ 261;
BA_ "GenSigTimeoutMsg_Getriebe_DL5001" SG_ 261 Motor_03_BZ 261;
BA_ "GenSigTimeoutMsg_Getriebe_VL3002" SG_ 261 Motor_03_BZ 261;
BA_ "GenSigAutoGenDsp" SG_ 261 MO_QBit_Fahrpedalwerte_01 1;
BA_ "GenSigAutoGenSnd" SG_ 261 MO_QBit_Fahrpedalwerte_01 1;
BA_ "GenSigEnvVarType" SG_ 261 MO_QBit_Fahrpedalwerte_01 0;
BA_ "GenSigSendType" SG_ 261 MO_QBit_Fahrpedalwerte_01 7;
BA_ "GenSigStartValue" SG_ 261 MO_QBit_Fahrpedalwerte_01 1;
BA_ "NWM-WakeupAllowed" SG_ 261 MO_QBit_Fahrpedalwerte_01 0;
BA_ "NMH-WakeupAllowed" SG_ 261 MO_QBit_Fahrpedalwerte_01 0;
BA_ "GenSigTimeoutMsg_Gateway_B8" SG_ 261 MO_QBit_Fahrpedalwerte_01 261;
BA_ "GenSigAutoGenDsp" SG_ 261 MO_QBit_Motormomente 1;
BA_ "GenSigAutoGenSnd" SG_ 261 MO_QBit_Motormomente 1;
BA_ "GenSigEnvVarType" SG_ 261 MO_QBit_Motormomente 0;
BA_ "GenSigSendType" SG_ 261 MO_QBit_Motormomente 7;
BA_ "GenSigStartValue" SG_ 261 MO_QBit_Motormomente 1;
BA_ "NWM-WakeupAllowed" SG_ 261 MO_QBit_Motormomente 0;
BA_ "NMH-WakeupAllowed" SG_ 261 MO_QBit_Motormomente 0;
BA_ "GenSigTimeoutMsg_Gateway_B8" SG_ 261 MO_QBit_Motormomente 261;
BA_ "GenSigTimeoutMsg_Getriebe_AL6000" SG_ 261 MO_QBit_Motormomente 261;
BA_ "GenSigTimeoutMsg_Getriebe_DL5001" SG_ 261 MO_QBit_Motormomente 261;
BA_ "GenSigTimeoutMsg_Getriebe_VL3002" SG_ 261 MO_QBit_Motormomente 261;
BA_ "GenSigAutoGenDsp" SG_ 261 MO_QBit_Fahrer_bremst 1;
BA_ "GenSigAutoGenSnd" SG_ 261 MO_QBit_Fahrer_bremst 1;
BA_ "GenSigSendType" SG_ 261 MO_QBit_Fahrer_bremst 7;
BA_ "GenSigStartValue" SG_ 261 MO_QBit_Fahrer_bremst 1;
BA_ "NWM-WakeupAllowed" SG_ 261 MO_QBit_Fahrer_bremst 0;
BA_ "NMH-WakeupAllowed" SG_ 261 MO_QBit_Fahrer_bremst 0;
BA_ "GenSigTimeoutMsg_Gateway_B8" SG_ 261 MO_QBit_Fahrer_bremst 261;
BA_ "GenSigTimeoutMsg_Getriebe_AL6000" SG_ 261 MO_QBit_Fahrer_bremst 261;
BA_ "GenSigTimeoutMsg_Getriebe_DL5001" SG_ 261 MO_QBit_Fahrer_bremst 261;
BA_ "GenSigTimeoutMsg_Getriebe_VL3002" SG_ 261 MO_QBit_Fahrer_bremst 261;
BA_ "GenSigAutoGenDsp" SG_ 261 MO_QBit_Drehzahl_01 1;
BA_ "GenSigAutoGenSnd" SG_ 261 MO_QBit_Drehzahl_01 1;
BA_ "GenSigSendType" SG_ 261 MO_QBit_Drehzahl_01 7;
BA_ "GenSigStartValue" SG_ 261 MO_QBit_Drehzahl_01 1;
BA_ "NWM-WakeupAllowed" SG_ 261 MO_QBit_Drehzahl_01 0;
BA_ "NMH-WakeupAllowed" SG_ 261 MO_QBit_Drehzahl_01 0;
BA_ "GenSigTimeoutMsg_Gateway_B8" SG_ 261 MO_QBit_Drehzahl_01 261;
BA_ "GenSigAutoGenDsp" SG_ 261 MO_Drehzahl_01 1;
BA_ "GenSigAutoGenSnd" SG_ 261 MO_Drehzahl_01 1;
BA_ "GenSigEnvVarType" SG_ 261 MO_Drehzahl_01 1;
BA_ "GenSigSendType" SG_ 261 MO_Drehzahl_01 7;
BA_ "NWM-WakeupAllowed" SG_ 261 MO_Drehzahl_01 0;
BA_ "NMH-WakeupAllowed" SG_ 261 MO_Drehzahl_01 0;
BA_ "GenSigTimeoutMsg_AFS_B8" SG_ 261 MO_Drehzahl_01 261;
BA_ "GenSigTimeoutMsg_Gateway_B8" SG_ 261 MO_Drehzahl_01 261;
BA_ "GenSigTimeoutMsg_LWR_B8" SG_ 261 MO_Drehzahl_01 261;
BA_ "GenSigAutoGenDsp" SG_ 261 MO_Moment_im_Leerlauf 1;
BA_ "GenSigAutoGenSnd" SG_ 261 MO_Moment_im_Leerlauf 1;
BA_ "GenSigEnvVarType" SG_ 261 MO_Moment_im_Leerlauf 0;
BA_ "GenSigSendType" SG_ 261 MO_Moment_im_Leerlauf 7;
BA_ "NWM-WakeupAllowed" SG_ 261 MO_Moment_im_Leerlauf 0;
BA_ "NMH-WakeupAllowed" SG_ 261 MO_Moment_im_Leerlauf 0;
BA_ "GenSigTimeoutMsg_Gateway_B8" SG_ 261 MO_Moment_im_Leerlauf 261;
BA_ "GenSigAutoGenDsp" SG_ 261 MO_Interlock 1;
BA_ "GenSigAutoGenSnd" SG_ 261 MO_Interlock 1;
BA_ "GenSigEnvVarType" SG_ 261 MO_Interlock 0;
BA_ "GenSigSendType" SG_ 261 MO_Interlock 7;
BA_ "NWM-WakeupAllowed" SG_ 261 MO_Interlock 0;
BA_ "NMH-WakeupAllowed" SG_ 261 MO_Interlock 0;
BA_ "GenSigTimeoutMsg_Gateway_B8" SG_ 261 MO_Interlock 261;
BA_ "GenSigAutoGenDsp" SG_ 261 MO_BLS 1;
BA_ "GenSigAutoGenSnd" SG_ 261 MO_BLS 1;
BA_ "GenSigEnvVarType" SG_ 261 MO_BLS 0;
BA_ "GenSigSendType" SG_ 261 MO_BLS 7;
BA_ "NWM-WakeupAllowed" SG_ 261 MO_BLS 0;
BA_ "NMH-WakeupAllowed" SG_ 261 MO_BLS 0;
BA_ "GenSigTimeoutMsg_AFS_B8" SG_ 261 MO_BLS 261;
BA_ "GenSigTimeoutMsg_Daempfer_B8" SG_ 261 MO_BLS 261;
BA_ "GenSigTimeoutMsg_Gateway_B8" SG_ 261 MO_BLS 261;
BA_ "GenSigTimeoutMsg_Getriebe_AL6000" SG_ 261 MO_BLS 261;
BA_ "GenSigTimeoutMsg_Getriebe_DL5001" SG_ 261 MO_BLS 261;
BA_ "GenSigTimeoutMsg_Getriebe_VL3002" SG_ 261 MO_BLS 261;
BA_ "GenSigTimeoutMsg_LWR_B8" SG_ 261 MO_BLS 261;
BA_ "GenSigAutoGenDsp" SG_ 261 MO_Fahrer_bremst 1;
BA_ "GenSigAutoGenSnd" SG_ 261 MO_Fahrer_bremst 1;
BA_ "GenSigEnvVarType" SG_ 261 MO_Fahrer_bremst 0;
BA_ "GenSigSendType" SG_ 261 MO_Fahrer_bremst 7;
BA_ "NWM-WakeupAllowed" SG_ 261 MO_Fahrer_bremst 0;
BA_ "NMH-WakeupAllowed" SG_ 261 MO_Fahrer_bremst 0;
BA_ "GenSigTimeoutMsg_Gateway_B8" SG_ 261 MO_Fahrer_bremst 261;
BA_ "GenSigTimeoutMsg_Getriebe_AL6000" SG_ 261 MO_Fahrer_bremst 261;
BA_ "GenSigTimeoutMsg_Getriebe_DL5001" SG_ 261 MO_Fahrer_bremst 261;
BA_ "GenSigTimeoutMsg_Getriebe_VL3002" SG_ 261 MO_Fahrer_bremst 261;
BA_ "GenSigAutoGenDsp" SG_ 261 MO_Konsistenz_Bremsped 1;
BA_ "GenSigAutoGenSnd" SG_ 261 MO_Konsistenz_Bremsped 1;
BA_ "GenSigEnvVarType" SG_ 261 MO_Konsistenz_Bremsped 0;
BA_ "GenSigSendType" SG_ 261 MO_Konsistenz_Bremsped 7;
BA_ "NWM-WakeupAllowed" SG_ 261 MO_Konsistenz_Bremsped 0;
BA_ "NMH-WakeupAllowed" SG_ 261 MO_Konsistenz_Bremsped 0;
BA_ "GenSigTimeoutMsg_Gateway_B8" SG_ 261 MO_Konsistenz_Bremsped 261;
BA_ "GenSigTimeoutMsg_Getriebe_AL6000" SG_ 261 MO_Konsistenz_Bremsped 261;
BA_ "GenSigTimeoutMsg_Getriebe_DL5001" SG_ 261 MO_Konsistenz_Bremsped 261;
BA_ "GenSigTimeoutMsg_Getriebe_VL3002" SG_ 261 MO_Konsistenz_Bremsped 261;
BA_ "GenSigAutoGenDsp" SG_ 261 MO_Kuppl_schalter 1;
BA_ "GenSigAutoGenSnd" SG_ 261 MO_Kuppl_schalter 1;
BA_ "GenSigEnvVarType" SG_ 261 MO_Kuppl_schalter 0;
BA_ "GenSigSendType" SG_ 261 MO_Kuppl_schalter 7;
BA_ "NWM-WakeupAllowed" SG_ 261 MO_Kuppl_schalter 0;
BA_ "NMH-WakeupAllowed" SG_ 261 MO_Kuppl_schalter 0;
BA_ "GenSigTimeoutMsg_Gateway_B8" SG_ 261 MO_Kuppl_schalter 261;
BA_ "GenSigAutoGenDsp" SG_ 261 MO_Timeout_ESP 1;
BA_ "GenSigAutoGenSnd" SG_ 261 MO_Timeout_ESP 1;
BA_ "GenSigEnvVarType" SG_ 261 MO_Timeout_ESP 0;
BA_ "GenSigSendType" SG_ 261 MO_Timeout_ESP 7;
BA_ "NWM-WakeupAllowed" SG_ 261 MO_Timeout_ESP 0;
BA_ "NMH-WakeupAllowed" SG_ 261 MO_Timeout_ESP 0;
BA_ "GenSigTimeoutMsg_Gateway_B8" SG_ 261 MO_Timeout_ESP 261;
BA_ "GenSigAutoGenDsp" SG_ 261 MO_Motor_laeuft 1;
BA_ "GenSigAutoGenSnd" SG_ 261 MO_Motor_laeuft 1;
BA_ "GenSigEnvVarType" SG_ 261 MO_Motor_laeuft 0;
BA_ "GenSigSendType" SG_ 261 MO_Motor_laeuft 7;
BA_ "NWM-WakeupAllowed" SG_ 261 MO_Motor_laeuft 0;
BA_ "NMH-WakeupAllowed" SG_ 261 MO_Motor_laeuft 0;
BA_ "GenSigTimeoutMsg_Gateway_B8" SG_ 261 MO_Motor_laeuft 261;
BA_ "GenSigAutoGenDsp" SG_ 261 MO_Solldrehz_Leerlauf 1;
BA_ "GenSigAutoGenSnd" SG_ 261 MO_Solldrehz_Leerlauf 1;
BA_ "GenSigEnvVarType" SG_ 261 MO_Solldrehz_Leerlauf 1;
BA_ "GenSigSendType" SG_ 261 MO_Solldrehz_Leerlauf 7;
BA_ "NWM-WakeupAllowed" SG_ 261 MO_Solldrehz_Leerlauf 0;
BA_ "NMH-WakeupAllowed" SG_ 261 MO_Solldrehz_Leerlauf 0;
BA_ "GenSigTimeoutMsg_Gateway_B8" SG_ 261 MO_Solldrehz_Leerlauf 261;
BA_ "GenSigTimeoutMsg_Getriebe_AL6000" SG_ 261 MO_Solldrehz_Leerlauf 261;
BA_ "GenSigTimeoutMsg_Getriebe_DL5001" SG_ 261 MO_Solldrehz_Leerlauf 261;
BA_ "GenSigTimeoutMsg_Getriebe_VL3002" SG_ 261 MO_Solldrehz_Leerlauf 261;
BA_ "GenSigAutoGenDsp" SG_ 261 MO_Fahrpedalrohwert_01 1;
BA_ "GenSigAutoGenSnd" SG_ 261 MO_Fahrpedalrohwert_01 1;
BA_ "GenSigEnvVarType" SG_ 261 MO_Fahrpedalrohwert_01 1;
BA_ "GenSigSendType" SG_ 261 MO_Fahrpedalrohwert_01 7;
BA_ "NWM-WakeupAllowed" SG_ 261 MO_Fahrpedalrohwert_01 0;
BA_ "NMH-WakeupAllowed" SG_ 261 MO_Fahrpedalrohwert_01 0;
BA_ "GenSigTimeoutMsg_Gateway_B8" SG_ 261 MO_Fahrpedalrohwert_01 261;
BA_ "GenSigAutoGenDsp" SG_ 261 MO_erste_Ungenauschwelle 1;
BA_ "GenSigAutoGenSnd" SG_ 261 MO_erste_Ungenauschwelle 1;
BA_ "GenSigSendType" SG_ 261 MO_erste_Ungenauschwelle 7;
BA_ "NWM-WakeupAllowed" SG_ 261 MO_erste_Ungenauschwelle 0;
BA_ "NMH-WakeupAllowed" SG_ 261 MO_erste_Ungenauschwelle 0;
BA_ "GenSigTimeoutMsg_Gateway_B8" SG_ 261 MO_erste_Ungenauschwelle 261;
BA_ "GenSigTimeoutMsg_Getriebe_AL6000" SG_ 261 MO_erste_Ungenauschwelle 261;
BA_ "GenSigTimeoutMsg_Getriebe_DL5001" SG_ 261 MO_erste_Ungenauschwelle 261;
BA_ "GenSigTimeoutMsg_Getriebe_VL3002" SG_ 261 MO_erste_Ungenauschwelle 261;
BA_ "GenSigAutoGenDsp" SG_ 261 MO_QBit_Stressfaktor 1;
BA_ "GenSigAutoGenSnd" SG_ 261 MO_QBit_Stressfaktor 1;
BA_ "GenSigSendType" SG_ 261 MO_QBit_Stressfaktor 7;
BA_ "GenSigStartValue" SG_ 261 MO_QBit_Stressfaktor 1;
BA_ "NWM-WakeupAllowed" SG_ 261 MO_QBit_Stressfaktor 0;
BA_ "NMH-WakeupAllowed" SG_ 261 MO_QBit_Stressfaktor 0;
BA_ "GenSigTimeoutMsg_Gateway_B8" SG_ 261 MO_QBit_Stressfaktor 261;
BA_ "GenSigTimeoutMsg_Getriebe_AL6000" SG_ 261 MO_QBit_Stressfaktor 261;
BA_ "GenSigTimeoutMsg_Getriebe_DL5001" SG_ 261 MO_QBit_Stressfaktor 261;
BA_ "GenSigTimeoutMsg_Getriebe_VL3002" SG_ 261 MO_QBit_Stressfaktor 261;
BA_ "GenSigAutoGenDsp" SG_ 261 MO_Stressfaktor 1;
BA_ "GenSigAutoGenSnd" SG_ 261 MO_Stressfaktor 1;
BA_ "GenSigSendType" SG_ 261 MO_Stressfaktor 7;
BA_ "NWM-WakeupAllowed" SG_ 261 MO_Stressfaktor 0;
BA_ "NMH-WakeupAllowed" SG_ 261 MO_Stressfaktor 0;
BA_ "GenSigTimeoutMsg_Gateway_B8" SG_ 261 MO_Stressfaktor 261;
BA_ "GenSigTimeoutMsg_Getriebe_AL6000" SG_ 261 MO_Stressfaktor 261;
BA_ "GenSigTimeoutMsg_Getriebe_DL5001" SG_ 261 MO_Stressfaktor 261;
BA_ "GenSigTimeoutMsg_Getriebe_VL3002" SG_ 261 MO_Stressfaktor 261;
BA_ "GenSigAutoGenDsp" SG_ 263 MO_Anzeigedrehz 1;
BA_ "GenSigAutoGenSnd" SG_ 263 MO_Anzeigedrehz 1;
BA_ "GenSigEnvVarType" SG_ 263 MO_Anzeigedrehz 1;
BA_ "GenSigSendType" SG_ 263 MO_Anzeigedrehz 7;
BA_ "NWM-WakeupAllowed" SG_ 263 MO_Anzeigedrehz 0;
BA_ "NMH-WakeupAllowed" SG_ 263 MO_Anzeigedrehz 0;
BA_ "GenSigTimeoutMsg_Gateway_B8" SG_ 263 MO_Anzeigedrehz 263;
BA_ "GenSigAutoGenDsp" SG_ 263 MO_Ladedruck 1;
BA_ "GenSigAutoGenSnd" SG_ 263 MO_Ladedruck 1;
BA_ "GenSigEnvVarType" SG_ 263 MO_Ladedruck 1;
BA_ "GenSigSendType" SG_ 263 MO_Ladedruck 7;
BA_ "NWM-WakeupAllowed" SG_ 263 MO_Ladedruck 0;
BA_ "NMH-WakeupAllowed" SG_ 263 MO_Ladedruck 0;
BA_ "GenSigTimeoutMsg_Gateway_B8" SG_ 263 MO_Ladedruck 263;
BA_ "GenSigAutoGenDsp" SG_ 263 MO_KVS 1;
BA_ "GenSigAutoGenSnd" SG_ 263 MO_KVS 1;
BA_ "GenSigEnvVarType" SG_ 263 MO_KVS 1;
BA_ "GenSigSendType" SG_ 263 MO_KVS 7;
BA_ "NWM-WakeupAllowed" SG_ 263 MO_KVS 0;
BA_ "NMH-WakeupAllowed" SG_ 263 MO_KVS 0;
BA_ "GenSigTimeoutMsg_Gateway_B8" SG_ 263 MO_KVS 263;
BA_ "GenSigAutoGenDsp" SG_ 263 MO_KVS_Ueberlauf 1;
BA_ "GenSigAutoGenSnd" SG_ 263 MO_KVS_Ueberlauf 1;
BA_ "GenSigEnvVarType" SG_ 263 MO_KVS_Ueberlauf 0;
BA_ "GenSigSendType" SG_ 263 MO_KVS_Ueberlauf 7;
BA_ "NWM-WakeupAllowed" SG_ 263 MO_KVS_Ueberlauf 0;
BA_ "NMH-WakeupAllowed" SG_ 263 MO_KVS_Ueberlauf 0;
BA_ "GenSigTimeoutMsg_Gateway_B8" SG_ 263 MO_KVS_Ueberlauf 263;
BA_ "GenSigAutoGenDsp" SG_ 782 Motor_05_CHK 1;
BA_ "GenSigAutoGenSnd" SG_ 782 Motor_05_CHK 1;
BA_ "GenSigEnvVarType" SG_ 782 Motor_05_CHK 0;
BA_ "GenSigSendType" SG_ 782 Motor_05_CHK 7;
BA_ "NWM-WakeupAllowed" SG_ 782 Motor_05_CHK 0;
BA_ "NMH-WakeupAllowed" SG_ 782 Motor_05_CHK 0;
BA_ "GenSigTimeoutMsg_Getriebe_AL6000" SG_ 782 Motor_05_CHK 782;
BA_ "GenSigTimeoutMsg_Getriebe_DL5001" SG_ 782 Motor_05_CHK 782;
BA_ "GenSigTimeoutMsg_Getriebe_VL3002" SG_ 782 Motor_05_CHK 782;
BA_ "GenSigAutoGenDsp" SG_ 782 Motor_05_BZ 1;
BA_ "GenSigAutoGenSnd" SG_ 782 Motor_05_BZ 1;
BA_ "GenSigEnvVarType" SG_ 782 Motor_05_BZ 0;
BA_ "GenSigSendType" SG_ 782 Motor_05_BZ 7;
BA_ "NWM-WakeupAllowed" SG_ 782 Motor_05_BZ 0;
BA_ "NMH-WakeupAllowed" SG_ 782 Motor_05_BZ 0;
BA_ "GenSigTimeoutMsg_Getriebe_AL6000" SG_ 782 Motor_05_BZ 782;
BA_ "GenSigTimeoutMsg_Getriebe_DL5001" SG_ 782 Motor_05_BZ 782;
BA_ "GenSigTimeoutMsg_Getriebe_VL3002" SG_ 782 Motor_05_BZ 782;
BA_ "GenSigAutoGenDsp" SG_ 782 MO_Klima_Eingr 1;
BA_ "GenSigAutoGenSnd" SG_ 782 MO_Klima_Eingr 1;
BA_ "GenSigEnvVarType" SG_ 782 MO_Klima_Eingr 0;
BA_ "GenSigSendType" SG_ 782 MO_Klima_Eingr 7;
BA_ "NWM-WakeupAllowed" SG_ 782 MO_Klima_Eingr 0;
BA_ "NMH-WakeupAllowed" SG_ 782 MO_Klima_Eingr 0;
BA_ "GenSigTimeoutMsg_Gateway_B8" SG_ 782 MO_Klima_Eingr 782;
BA_ "GenSigAutoGenDsp" SG_ 782 MO_Status_Normalbetrieb 1;
BA_ "GenSigAutoGenSnd" SG_ 782 MO_Status_Normalbetrieb 1;
BA_ "GenSigSendType" SG_ 782 MO_Status_Normalbetrieb 7;
BA_ "NWM-WakeupAllowed" SG_ 782 MO_Status_Normalbetrieb 0;
BA_ "NMH-WakeupAllowed" SG_ 782 MO_Status_Normalbetrieb 0;
BA_ "GenSigTimeoutMsg_Getriebe_AL6000" SG_ 782 MO_Status_Normalbetrieb 782;
BA_ "GenSigTimeoutMsg_Getriebe_DL5001" SG_ 782 MO_Status_Normalbetrieb 782;
BA_ "GenSigAutoGenDsp" SG_ 782 MO_Schaltbeeinfl_Leistungsbegr 1;
BA_ "GenSigAutoGenSnd" SG_ 782 MO_Schaltbeeinfl_Leistungsbegr 1;
BA_ "GenSigEnvVarType" SG_ 782 MO_Schaltbeeinfl_Leistungsbegr 0;
BA_ "GenSigSendType" SG_ 782 MO_Schaltbeeinfl_Leistungsbegr 7;
BA_ "NWM-WakeupAllowed" SG_ 782 MO_Schaltbeeinfl_Leistungsbegr 0;
BA_ "NMH-WakeupAllowed" SG_ 782 MO_Schaltbeeinfl_Leistungsbegr 0;
BA_ "GenSigTimeoutMsg_Getriebe_AL6000" SG_ 782 MO_Schaltbeeinfl_Leistungsbegr 782;
BA_ "GenSigTimeoutMsg_Getriebe_DL5001" SG_ 782 MO_Schaltbeeinfl_Leistungsbegr 782;
BA_ "GenSigAutoGenDsp" SG_ 782 MO_Schaltbeeinfl_Partikelfilter 1;
BA_ "GenSigAutoGenSnd" SG_ 782 MO_Schaltbeeinfl_Partikelfilter 1;
BA_ "GenSigEnvVarType" SG_ 782 MO_Schaltbeeinfl_Partikelfilter 0;
BA_ "GenSigSendType" SG_ 782 MO_Schaltbeeinfl_Partikelfilter 7;
BA_ "NWM-WakeupAllowed" SG_ 782 MO_Schaltbeeinfl_Partikelfilter 0;
BA_ "NMH-WakeupAllowed" SG_ 782 MO_Schaltbeeinfl_Partikelfilter 0;
BA_ "GenSigTimeoutMsg_Getriebe_AL6000" SG_ 782 MO_Schaltbeeinfl_Partikelfilter 782;
BA_ "GenSigTimeoutMsg_Getriebe_DL5001" SG_ 782 MO_Schaltbeeinfl_Partikelfilter 782;
BA_ "GenSigAutoGenDsp" SG_ 782 MO_Prio_MIN_Wunschdrehzahl 1;
BA_ "GenSigAutoGenSnd" SG_ 782 MO_Prio_MIN_Wunschdrehzahl 1;
BA_ "GenSigEnvVarType" SG_ 782 MO_Prio_MIN_Wunschdrehzahl 0;
BA_ "GenSigSendType" SG_ 782 MO_Prio_MIN_Wunschdrehzahl 7;
BA_ "NWM-WakeupAllowed" SG_ 782 MO_Prio_MIN_Wunschdrehzahl 0;
BA_ "NMH-WakeupAllowed" SG_ 782 MO_Prio_MIN_Wunschdrehzahl 0;
BA_ "GenSigTimeoutMsg_Getriebe_AL6000" SG_ 782 MO_Prio_MIN_Wunschdrehzahl 782;
BA_ "GenSigTimeoutMsg_Getriebe_DL5001" SG_ 782 MO_Prio_MIN_Wunschdrehzahl 782;
BA_ "GenSigTimeoutMsg_Getriebe_VL3002" SG_ 782 MO_Prio_MIN_Wunschdrehzahl 782;
BA_ "GenSigAutoGenDsp" SG_ 782 MO_Freig_Anlass 1;
BA_ "GenSigAutoGenSnd" SG_ 782 MO_Freig_Anlass 1;
BA_ "GenSigEnvVarType" SG_ 782 MO_Freig_Anlass 0;
BA_ "GenSigSendType" SG_ 782 MO_Freig_Anlass 7;
BA_ "NWM-WakeupAllowed" SG_ 782 MO_Freig_Anlass 0;
BA_ "NMH-WakeupAllowed" SG_ 782 MO_Freig_Anlass 0;
BA_ "GenSigTimeoutMsg_Gateway_B8" SG_ 782 MO_Freig_Anlass 782;
BA_ "GenSigAutoGenDsp" SG_ 782 MO_Aussp_Anlass 1;
BA_ "GenSigAutoGenSnd" SG_ 782 MO_Aussp_Anlass 1;
BA_ "GenSigEnvVarType" SG_ 782 MO_Aussp_Anlass 0;
BA_ "GenSigSendType" SG_ 782 MO_Aussp_Anlass 7;
BA_ "NWM-WakeupAllowed" SG_ 782 MO_Aussp_Anlass 0;
BA_ "NMH-WakeupAllowed" SG_ 782 MO_Aussp_Anlass 0;
BA_ "GenSigTimeoutMsg_Gateway_B8" SG_ 782 MO_Aussp_Anlass 782;
BA_ "GenSigAutoGenDsp" SG_ 782 MO_MAX_Wunschdrehzahl 1;
BA_ "GenSigAutoGenSnd" SG_ 782 MO_MAX_Wunschdrehzahl 1;
BA_ "GenSigEnvVarType" SG_ 782 MO_MAX_Wunschdrehzahl 1;
BA_ "GenSigSendType" SG_ 782 MO_MAX_Wunschdrehzahl 7;
BA_ "NWM-WakeupAllowed" SG_ 782 MO_MAX_Wunschdrehzahl 0;
BA_ "NMH-WakeupAllowed" SG_ 782 MO_MAX_Wunschdrehzahl 0;
BA_ "GenSigTimeoutMsg_Getriebe_AL6000" SG_ 782 MO_MAX_Wunschdrehzahl 782;
BA_ "GenSigTimeoutMsg_Getriebe_DL5001" SG_ 782 MO_MAX_Wunschdrehzahl 782;
BA_ "GenSigTimeoutMsg_Getriebe_VL3002" SG_ 782 MO_MAX_Wunschdrehzahl 782;
BA_ "GenSigAutoGenDsp" SG_ 782 MO_Prio_MAX_Wunschdrehzahl 1;
BA_ "GenSigAutoGenSnd" SG_ 782 MO_Prio_MAX_Wunschdrehzahl 1;
BA_ "GenSigEnvVarType" SG_ 782 MO_Prio_MAX_Wunschdrehzahl 0;
BA_ "GenSigSendType" SG_ 782 MO_Prio_MAX_Wunschdrehzahl 7;
BA_ "NWM-WakeupAllowed" SG_ 782 MO_Prio_MAX_Wunschdrehzahl 0;
BA_ "NMH-WakeupAllowed" SG_ 782 MO_Prio_MAX_Wunschdrehzahl 0;
BA_ "GenSigTimeoutMsg_Getriebe_AL6000" SG_ 782 MO_Prio_MAX_Wunschdrehzahl 782;
BA_ "GenSigTimeoutMsg_Getriebe_DL5001" SG_ 782 MO_Prio_MAX_Wunschdrehzahl 782;
BA_ "GenSigTimeoutMsg_Getriebe_VL3002" SG_ 782 MO_Prio_MAX_Wunschdrehzahl 782;
BA_ "GenSigAutoGenDsp" SG_ 782 MO_Luftpfad_aktiv 1;
BA_ "GenSigAutoGenSnd" SG_ 782 MO_Luftpfad_aktiv 1;
BA_ "GenSigSendType" SG_ 782 MO_Luftpfad_aktiv 7;
BA_ "NWM-WakeupAllowed" SG_ 782 MO_Luftpfad_aktiv 0;
BA_ "NMH-WakeupAllowed" SG_ 782 MO_Luftpfad_aktiv 0;
BA_ "GenSigTimeoutMsg_Getriebe_AL6000" SG_ 782 MO_Luftpfad_aktiv 782;
BA_ "GenSigTimeoutMsg_Getriebe_DL5001" SG_ 782 MO_Luftpfad_aktiv 782;
BA_ "GenSigAutoGenDsp" SG_ 782 MO_v_Begrenz_Aktiv 1;
BA_ "GenSigAutoGenSnd" SG_ 782 MO_v_Begrenz_Aktiv 1;
BA_ "GenSigEnvVarType" SG_ 782 MO_v_Begrenz_Aktiv 0;
BA_ "GenSigSendType" SG_ 782 MO_v_Begrenz_Aktiv 7;
BA_ "NWM-WakeupAllowed" SG_ 782 MO_v_Begrenz_Aktiv 0;
BA_ "NMH-WakeupAllowed" SG_ 782 MO_v_Begrenz_Aktiv 0;
BA_ "GenSigAutoGenDsp" SG_ 782 MO_v_Begrenz_Aktivierbar 1;
BA_ "GenSigAutoGenSnd" SG_ 782 MO_v_Begrenz_Aktivierbar 1;
BA_ "GenSigEnvVarType" SG_ 782 MO_v_Begrenz_Aktivierbar 0;
BA_ "GenSigSendType" SG_ 782 MO_v_Begrenz_Aktivierbar 7;
BA_ "NWM-WakeupAllowed" SG_ 782 MO_v_Begrenz_Aktivierbar 0;
BA_ "NMH-WakeupAllowed" SG_ 782 MO_v_Begrenz_Aktivierbar 0;
BA_ "GenSigAutoGenDsp" SG_ 782 MO_Verbot_EKP 1;
BA_ "GenSigAutoGenSnd" SG_ 782 MO_Verbot_EKP 1;
BA_ "GenSigEnvVarType" SG_ 782 MO_Verbot_EKP 0;
BA_ "GenSigSendType" SG_ 782 MO_Verbot_EKP 7;
BA_ "NWM-WakeupAllowed" SG_ 782 MO_Verbot_EKP 0;
BA_ "NMH-WakeupAllowed" SG_ 782 MO_Verbot_EKP 0;
BA_ "GenSigTimeoutMsg_Gateway_B8" SG_ 782 MO_Verbot_EKP 782;
BA_ "GenSigAutoGenDsp" SG_ 782 MO_Anf_Pruefimpuls 1;
BA_ "GenSigAutoGenSnd" SG_ 782 MO_Anf_Pruefimpuls 1;
BA_ "GenSigEnvVarType" SG_ 782 MO_Anf_Pruefimpuls 0;
BA_ "GenSigSendType" SG_ 782 MO_Anf_Pruefimpuls 7;
BA_ "NWM-WakeupAllowed" SG_ 782 MO_Anf_Pruefimpuls 0;
BA_ "NMH-WakeupAllowed" SG_ 782 MO_Anf_Pruefimpuls 0;
BA_ "GenSigTimeoutMsg_Gateway_B8" SG_ 782 MO_Anf_Pruefimpuls 782;
BA_ "GenSigAutoGenDsp" SG_ 782 MO_Anf_KL75 1;
BA_ "GenSigAutoGenSnd" SG_ 782 MO_Anf_KL75 1;
BA_ "GenSigSendType" SG_ 782 MO_Anf_KL75 7;
BA_ "GenSigStartValue" SG_ 782 MO_Anf_KL75 1;
BA_ "NWM-WakeupAllowed" SG_ 782 MO_Anf_KL75 0;
BA_ "NMH-WakeupAllowed" SG_ 782 MO_Anf_KL75 0;
BA_ "GenSigTimeoutMsg_Gateway_B8" SG_ 782 MO_Anf_KL75 782;
BA_ "GenSigAutoGenDsp" SG_ 782 MO_Charisma_FahrPr 1;
BA_ "GenSigAutoGenSnd" SG_ 782 MO_Charisma_FahrPr 1;
BA_ "GenSigSendType" SG_ 782 MO_Charisma_FahrPr 7;
BA_ "NWM-WakeupAllowed" SG_ 782 MO_Charisma_FahrPr 0;
BA_ "NMH-WakeupAllowed" SG_ 782 MO_Charisma_FahrPr 0;
BA_ "GenSigTimeoutMsg_Gateway_B8" SG_ 782 MO_Charisma_FahrPr 782;
BA_ "GenSigAutoGenDsp" SG_ 782 MO_Charisma_Status 1;
BA_ "GenSigAutoGenSnd" SG_ 782 MO_Charisma_Status 1;
BA_ "GenSigSendType" SG_ 782 MO_Charisma_Status 7;
BA_ "NWM-WakeupAllowed" SG_ 782 MO_Charisma_Status 0;
BA_ "NMH-WakeupAllowed" SG_ 782 MO_Charisma_Status 0;
BA_ "GenSigTimeoutMsg_Gateway_B8" SG_ 782 MO_Charisma_Status 782;
BA_ "GenSigAutoGenDsp" SG_ 782 MO_Charisma_Umschaltung 1;
BA_ "GenSigAutoGenSnd" SG_ 782 MO_Charisma_Umschaltung 1;
BA_ "GenSigSendType" SG_ 782 MO_Charisma_Umschaltung 7;
BA_ "NWM-WakeupAllowed" SG_ 782 MO_Charisma_Umschaltung 0;
BA_ "NMH-WakeupAllowed" SG_ 782 MO_Charisma_Umschaltung 0;
BA_ "GenSigTimeoutMsg_Gateway_B8" SG_ 782 MO_Charisma_Umschaltung 782;
BA_ "GenSigAutoGenDsp" SG_ 782 MO_Handshake_STH 1;
BA_ "GenSigAutoGenSnd" SG_ 782 MO_Handshake_STH 1;
BA_ "GenSigSendType" SG_ 782 MO_Handshake_STH 7;
BA_ "NWM-WakeupAllowed" SG_ 782 MO_Handshake_STH 0;
BA_ "NMH-WakeupAllowed" SG_ 782 MO_Handshake_STH 0;
BA_ "GenSigTimeoutMsg_Gateway_B8" SG_ 782 MO_Handshake_STH 782;
BA_ "GenSigAutoGenDsp" SG_ 782 MO_MIN_Wunschdrehzahl 1;
BA_ "GenSigAutoGenSnd" SG_ 782 MO_MIN_Wunschdrehzahl 1;
BA_ "GenSigSendType" SG_ 782 MO_MIN_Wunschdrehzahl 7;
BA_ "NWM-WakeupAllowed" SG_ 782 MO_MIN_Wunschdrehzahl 0;
BA_ "NMH-WakeupAllowed" SG_ 782 MO_MIN_Wunschdrehzahl 0;
BA_ "GenSigTimeoutMsg_Getriebe_AL6000" SG_ 782 MO_MIN_Wunschdrehzahl 782;
BA_ "GenSigTimeoutMsg_Getriebe_DL5001" SG_ 782 MO_MIN_Wunschdrehzahl 782;
BA_ "GenSigTimeoutMsg_Getriebe_VL3002" SG_ 782 MO_MIN_Wunschdrehzahl 782;
BA_ "GenSigAutoGenDsp" SG_ 782 MO_Drehzahlbeeinflussung 1;
BA_ "GenSigAutoGenSnd" SG_ 782 MO_Drehzahlbeeinflussung 1;
BA_ "GenSigEnvVarType" SG_ 782 MO_Drehzahlbeeinflussung 1;
BA_ "GenSigSendType" SG_ 782 MO_Drehzahlbeeinflussung 7;
BA_ "NWM-WakeupAllowed" SG_ 782 MO_Drehzahlbeeinflussung 0;
BA_ "NMH-WakeupAllowed" SG_ 782 MO_Drehzahlbeeinflussung 0;
BA_ "GenSigTimeoutMsg_Getriebe_AL6000" SG_ 782 MO_Drehzahlbeeinflussung 782;
BA_ "GenSigTimeoutMsg_Getriebe_DL5001" SG_ 782 MO_Drehzahlbeeinflussung 782;
BA_ "GenSigTimeoutMsg_Getriebe_VL3002" SG_ 782 MO_Drehzahlbeeinflussung 782;
BA_ "GenSigAutoGenDsp" SG_ 1088 WIV_Anzeige_aktiv 1;
BA_ "GenSigAutoGenSnd" SG_ 1088 WIV_Anzeige_aktiv 1;
BA_ "GenSigEnvVarType" SG_ 1088 WIV_Anzeige_aktiv 0;
BA_ "GenSigSendType" SG_ 1088 WIV_Anzeige_aktiv 7;
BA_ "NWM-WakeupAllowed" SG_ 1088 WIV_Anzeige_aktiv 0;
BA_ "NMH-WakeupAllowed" SG_ 1088 WIV_Anzeige_aktiv 0;
BA_ "GenSigTimeoutMsg_Gateway_B8" SG_ 1088 WIV_Anzeige_aktiv 1088;
BA_ "GenSigAutoGenDsp" SG_ 1088 WIV_Oelmin_Warn 1;
BA_ "GenSigAutoGenSnd" SG_ 1088 WIV_Oelmin_Warn 1;
BA_ "GenSigEnvVarType" SG_ 1088 WIV_Oelmin_Warn 0;
BA_ "GenSigSendType" SG_ 1088 WIV_Oelmin_Warn 7;
BA_ "NWM-WakeupAllowed" SG_ 1088 WIV_Oelmin_Warn 0;
BA_ "NMH-WakeupAllowed" SG_ 1088 WIV_Oelmin_Warn 0;
BA_ "GenSigTimeoutMsg_Gateway_B8" SG_ 1088 WIV_Oelmin_Warn 1088;
BA_ "GenSigAutoGenDsp" SG_ 1088 WIV_Sensorfehler 1;
BA_ "GenSigAutoGenSnd" SG_ 1088 WIV_Sensorfehler 1;
BA_ "GenSigEnvVarType" SG_ 1088 WIV_Sensorfehler 0;
BA_ "GenSigSendType" SG_ 1088 WIV_Sensorfehler 7;
BA_ "NWM-WakeupAllowed" SG_ 1088 WIV_Sensorfehler 0;
BA_ "NMH-WakeupAllowed" SG_ 1088 WIV_Sensorfehler 0;
BA_ "GenSigTimeoutMsg_Gateway_B8" SG_ 1088 WIV_Sensorfehler 1088;
BA_ "GenSigAutoGenDsp" SG_ 1088 WIV_Schieflage 1;
BA_ "GenSigAutoGenSnd" SG_ 1088 WIV_Schieflage 1;
BA_ "GenSigEnvVarType" SG_ 1088 WIV_Schieflage 0;
BA_ "GenSigSendType" SG_ 1088 WIV_Schieflage 7;
BA_ "NWM-WakeupAllowed" SG_ 1088 WIV_Schieflage 0;
BA_ "NMH-WakeupAllowed" SG_ 1088 WIV_Schieflage 0;
BA_ "GenSigTimeoutMsg_Gateway_B8" SG_ 1088 WIV_Schieflage 1088;
BA_ "GenSigAutoGenDsp" SG_ 1088 WIV_Oelstand 1;
BA_ "GenSigAutoGenSnd" SG_ 1088 WIV_Oelstand 1;
BA_ "GenSigEnvVarType" SG_ 1088 WIV_Oelstand 1;
BA_ "GenSigSendType" SG_ 1088 WIV_Oelstand 7;
BA_ "NWM-WakeupAllowed" SG_ 1088 WIV_Oelstand 0;
BA_ "NMH-WakeupAllowed" SG_ 1088 WIV_Oelstand 0;
BA_ "GenSigTimeoutMsg_Gateway_B8" SG_ 1088 WIV_Oelstand 1088;
BA_ "GenSigAutoGenDsp" SG_ 1088 WIV_Oelsystem_aktiv 1;
BA_ "GenSigAutoGenSnd" SG_ 1088 WIV_Oelsystem_aktiv 1;
BA_ "GenSigEnvVarType" SG_ 1088 WIV_Oelsystem_aktiv 0;
BA_ "GenSigSendType" SG_ 1088 WIV_Oelsystem_aktiv 7;
BA_ "NWM-WakeupAllowed" SG_ 1088 WIV_Oelsystem_aktiv 0;
BA_ "NMH-WakeupAllowed" SG_ 1088 WIV_Oelsystem_aktiv 0;
BA_ "GenSigTimeoutMsg_Gateway_B8" SG_ 1088 WIV_Oelsystem_aktiv 1088;
BA_ "GenSigAutoGenDsp" SG_ 1088 WIV_nicht_betriebswarm 1;
BA_ "GenSigAutoGenSnd" SG_ 1088 WIV_nicht_betriebswarm 1;
BA_ "GenSigEnvVarType" SG_ 1088 WIV_nicht_betriebswarm 0;
BA_ "GenSigSendType" SG_ 1088 WIV_nicht_betriebswarm 7;
BA_ "NWM-WakeupAllowed" SG_ 1088 WIV_nicht_betriebswarm 0;
BA_ "NMH-WakeupAllowed" SG_ 1088 WIV_nicht_betriebswarm 0;
BA_ "GenSigTimeoutMsg_Gateway_B8" SG_ 1088 WIV_nicht_betriebswarm 1088;
BA_ "GenSigAutoGenDsp" SG_ 1088 WIV_Ueberfuell_Warn 1;
BA_ "GenSigAutoGenSnd" SG_ 1088 WIV_Ueberfuell_Warn 1;
BA_ "GenSigEnvVarType" SG_ 1088 WIV_Ueberfuell_Warn 0;
BA_ "GenSigSendType" SG_ 1088 WIV_Ueberfuell_Warn 7;
BA_ "NWM-WakeupAllowed" SG_ 1088 WIV_Ueberfuell_Warn 0;
BA_ "NMH-WakeupAllowed" SG_ 1088 WIV_Ueberfuell_Warn 0;
BA_ "GenSigTimeoutMsg_Gateway_B8" SG_ 1088 WIV_Ueberfuell_Warn 1088;
BA_ "GenSigAutoGenDsp" SG_ 1088 WIV_laufender_Motor 1;
BA_ "GenSigAutoGenSnd" SG_ 1088 WIV_laufender_Motor 1;
BA_ "GenSigSendType" SG_ 1088 WIV_laufender_Motor 7;
BA_ "NWM-WakeupAllowed" SG_ 1088 WIV_laufender_Motor 0;
BA_ "NMH-WakeupAllowed" SG_ 1088 WIV_laufender_Motor 0;
BA_ "GenSigTimeoutMsg_Gateway_B8" SG_ 1088 WIV_laufender_Motor 1088;
BA_ "GenSigAutoGenDsp" SG_ 1088 MO_Text_MSG_Werkstatt 1;
BA_ "GenSigAutoGenSnd" SG_ 1088 MO_Text_MSG_Werkstatt 1;
BA_ "GenSigEnvVarType" SG_ 1088 MO_Text_MSG_Werkstatt 0;
BA_ "GenSigSendType" SG_ 1088 MO_Text_MSG_Werkstatt 7;
BA_ "NWM-WakeupAllowed" SG_ 1088 MO_Text_MSG_Werkstatt 0;
BA_ "NMH-WakeupAllowed" SG_ 1088 MO_Text_MSG_Werkstatt 0;
BA_ "GenSigTimeoutMsg_Gateway_B8" SG_ 1088 MO_Text_MSG_Werkstatt 1088;
BA_ "GenSigAutoGenDsp" SG_ 1088 MO_Text_Partikelfil_Reg 1;
BA_ "GenSigAutoGenSnd" SG_ 1088 MO_Text_Partikelfil_Reg 1;
BA_ "GenSigEnvVarType" SG_ 1088 MO_Text_Partikelfil_Reg 0;
BA_ "GenSigSendType" SG_ 1088 MO_Text_Partikelfil_Reg 7;
BA_ "NWM-WakeupAllowed" SG_ 1088 MO_Text_Partikelfil_Reg 0;
BA_ "NMH-WakeupAllowed" SG_ 1088 MO_Text_Partikelfil_Reg 0;
BA_ "GenSigTimeoutMsg_Gateway_B8" SG_ 1088 MO_Text_Partikelfil_Reg 1088;
BA_ "GenSigAutoGenDsp" SG_ 1088 MO_Text_Fehler_Kraftstoffsys 1;
BA_ "GenSigAutoGenSnd" SG_ 1088 MO_Text_Fehler_Kraftstoffsys 1;
BA_ "GenSigEnvVarType" SG_ 1088 MO_Text_Fehler_Kraftstoffsys 0;
BA_ "GenSigSendType" SG_ 1088 MO_Text_Fehler_Kraftstoffsys 7;
BA_ "NWM-WakeupAllowed" SG_ 1088 MO_Text_Fehler_Kraftstoffsys 0;
BA_ "NMH-WakeupAllowed" SG_ 1088 MO_Text_Fehler_Kraftstoffsys 0;
BA_ "GenSigTimeoutMsg_Gateway_B8" SG_ 1088 MO_Text_Fehler_Kraftstoffsys 1088;
BA_ "GenSigAutoGenDsp" SG_ 1088 WIV_Oelmenge 1;
BA_ "GenSigAutoGenSnd" SG_ 1088 WIV_Oelmenge 1;
BA_ "GenSigEnvVarType" SG_ 1088 WIV_Oelmenge 1;
BA_ "GenSigSendType" SG_ 1088 WIV_Oelmenge 7;
BA_ "NWM-WakeupAllowed" SG_ 1088 WIV_Oelmenge 0;
BA_ "NMH-WakeupAllowed" SG_ 1088 WIV_Oelmenge 0;
BA_ "GenSigTimeoutMsg_Gateway_B8" SG_ 1088 WIV_Oelmenge 1088;
BA_ "GenSigAutoGenDsp" SG_ 1088 MO_Systemlampe 1;
BA_ "GenSigAutoGenSnd" SG_ 1088 MO_Systemlampe 1;
BA_ "GenSigEnvVarType" SG_ 1088 MO_Systemlampe 0;
BA_ "GenSigSendType" SG_ 1088 MO_Systemlampe 7;
BA_ "NWM-WakeupAllowed" SG_ 1088 MO_Systemlampe 0;
BA_ "NMH-WakeupAllowed" SG_ 1088 MO_Systemlampe 0;
BA_ "GenSigTimeoutMsg_Gateway_B8" SG_ 1088 MO_Systemlampe 1088;
BA_ "GenSigAutoGenDsp" SG_ 1088 MO_OBD2_Lampe 1;
BA_ "GenSigAutoGenSnd" SG_ 1088 MO_OBD2_Lampe 1;
BA_ "GenSigEnvVarType" SG_ 1088 MO_OBD2_Lampe 0;
BA_ "GenSigSendType" SG_ 1088 MO_OBD2_Lampe 7;
BA_ "NWM-WakeupAllowed" SG_ 1088 MO_OBD2_Lampe 0;
BA_ "NMH-WakeupAllowed" SG_ 1088 MO_OBD2_Lampe 0;
BA_ "GenSigTimeoutMsg_Gateway_B8" SG_ 1088 MO_OBD2_Lampe 1088;
BA_ "GenSigAutoGenDsp" SG_ 1088 MO_Heissleuchte 1;
BA_ "GenSigAutoGenSnd" SG_ 1088 MO_Heissleuchte 1;
BA_ "GenSigEnvVarType" SG_ 1088 MO_Heissleuchte 0;
BA_ "GenSigSendType" SG_ 1088 MO_Heissleuchte 7;
BA_ "NWM-WakeupAllowed" SG_ 1088 MO_Heissleuchte 0;
BA_ "NMH-WakeupAllowed" SG_ 1088 MO_Heissleuchte 0;
BA_ "GenSigTimeoutMsg_Gateway_B8" SG_ 1088 MO_Heissleuchte 1088;
BA_ "GenSigAutoGenDsp" SG_ 1088 MO_Partikel_Lampe 1;
BA_ "GenSigAutoGenSnd" SG_ 1088 MO_Partikel_Lampe 1;
BA_ "GenSigEnvVarType" SG_ 1088 MO_Partikel_Lampe 0;
BA_ "GenSigSendType" SG_ 1088 MO_Partikel_Lampe 7;
BA_ "NWM-WakeupAllowed" SG_ 1088 MO_Partikel_Lampe 0;
BA_ "NMH-WakeupAllowed" SG_ 1088 MO_Partikel_Lampe 0;
BA_ "GenSigTimeoutMsg_Gateway_B8" SG_ 1088 MO_Partikel_Lampe 1088;
BA_ "GenSigAutoGenDsp" SG_ 1088 MO_Winterfahrprog 1;
BA_ "GenSigAutoGenSnd" SG_ 1088 MO_Winterfahrprog 1;
BA_ "GenSigEnvVarType" SG_ 1088 MO_Winterfahrprog 0;
BA_ "GenSigSendType" SG_ 1088 MO_Winterfahrprog 7;
BA_ "NWM-WakeupAllowed" SG_ 1088 MO_Winterfahrprog 0;
BA_ "NMH-WakeupAllowed" SG_ 1088 MO_Winterfahrprog 0;
BA_ "GenSigTimeoutMsg_Gateway_B8" SG_ 1088 MO_Winterfahrprog 1088;
BA_ "GenSigAutoGenDsp" SG_ 1088 WIV_Oelstand_nicht_vorhanden 1;
BA_ "GenSigAutoGenSnd" SG_ 1088 WIV_Oelstand_nicht_vorhanden 1;
BA_ "GenSigSendType" SG_ 1088 WIV_Oelstand_nicht_vorhanden 7;
BA_ "NWM-WakeupAllowed" SG_ 1088 WIV_Oelstand_nicht_vorhanden 0;
BA_ "NMH-WakeupAllowed" SG_ 1088 WIV_Oelstand_nicht_vorhanden 0;
BA_ "GenSigTimeoutMsg_Gateway_B8" SG_ 1088 WIV_Oelstand_nicht_vorhanden 1088;
BA_ "GenSigAutoGenDsp" SG_ 1088 WIV_nachfuellanzeige_ein 1;
BA_ "GenSigAutoGenSnd" SG_ 1088 WIV_nachfuellanzeige_ein 1;
BA_ "GenSigSendType" SG_ 1088 WIV_nachfuellanzeige_ein 7;
BA_ "NWM-WakeupAllowed" SG_ 1088 WIV_nachfuellanzeige_ein 0;
BA_ "NMH-WakeupAllowed" SG_ 1088 WIV_nachfuellanzeige_ein 0;
BA_ "GenSigTimeoutMsg_Gateway_B8" SG_ 1088 WIV_nachfuellanzeige_ein 1088;
BA_ "GenSigAutoGenDsp" SG_ 1088 WIV_Check_Oil 1;
BA_ "GenSigAutoGenSnd" SG_ 1088 WIV_Check_Oil 1;
BA_ "GenSigSendType" SG_ 1088 WIV_Check_Oil 7;
BA_ "NWM-WakeupAllowed" SG_ 1088 WIV_Check_Oil 0;
BA_ "NMH-WakeupAllowed" SG_ 1088 WIV_Check_Oil 0;
BA_ "GenSigTimeoutMsg_Gateway_B8" SG_ 1088 WIV_Check_Oil 1088;
BA_ "GenSigAutoGenDsp" SG_ 1088 WIV_Unterfuell_Warn 1;
BA_ "GenSigAutoGenSnd" SG_ 1088 WIV_Unterfuell_Warn 1;
BA_ "GenSigEnvVarType" SG_ 1088 WIV_Unterfuell_Warn 0;
BA_ "GenSigSendType" SG_ 1088 WIV_Unterfuell_Warn 7;
BA_ "NWM-WakeupAllowed" SG_ 1088 WIV_Unterfuell_Warn 0;
BA_ "NMH-WakeupAllowed" SG_ 1088 WIV_Unterfuell_Warn 0;
BA_ "GenSigTimeoutMsg_Gateway_B8" SG_ 1088 WIV_Unterfuell_Warn 1088;
BA_ "GenSigAutoGenDsp" SG_ 1088 MO_Tankdeckel_Lampe 1;
BA_ "GenSigAutoGenSnd" SG_ 1088 MO_Tankdeckel_Lampe 1;
BA_ "GenSigEnvVarType" SG_ 1088 MO_Tankdeckel_Lampe 0;
BA_ "GenSigSendType" SG_ 1088 MO_Tankdeckel_Lampe 7;
BA_ "NWM-WakeupAllowed" SG_ 1088 MO_Tankdeckel_Lampe 0;
BA_ "NMH-WakeupAllowed" SG_ 1088 MO_Tankdeckel_Lampe 0;
BA_ "GenSigTimeoutMsg_Gateway_B8" SG_ 1088 MO_Tankdeckel_Lampe 1088;
BA_ "GenSigAutoGenDsp" SG_ 1088 MO_Text_Tankdeckelwarn 1;
BA_ "GenSigAutoGenSnd" SG_ 1088 MO_Text_Tankdeckelwarn 1;
BA_ "GenSigSendType" SG_ 1088 MO_Text_Tankdeckelwarn 7;
BA_ "NWM-WakeupAllowed" SG_ 1088 MO_Text_Tankdeckelwarn 0;
BA_ "NMH-WakeupAllowed" SG_ 1088 MO_Text_Tankdeckelwarn 0;
BA_ "GenSigTimeoutMsg_Gateway_B8" SG_ 1088 MO_Text_Tankdeckelwarn 1088;
BA_ "GenSigAutoGenDsp" SG_ 1088 WIV_Enable_Oeldr_Motor 1;
BA_ "GenSigAutoGenSnd" SG_ 1088 WIV_Enable_Oeldr_Motor 1;
BA_ "GenSigSendType" SG_ 1088 WIV_Enable_Oeldr_Motor 7;
BA_ "NWM-WakeupAllowed" SG_ 1088 WIV_Enable_Oeldr_Motor 0;
BA_ "NMH-WakeupAllowed" SG_ 1088 WIV_Enable_Oeldr_Motor 0;
BA_ "GenSigTimeoutMsg_Gateway_B8" SG_ 1088 WIV_Enable_Oeldr_Motor 1088;
BA_ "GenSigAutoGenDsp" SG_ 1088 WIV_Oeldr_Warn_Motor 1;
BA_ "GenSigAutoGenSnd" SG_ 1088 WIV_Oeldr_Warn_Motor 1;
BA_ "GenSigSendType" SG_ 1088 WIV_Oeldr_Warn_Motor 7;
BA_ "NWM-WakeupAllowed" SG_ 1088 WIV_Oeldr_Warn_Motor 0;
BA_ "NMH-WakeupAllowed" SG_ 1088 WIV_Oeldr_Warn_Motor 0;
BA_ "GenSigTimeoutMsg_Gateway_B8" SG_ 1088 WIV_Oeldr_Warn_Motor 1088;
BA_ "GenSigAutoGenDsp" SG_ 1088 MO_Avus_Motorschutz 1;
BA_ "GenSigAutoGenSnd" SG_ 1088 MO_Avus_Motorschutz 1;
BA_ "GenSigSendType" SG_ 1088 MO_Avus_Motorschutz 7;
BA_ "NWM-WakeupAllowed" SG_ 1088 MO_Avus_Motorschutz 0;
BA_ "NMH-WakeupAllowed" SG_ 1088 MO_Avus_Motorschutz 0;
BA_ "GenSigTimeoutMsg_Gateway_B8" SG_ 1088 MO_Avus_Motorschutz 1088;
BA_ "GenSigAutoGenDsp" SG_ 1600 MO_QBit_Ansaugluft_Temp 1;
BA_ "GenSigAutoGenSnd" SG_ 1600 MO_QBit_Ansaugluft_Temp 1;
BA_ "GenSigEnvVarType" SG_ 1600 MO_QBit_Ansaugluft_Temp 0;
BA_ "GenSigSendType" SG_ 1600 MO_QBit_Ansaugluft_Temp 7;
BA_ "GenSigStartValue" SG_ 1600 MO_QBit_Ansaugluft_Temp 1;
BA_ "NWM-WakeupAllowed" SG_ 1600 MO_QBit_Ansaugluft_Temp 0;
BA_ "NMH-WakeupAllowed" SG_ 1600 MO_QBit_Ansaugluft_Temp 0;
BA_ "GenSigTimeoutMsg_Gateway_B8" SG_ 1600 MO_QBit_Ansaugluft_Temp 1600;
BA_ "GenSigTimeoutMsg_Getriebe_AL6000" SG_ 1600 MO_QBit_Ansaugluft_Temp 1600;
BA_ "GenSigTimeoutMsg_Getriebe_DL5001" SG_ 1600 MO_QBit_Ansaugluft_Temp 1600;
BA_ "GenSigTimeoutMsg_Getriebe_VL3002" SG_ 1600 MO_QBit_Ansaugluft_Temp 1600;
BA_ "GenSigAutoGenDsp" SG_ 1600 MO_QBit_Oel_Temp 1;
BA_ "GenSigAutoGenSnd" SG_ 1600 MO_QBit_Oel_Temp 1;
BA_ "GenSigEnvVarType" SG_ 1600 MO_QBit_Oel_Temp 0;
BA_ "GenSigSendType" SG_ 1600 MO_QBit_Oel_Temp 7;
BA_ "GenSigStartValue" SG_ 1600 MO_QBit_Oel_Temp 1;
BA_ "NWM-WakeupAllowed" SG_ 1600 MO_QBit_Oel_Temp 0;
BA_ "NMH-WakeupAllowed" SG_ 1600 MO_QBit_Oel_Temp 0;
BA_ "GenSigTimeoutMsg_Gateway_B8" SG_ 1600 MO_QBit_Oel_Temp 1600;
BA_ "GenSigAutoGenDsp" SG_ 1600 MO_QBit_Kuehlmittel_Temp 1;
BA_ "GenSigAutoGenSnd" SG_ 1600 MO_QBit_Kuehlmittel_Temp 1;
BA_ "GenSigEnvVarType" SG_ 1600 MO_QBit_Kuehlmittel_Temp 0;
BA_ "GenSigSendType" SG_ 1600 MO_QBit_Kuehlmittel_Temp 7;
BA_ "GenSigStartValue" SG_ 1600 MO_QBit_Kuehlmittel_Temp 1;
BA_ "NWM-WakeupAllowed" SG_ 1600 MO_QBit_Kuehlmittel_Temp 0;
BA_ "NMH-WakeupAllowed" SG_ 1600 MO_QBit_Kuehlmittel_Temp 0;
BA_ "GenSigTimeoutMsg_Gateway_B8" SG_ 1600 MO_QBit_Kuehlmittel_Temp 1600;
BA_ "GenSigTimeoutMsg_Getriebe_AL6000" SG_ 1600 MO_QBit_Kuehlmittel_Temp 1600;
BA_ "GenSigTimeoutMsg_Getriebe_DL5001" SG_ 1600 MO_QBit_Kuehlmittel_Temp 1600;
BA_ "GenSigTimeoutMsg_Getriebe_VL3002" SG_ 1600 MO_QBit_Kuehlmittel_Temp 1600;
BA_ "GenSigAutoGenDsp" SG_ 1600 MO_Ansaugluft_Temp 1;
BA_ "GenSigAutoGenSnd" SG_ 1600 MO_Ansaugluft_Temp 1;
BA_ "GenSigEnvVarType" SG_ 1600 MO_Ansaugluft_Temp 1;
BA_ "GenSigSendType" SG_ 1600 MO_Ansaugluft_Temp 7;
BA_ "GenSigStartValue" SG_ 1600 MO_Ansaugluft_Temp 254;
BA_ "NWM-WakeupAllowed" SG_ 1600 MO_Ansaugluft_Temp 0;
BA_ "NMH-WakeupAllowed" SG_ 1600 MO_Ansaugluft_Temp 0;
BA_ "GenSigTimeoutMsg_Gateway_B8" SG_ 1600 MO_Ansaugluft_Temp 1600;
BA_ "GenSigTimeoutMsg_Getriebe_AL6000" SG_ 1600 MO_Ansaugluft_Temp 1600;
BA_ "GenSigTimeoutMsg_Getriebe_DL5001" SG_ 1600 MO_Ansaugluft_Temp 1600;
BA_ "GenSigTimeoutMsg_Getriebe_VL3002" SG_ 1600 MO_Ansaugluft_Temp 1600;
BA_ "GenSigAutoGenDsp" SG_ 1600 MO_Oel_Temp 1;
BA_ "GenSigAutoGenSnd" SG_ 1600 MO_Oel_Temp 1;
BA_ "GenSigEnvVarType" SG_ 1600 MO_Oel_Temp 1;
BA_ "GenSigSendType" SG_ 1600 MO_Oel_Temp 7;
BA_ "GenSigStartValue" SG_ 1600 MO_Oel_Temp 254;
BA_ "NWM-WakeupAllowed" SG_ 1600 MO_Oel_Temp 0;
BA_ "NMH-WakeupAllowed" SG_ 1600 MO_Oel_Temp 0;
BA_ "GenSigTimeoutMsg_Gateway_B8" SG_ 1600 MO_Oel_Temp 1600;
BA_ "GenSigAutoGenDsp" SG_ 1600 MO_Kuehlmittel_Temp 1;
BA_ "GenSigAutoGenSnd" SG_ 1600 MO_Kuehlmittel_Temp 1;
BA_ "GenSigEnvVarType" SG_ 1600 MO_Kuehlmittel_Temp 1;
BA_ "GenSigSendType" SG_ 1600 MO_Kuehlmittel_Temp 7;
BA_ "GenSigStartValue" SG_ 1600 MO_Kuehlmittel_Temp 254;
BA_ "NWM-WakeupAllowed" SG_ 1600 MO_Kuehlmittel_Temp 0;
BA_ "NMH-WakeupAllowed" SG_ 1600 MO_Kuehlmittel_Temp 0;
BA_ "GenSigTimeoutMsg_Gateway_B8" SG_ 1600 MO_Kuehlmittel_Temp 1600;
BA_ "GenSigTimeoutMsg_Getriebe_AL6000" SG_ 1600 MO_Kuehlmittel_Temp 1600;
BA_ "GenSigTimeoutMsg_Getriebe_DL5001" SG_ 1600 MO_Kuehlmittel_Temp 1600;
BA_ "GenSigTimeoutMsg_Getriebe_VL3002" SG_ 1600 MO_Kuehlmittel_Temp 1600;
BA_ "GenSigAutoGenDsp" SG_ 1600 MO_Hoeheninfo 1;
BA_ "GenSigAutoGenSnd" SG_ 1600 MO_Hoeheninfo 1;
BA_ "GenSigEnvVarType" SG_ 1600 MO_Hoeheninfo 1;
BA_ "GenSigSendType" SG_ 1600 MO_Hoeheninfo 7;
BA_ "NWM-WakeupAllowed" SG_ 1600 MO_Hoeheninfo 0;
BA_ "NMH-WakeupAllowed" SG_ 1600 MO_Hoeheninfo 0;
BA_ "GenSigTimeoutMsg_Gateway_B8" SG_ 1600 MO_Hoeheninfo 1600;
BA_ "GenSigTimeoutMsg_Getriebe_AL6000" SG_ 1600 MO_Hoeheninfo 1600;
BA_ "GenSigTimeoutMsg_Getriebe_DL5001" SG_ 1600 MO_Hoeheninfo 1600;
BA_ "GenSigTimeoutMsg_Getriebe_VL3002" SG_ 1600 MO_Hoeheninfo 1600;
BA_ "GenSigAutoGenDsp" SG_ 1600 MO_Kennfeldk 1;
BA_ "GenSigAutoGenSnd" SG_ 1600 MO_Kennfeldk 1;
BA_ "GenSigEnvVarType" SG_ 1600 MO_Kennfeldk 0;
BA_ "GenSigSendType" SG_ 1600 MO_Kennfeldk 7;
BA_ "NWM-WakeupAllowed" SG_ 1600 MO_Kennfeldk 0;
BA_ "NMH-WakeupAllowed" SG_ 1600 MO_Kennfeldk 0;
BA_ "GenSigTimeoutMsg_Gateway_B8" SG_ 1600 MO_Kennfeldk 1600;
BA_ "GenSigAutoGenDsp" SG_ 1600 MO_Versionsinfo 1;
BA_ "GenSigAutoGenSnd" SG_ 1600 MO_Versionsinfo 1;
BA_ "GenSigSendType" SG_ 1600 MO_Versionsinfo 7;
BA_ "NWM-WakeupAllowed" SG_ 1600 MO_Versionsinfo 0;
BA_ "NMH-WakeupAllowed" SG_ 1600 MO_Versionsinfo 0;
BA_ "GenSigTimeoutMsg_Gateway_B8" SG_ 1600 MO_Versionsinfo 1600;
BA_ "GenSigAutoGenDsp" SG_ 1600 MO_Mom_Traegheit_02 1;
BA_ "GenSigAutoGenSnd" SG_ 1600 MO_Mom_Traegheit_02 1;
BA_ "GenSigEnvVarType" SG_ 1600 MO_Mom_Traegheit_02 1;
BA_ "GenSigSendType" SG_ 1600 MO_Mom_Traegheit_02 7;
BA_ "NWM-WakeupAllowed" SG_ 1600 MO_Mom_Traegheit_02 0;
BA_ "NMH-WakeupAllowed" SG_ 1600 MO_Mom_Traegheit_02 0;
BA_ "GenSigTimeoutMsg_Gateway_B8" SG_ 1600 MO_Mom_Traegheit_02 1600;
BA_ "GenSigTimeoutMsg_Getriebe_AL6000" SG_ 1600 MO_Mom_Traegheit_02 1600;
BA_ "GenSigTimeoutMsg_Getriebe_DL5001" SG_ 1600 MO_Mom_Traegheit_02 1600;
BA_ "GenSigTimeoutMsg_Getriebe_VL3002" SG_ 1600 MO_Mom_Traegheit_02 1600;
BA_ "GenSigAutoGenDsp" SG_ 135 Motor_08_CHK 1;
BA_ "GenSigAutoGenSnd" SG_ 135 Motor_08_CHK 1;
BA_ "GenSigEnvVarType" SG_ 135 Motor_08_CHK 0;
BA_ "GenSigSendType" SG_ 135 Motor_08_CHK 7;
BA_ "NWM-WakeupAllowed" SG_ 135 Motor_08_CHK 0;
BA_ "NMH-WakeupAllowed" SG_ 135 Motor_08_CHK 0;
BA_ "GenSigTimeoutMsg_Getriebe_AL6000" SG_ 135 Motor_08_CHK 135;
BA_ "GenSigTimeoutMsg_Getriebe_DL5001" SG_ 135 Motor_08_CHK 135;
BA_ "GenSigTimeoutMsg_Getriebe_VL3002" SG_ 135 Motor_08_CHK 135;
BA_ "GenSigAutoGenDsp" SG_ 135 Motor_08_BZ 1;
BA_ "GenSigAutoGenSnd" SG_ 135 Motor_08_BZ 1;
BA_ "GenSigEnvVarType" SG_ 135 Motor_08_BZ 0;
BA_ "GenSigSendType" SG_ 135 Motor_08_BZ 7;
BA_ "NWM-WakeupAllowed" SG_ 135 Motor_08_BZ 0;
BA_ "NMH-WakeupAllowed" SG_ 135 Motor_08_BZ 0;
BA_ "GenSigTimeoutMsg_Getriebe_AL6000" SG_ 135 Motor_08_BZ 135;
BA_ "GenSigTimeoutMsg_Getriebe_DL5001" SG_ 135 Motor_08_BZ 135;
BA_ "GenSigTimeoutMsg_Getriebe_VL3002" SG_ 135 Motor_08_BZ 135;
BA_ "GenSigAutoGenDsp" SG_ 135 MO_QBit_Drehzahl_02 1;
BA_ "GenSigAutoGenSnd" SG_ 135 MO_QBit_Drehzahl_02 1;
BA_ "GenSigSendType" SG_ 135 MO_QBit_Drehzahl_02 7;
BA_ "GenSigStartValue" SG_ 135 MO_QBit_Drehzahl_02 1;
BA_ "NWM-WakeupAllowed" SG_ 135 MO_QBit_Drehzahl_02 0;
BA_ "NMH-WakeupAllowed" SG_ 135 MO_QBit_Drehzahl_02 0;
BA_ "GenSigTimeoutMsg_Getriebe_AL6000" SG_ 135 MO_QBit_Drehzahl_02 135;
BA_ "GenSigTimeoutMsg_Getriebe_DL5001" SG_ 135 MO_QBit_Drehzahl_02 135;
BA_ "GenSigTimeoutMsg_Getriebe_VL3002" SG_ 135 MO_QBit_Drehzahl_02 135;
BA_ "GenSigAutoGenDsp" SG_ 135 MO_QBit_Fahrpedalwerte_02 1;
BA_ "GenSigAutoGenSnd" SG_ 135 MO_QBit_Fahrpedalwerte_02 1;
BA_ "GenSigEnvVarType" SG_ 135 MO_QBit_Fahrpedalwerte_02 0;
BA_ "GenSigSendType" SG_ 135 MO_QBit_Fahrpedalwerte_02 7;
BA_ "GenSigStartValue" SG_ 135 MO_QBit_Fahrpedalwerte_02 1;
BA_ "NWM-WakeupAllowed" SG_ 135 MO_QBit_Fahrpedalwerte_02 0;
BA_ "NMH-WakeupAllowed" SG_ 135 MO_QBit_Fahrpedalwerte_02 0;
BA_ "GenSigTimeoutMsg_Getriebe_AL6000" SG_ 135 MO_QBit_Fahrpedalwerte_02 135;
BA_ "GenSigTimeoutMsg_Getriebe_DL5001" SG_ 135 MO_QBit_Fahrpedalwerte_02 135;
BA_ "GenSigTimeoutMsg_Getriebe_VL3002" SG_ 135 MO_QBit_Fahrpedalwerte_02 135;
BA_ "GenSigAutoGenDsp" SG_ 135 MO_Status_Zylabschalt 1;
BA_ "GenSigAutoGenSnd" SG_ 135 MO_Status_Zylabschalt 1;
BA_ "GenSigSendType" SG_ 135 MO_Status_Zylabschalt 7;
BA_ "NWM-WakeupAllowed" SG_ 135 MO_Status_Zylabschalt 0;
BA_ "NMH-WakeupAllowed" SG_ 135 MO_Status_Zylabschalt 0;
BA_ "GenSigTimeoutMsg_Getriebe_AL6000" SG_ 135 MO_Status_Zylabschalt 135;
BA_ "GenSigTimeoutMsg_Getriebe_DL5001" SG_ 135 MO_Status_Zylabschalt 135;
BA_ "GenSigTimeoutMsg_Getriebe_VL3002" SG_ 135 MO_Status_Zylabschalt 135;
BA_ "GenSigAutoGenDsp" SG_ 135 MO_Drehzahl_02 1;
BA_ "GenSigAutoGenSnd" SG_ 135 MO_Drehzahl_02 1;
BA_ "GenSigEnvVarType" SG_ 135 MO_Drehzahl_02 1;
BA_ "GenSigSendType" SG_ 135 MO_Drehzahl_02 7;
BA_ "NWM-WakeupAllowed" SG_ 135 MO_Drehzahl_02 0;
BA_ "NMH-WakeupAllowed" SG_ 135 MO_Drehzahl_02 0;
BA_ "GenSigTimeoutMsg_Getriebe_AL6000" SG_ 135 MO_Drehzahl_02 135;
BA_ "GenSigTimeoutMsg_Getriebe_DL5001" SG_ 135 MO_Drehzahl_02 135;
BA_ "GenSigTimeoutMsg_Getriebe_VL3002" SG_ 135 MO_Drehzahl_02 135;
BA_ "GenSigAutoGenDsp" SG_ 135 MO_Fahrpedalrohwert_02 1;
BA_ "GenSigAutoGenSnd" SG_ 135 MO_Fahrpedalrohwert_02 1;
BA_ "GenSigEnvVarType" SG_ 135 MO_Fahrpedalrohwert_02 1;
BA_ "GenSigSendType" SG_ 135 MO_Fahrpedalrohwert_02 7;
BA_ "NWM-WakeupAllowed" SG_ 135 MO_Fahrpedalrohwert_02 0;
BA_ "NMH-WakeupAllowed" SG_ 135 MO_Fahrpedalrohwert_02 0;
BA_ "GenSigTimeoutMsg_Getriebe_AL6000" SG_ 135 MO_Fahrpedalrohwert_02 135;
BA_ "GenSigTimeoutMsg_Getriebe_DL5001" SG_ 135 MO_Fahrpedalrohwert_02 135;
BA_ "GenSigTimeoutMsg_Getriebe_VL3002" SG_ 135 MO_Fahrpedalrohwert_02 135;
BA_ "Fehlerwert" SG_ 1607 MO_ITM_Kuehlmittel_Temp 2;
BA_ "GenSigSwitchedByIgnition" SG_ 1607 MO_ITM_Kuehlmittel_Temp 0;
BA_ "GenSigFuncType" SG_ 1607 MO_ITM_Kuehlmittel_Temp 0;
BA_ "NWM-WakeupAllowed" SG_ 1607 MO_ITM_Kuehlmittel_Temp 0;
BA_ "GenSigStartValue" SG_ 1607 MO_ITM_Kuehlmittel_Temp 1;
BA_ "GenSigAutoGenSnd" SG_ 1607 MO_ITM_Kuehlmittel_Temp 0;
BA_ "GenSigAutoGenDsp" SG_ 1607 MO_ITM_Kuehlmittel_Temp 0;
BA_ "Fehlerwert" SG_ 1607 MO_E85_Sensor 15;
BA_ "GenSigSwitchedByIgnition" SG_ 1607 MO_E85_Sensor 0;
BA_ "GenSigFuncType" SG_ 1607 MO_E85_Sensor 0;
BA_ "NWM-WakeupAllowed" SG_ 1607 MO_E85_Sensor 0;
BA_ "GenSigStartValue" SG_ 1607 MO_E85_Sensor 14;
BA_ "GenSigAutoGenSnd" SG_ 1607 MO_E85_Sensor 0;
BA_ "GenSigAutoGenDsp" SG_ 1607 MO_E85_Sensor 0;
BA_ "GenSigSwitchedByIgnition" SG_ 1607 SCR_Anz_Motorstarts 0;
BA_ "GenSigFuncType" SG_ 1607 SCR_Anz_Motorstarts 0;
BA_ "NWM-WakeupAllowed" SG_ 1607 SCR_Anz_Motorstarts 0;
BA_ "GenSigStartValue" SG_ 1607 SCR_Anz_Motorstarts 15;
BA_ "GenSigAutoGenSnd" SG_ 1607 SCR_Anz_Motorstarts 1;
BA_ "GenSigAutoGenDsp" SG_ 1607 SCR_Anz_Motorstarts 1;
BA_ "GenSigSwitchedByIgnition" SG_ 1607 SCR_Reichweite 0;
BA_ "GenSigFuncType" SG_ 1607 SCR_Reichweite 0;
BA_ "NWM-WakeupAllowed" SG_ 1607 SCR_Reichweite 0;
BA_ "GenSigStartValue" SG_ 1607 SCR_Reichweite 32767;
BA_ "GenSigAutoGenSnd" SG_ 1607 SCR_Reichweite 1;
BA_ "GenSigAutoGenDsp" SG_ 1607 SCR_Reichweite 1;
BA_ "GenSigSwitchedByIgnition" SG_ 1607 SCR_Warnstufe_1 0;
BA_ "GenSigFuncType" SG_ 1607 SCR_Warnstufe_1 0;
BA_ "NWM-WakeupAllowed" SG_ 1607 SCR_Warnstufe_1 0;
BA_ "GenSigAutoGenSnd" SG_ 1607 SCR_Warnstufe_1 1;
BA_ "GenSigAutoGenDsp" SG_ 1607 SCR_Warnstufe_1 1;
BA_ "GenSigSwitchedByIgnition" SG_ 1607 SCR_Warnstufe_2 0;
BA_ "GenSigFuncType" SG_ 1607 SCR_Warnstufe_2 0;
BA_ "NWM-WakeupAllowed" SG_ 1607 SCR_Warnstufe_2 0;
BA_ "GenSigAutoGenSnd" SG_ 1607 SCR_Warnstufe_2 1;
BA_ "GenSigAutoGenDsp" SG_ 1607 SCR_Warnstufe_2 1;
BA_ "GenSigSwitchedByIgnition" SG_ 1607 SCR_Text 0;
BA_ "GenSigFuncType" SG_ 1607 SCR_Text 0;
BA_ "NWM-WakeupAllowed" SG_ 1607 SCR_Text 0;
BA_ "GenSigAutoGenSnd" SG_ 1607 SCR_Text 1;
BA_ "GenSigAutoGenDsp" SG_ 1607 SCR_Text 1;
BA_ "GenSigSwitchedByIgnition" SG_ 1607 SCR_Akustik 0;
BA_ "GenSigFuncType" SG_ 1607 SCR_Akustik 0;
BA_ "NWM-WakeupAllowed" SG_ 1607 SCR_Akustik 0;
BA_ "GenSigAutoGenSnd" SG_ 1607 SCR_Akustik 1;
BA_ "GenSigAutoGenDsp" SG_ 1607 SCR_Akustik 1;
BA_ "GenSigSwitchedByIgnition" SG_ 1607 MO_Kraftstofffilter_Wasser 0;
BA_ "GenSigFuncType" SG_ 1607 MO_Kraftstofffilter_Wasser 0;
BA_ "NWM-WakeupAllowed" SG_ 1607 MO_Kraftstofffilter_Wasser 0;
BA_ "GenSigAutoGenSnd" SG_ 1607 MO_Kraftstofffilter_Wasser 1;
BA_ "GenSigAutoGenDsp" SG_ 1607 MO_Kraftstofffilter_Wasser 1;
BA_ "GenSigSwitchedByIgnition" SG_ 1607 SCR_Systemfehler 0;
BA_ "GenSigFuncType" SG_ 1607 SCR_Systemfehler 0;
BA_ "NWM-WakeupAllowed" SG_ 1607 SCR_Systemfehler 0;
BA_ "GenSigAutoGenSnd" SG_ 1607 SCR_Systemfehler 1;
BA_ "GenSigAutoGenDsp" SG_ 1607 SCR_Systemfehler 1;
BA_ "GenSigSwitchedByIgnition" SG_ 1607 SCR_Inducement_Strategie 0;
BA_ "GenSigFuncType" SG_ 1607 SCR_Inducement_Strategie 0;
BA_ "NWM-WakeupAllowed" SG_ 1607 SCR_Inducement_Strategie 0;
BA_ "GenSigAutoGenSnd" SG_ 1607 SCR_Inducement_Strategie 1;
BA_ "GenSigAutoGenDsp" SG_ 1607 SCR_Inducement_Strategie 1;
BA_ "Fehlerwert" SG_ 1607 MO_CO2_Faktor 4095;
BA_ "GenSigSwitchedByIgnition" SG_ 1607 MO_CO2_Faktor 0;
BA_ "GenSigFuncType" SG_ 1607 MO_CO2_Faktor 0;
BA_ "NWM-WakeupAllowed" SG_ 1607 MO_CO2_Faktor 0;
BA_ "GenSigAutoGenSnd" SG_ 1607 MO_CO2_Faktor 1;
BA_ "GenSigAutoGenDsp" SG_ 1607 MO_CO2_Faktor 1;
BA_ "GenSigSwitchedByIgnition" SG_ 1607 MO_MKB_MUX 0;
BA_ "GenSigFuncType" SG_ 1607 MO_MKB_MUX 0;
BA_ "NWM-WakeupAllowed" SG_ 1607 MO_MKB_MUX 0;
BA_ "GenSigAutoGenSnd" SG_ 1607 MO_MKB_MUX 1;
BA_ "GenSigAutoGenDsp" SG_ 1607 MO_MKB_MUX 1;
BA_ "GenSigSwitchedByIgnition" SG_ 1607 MO_MKB_01 0;
BA_ "GenSigFuncType" SG_ 1607 MO_MKB_01 0;
BA_ "NWM-WakeupAllowed" SG_ 1607 MO_MKB_01 0;
BA_ "GenSigSendType" SG_ 1607 MO_MKB_01 7;
BA_ "GenSigAutoGenSnd" SG_ 1607 MO_MKB_01 1;
BA_ "GenSigAutoGenDsp" SG_ 1607 MO_MKB_01 1;
BA_ "GenSigSwitchedByIgnition" SG_ 1607 MO_MKB_02 0;
BA_ "GenSigFuncType" SG_ 1607 MO_MKB_02 0;
BA_ "NWM-WakeupAllowed" SG_ 1607 MO_MKB_02 0;
BA_ "GenSigSendType" SG_ 1607 MO_MKB_02 7;
BA_ "GenSigAutoGenSnd" SG_ 1607 MO_MKB_02 1;
BA_ "GenSigAutoGenDsp" SG_ 1607 MO_MKB_02 1;
BA_ "GenSigSwitchedByIgnition" SG_ 1607 MO_MKB_03 0;
BA_ "GenSigFuncType" SG_ 1607 MO_MKB_03 0;
BA_ "NWM-WakeupAllowed" SG_ 1607 MO_MKB_03 0;
BA_ "GenSigSendType" SG_ 1607 MO_MKB_03 7;
BA_ "GenSigAutoGenSnd" SG_ 1607 MO_MKB_03 1;
BA_ "GenSigAutoGenDsp" SG_ 1607 MO_MKB_03 1;
BA_ "GenSigSwitchedByIgnition" SG_ 1607 MO_MKB_04 0;
BA_ "GenSigFuncType" SG_ 1607 MO_MKB_04 0;
BA_ "NWM-WakeupAllowed" SG_ 1607 MO_MKB_04 0;
BA_ "GenSigSendType" SG_ 1607 MO_MKB_04 7;
BA_ "GenSigAutoGenSnd" SG_ 1607 MO_MKB_04 1;
BA_ "GenSigAutoGenDsp" SG_ 1607 MO_MKB_04 1;
VAL_ 779 KBI_ABS_Lampe 1 "ABS Lampe ein" 0 "ABS Lampe aus" ;
VAL_ 779 KBI_ESP_Lampe 1 "ESP Lampe ein" 0 "ESP Lampe aus" ;
VAL_ 779 KBI_BKL_Lampe 0 "BKL aus" 1 "BKL ein" ;
VAL_ 779 KBI_Airbag_Lampe 0 "Airbag Lampe aus" 1 "Airbag Lampe ein" ;
VAL_ 779 KBI_SILA_gueltig 1 "gueltig" 0 "ungueltig" ;
VAL_ 779 KBI_Vorglueh_System_Lampe 0 "Lampe aus" 1 "Lampe ein" ;
VAL_ 779 KBI_Tankwarnung 1 "Lampe ein" 0 "Lampe aus" ;
VAL_ 779 KBI_MFA_v_Einheit_01 0 "kmh" 1 "mph" ;
VAL_ 779 KBI_im_Stellgliedtest 0 "kein Stellgliedtest" 1 "Kombi im Stellgliedtest" ;
VAL_ 779 KBI_Anzeigefehler_LDW 1 "Anzeige iO" 2 "Anzeigefehler" 0 "nicht vorhanden bzw. unterstützt" 3 "nicht definiert" ;
VAL_ 779 KBI_Variante_USA 0 "keine USA-Variante" 1 "USA-Variante" ;
VAL_ 779 KBI_Oeldruckwarnung 1 "aktiv" 0 "inaktiv" ;
VAL_ 779 KBI_Einheit_Tacho 0 "km/h" 1 "mph" ;
VAL_ 779 KBI_Konsistenz_ACC 1 "ACC Botschaft inkonsistent    " 0 "ACC Botschaft konsistent" ;
VAL_ 779 KBI_Fehler_Anzeige_ACC 1 "Anzeigefehler ACC" 0 " iO" ;
VAL_ 779 KBI_Anzeigefehler_SWA 0 "nicht vorhanden bzw. unterstützt" 1 "Anzeige iO" 2 "Anzeigefehler" 3 "nicht definiert" ;
VAL_ 779 KBI_KD_Fehler 1 "eingetragen" 0 "nicht eingetragen" ;
VAL_ 1719 KBI_Kilometerstand 1048574 "Init" 1048575 "Fehler" ;
VAL_ 1719 KBI_Reset_Standzeit 0 "Standzeit iO" 1 "KL30 war weg" ;
VAL_ 1719 KBI_Inhalt_Tank 127 "Fehler" ;
VAL_ 1719 KBI_FStatus_Tank 1 "Tankfüllstand n.i.O" 0 "Tankfüllstand i.O." ;
VAL_ 1719 KBI_QBit_Aussen_Temp_gef 0 "gültiger Wert" 1 "Ersatz-, Init- oder Fehlerwert" ;
VAL_ 1719 KBI_Aussen_Temp_gef 253 "nicht verbaut" 254 "Init" 255 "Fehler" ;
VAL_ 1137 BCM2_Bremsl_durch_ECD 1 "Bremslicht durch ECD aktiv" 0 "Bremslicht ist aus" ;
VAL_ 1137 LH_Aussenlicht_def 1 "defekt" 0 "OK" ;
VAL_ 1137 LH_Standlicht_H_aktiv 1 "Standlicht hinten aktiv" ;
VAL_ 1137 LH_Parklicht_HL_aktiv 1 "Parklicht hinten links aktiv" 0 "nicht aktiv" ;
VAL_ 1137 LH_Parklicht_HR_aktiv 0 "nicht aktiv" 1 "Parklicht hinten rechts aktiv" ;
VAL_ 1137 LH_Bremslicht_H_aktiv 1 "Bremslicht hinten aktiv" ;
VAL_ 1137 LH_Nebelschluss_aktiv 0 "nicht aktiv" 1 "aktiv" ;
VAL_ 1137 LH_Rueckfahrlicht_aktiv 1 "aktiv" 0 "nicht aktiv" ;
VAL_ 1137 LH_Blinker_HL_akt 1 "Blinker hinten links aktiv" ;
VAL_ 1137 LH_Blinker_HR_akt 1 "Blinker hinten rechts aktiv" ;
VAL_ 1137 LH_Blinker_li_def 1 "Blinker hinten links defekt" 0 "OK" ;
VAL_ 1137 LH_Bremsl_li_def 1 "mindestens ein Bremslicht hinten links defekt" 0 "OK" ;
VAL_ 1137 LH_Schlusslicht_li_def 1 "mindestens ein Schlusslicht hinten links defekt" 0 "OK" ;
VAL_ 1137 LH_Rueckf_li_def 0 "OK" 1 "Rückfahrlicht hinten links defekt" ;
VAL_ 1137 LH_Nebel_li_def 0 "OK" 1 " Nebelschlusslicht hinten links defekt" ;
VAL_ 1137 LH_Schluss_Brems_li_def 0 "OK" 1 "defekt" ;
VAL_ 1137 LH_Schluss_Nebel_li_def 0 "OK" 1 "defekt" ;
VAL_ 1137 LH_SL_BRL_BLK_li_def 1 "defekt" 0 "OK" ;
VAL_ 1137 LH_Brems_Blk_li_def 1 "defekt" 0 "OK" ;
VAL_ 1137 LH_Blinker_re_def 1 "Blinker hinten rechts defekt" 0 "OK" ;
VAL_ 1137 LH_Bremsl_re_def 0 "OK" 1 "mindestens ein Bremslicht hinten rechts defekt" ;
VAL_ 1137 LH_Schlusslicht_re_def 0 "OK" 1 "mindestens ein Schlusslicht hinten rechts defekt" ;
VAL_ 1137 LH_Rueckf_re_def 0 "OK" 1 "Rückfahrlicht hinten rechts defekt" ;
VAL_ 1137 LH_Nebel_re_def 1 "Nebelschlusslicht hinten rechts defekt" 0 "OK" ;
VAL_ 1137 LH_Schluss_Brems_re_def 1 "defekt" 0 "OK" ;
VAL_ 1137 LH_Schluss_Nebel_re_def 0 "OK" 1 "defekt" ;
VAL_ 1137 LH_SL_BRL_BLK_re_def 0 "OK" 1 "defekt" ;
VAL_ 1137 LH_Brems_Blk_re_def 1 "defekt" 0 "OK" ;
VAL_ 1137 LH_Kennzl_def 0 "OK" 1 "Kennzeichenbeleuchtung hinten defekt" ;
VAL_ 1137 LH_3_Bremsl_def 1 "hochgesetzte  Bremsleuchte defekt" 0 "OK" ;
VAL_ 1137 LH_Nebel_mi_def 0 "OK" 1 " Nebelschlusslicht hinten Mitte defekt" ;
VAL_ 1137 LH_Rueckf_mi_def 1 "Rückfahllicht Mitte defekt" 0 "OK" ;
VAL_ 1137 LH_Bremsl_li_ges_def 1 "Alle Bremslichter hinten links defekt" 0 "OK" ;
VAL_ 1137 LH_Bremsl_re_ges_def 1 "Alle Bremslichter hinten rechts defekt" 0 "OK" ;
VAL_ 267 LS_Hauptschalter 1 "Ein" 0 "Gerastet Aus" ;
VAL_ 267 LS_Abbrechen 1 "Tippschalter betaetigt" 0 "Tippschalter nicht betaetigt" ;
VAL_ 267 LS_Limiter 0 "Limiter aus" 1 "Limiter ein" ;
VAL_ 267 LS_Tip_Setzen 1 "Tippschalter betaetigt" 0 "Tippschalter nicht betaetigt" ;
VAL_ 267 LS_Tip_Hoch 1 "Tippschalter betaetigt" 0 "Tippschalter nicht betaetigt" ;
VAL_ 267 LS_Tip_Runter 1 "Tippschalter betaetigt" 0 "Tippschalter nicht betaetigt" ;
VAL_ 267 LS_Tip_Wiederaufnahme 1 "Tippschalter betaetigt" 0 "Tippschalter nicht betaetigt" ;
VAL_ 267 LS_Verstellung_Zeitluecke 2 "Dist +1" 1 "Dist -1" 3 "nicht belegt" 0 "Taste nicht betaetigt" ;
VAL_ 267 LS_Tiptronic_Fehler 1 "Fehler erkannt" 0 " i. O." ;
VAL_ 267 LS_Codierung 6 "nicht verwendet" 0 "kein Hebel, keine Tiptronic am Lenkrad" 1 "kein Hebel, Tiptronic am Lenkrad" 3 "GRA Hebel, Tiptronic am Lenkrad" 5 "ACC Hebel, Tiptronic am Lenkrad" 2 "GRA Hebel, keine Tiptronic am Lenkrad" 7 "nicht verwendet" 4 "ACC Hebel, keine Tiptronic am Lenkrad" ;
VAL_ 134 LWI_Sensorstatus 1 "nicht kalibriert" 0 "iO" ;
VAL_ 134 LWI_QBit_Sub_Daten 0 "LWS-Subinfo 'real' (Lenkradwinkelinformation ADS-tauglich) " 1 "LWS-Subinfo 'simuliert' (Lenkradwinkelinformation nicht ADS-tauglich )" ;
VAL_ 134 LWI_QBit_Lenkradwinkel 1 "ausserhalb der Spezifikation" 0 "gültiger Wert" ;
VAL_ 134 LWI_Lenkradwinkel 8190 "Init" 8191 "Fehler" ;
VAL_ 134 LWI_VZ_Lenkradwinkel 0 "positiv (links von der Nullstellung)" 1 "negativ" ;
VAL_ 134 LWI_VZ_Lenkradw_Geschw 0 "positiv (links von der Nullstellung)" 1 "negativ" ;
VAL_ 134 LWI_Lenkradw_Geschw 510 "Init" 511 "Fehler" ;
VAL_ 917 AFS_Lampe 0 "Aus" 1 "Ein" ;
VAL_ 917 LWR_Lampe 1 "LWR Fehlerlampe ein" 0 "LWR Fehlerlampe aus" ;
VAL_ 917 AFS_Fehlertext 1 "AFS ohne Funktion" 0 "kein Text" ;
VAL_ 917 AFS_LED_Blinkmode 0 "kein Blinkmode angefordert" 1 "Blinkmode angefordert" ;
VAL_ 917 LWR_Touristenmodus_aktiv 0 "Touristenmodus inaktiv" 1 "Touristenmodus aktiv" ;
VAL_ 917 AFS_Sollwert_LD_EVG 254 "Init" 255 "Fehler" ;
VAL_ 917 LWR_Pos_Schrittmotor 254 "Init" 255 "Fehler" ;
VAL_ 917 LWR_Hoehenwert_VL 254 "nicht_initialisiert" 255 "Fehler" ;
VAL_ 917 LWR_Hoehenwert_HL 254 "nicht_initialisiert" 255 "Fehler" ;
VAL_ 917 AFS_Ersatzlicht_Links 0 "keine Ersatzlichtfunktion links" 1 "Ersatzlichtfunktion links" ;
VAL_ 917 AFS_Ersatzlicht_Rechts 0 "keine Ersatzlichtfunktion rechts" 1 "Ersatzlichtfunktion rechts" ;
VAL_ 917 LWR_AFS_Grundeinstellung 0 "Grundeinstellung nicht erfolgt" 1 "Grundeinstellung erfolgt" ;
VAL_ 917 LWR_AFS_Parametrisierung 1 "Parametrisierung erfolgt" 0 "Parametrisierung nicht erfolgt" ;
VAL_ 917 LWR_Initialisierungslauf 1 "Initialisierungslauf erfolgt" 0 "Initialisierungslauf nicht erfolgt" ;
VAL_ 917 LWR_Sicherheitsposition 1 "Sicherheitsposition ein" 0 "Sicherheitsposition aus" ;
VAL_ 917 LWR_Modus 1 "LWR dynamisch" 0 "LWR statisch" ;
VAL_ 917 LWR_KD_Fehler 1 "eingetragen" 0 "nicht eingetragen" ;
VAL_ 128 MO_Mom_o_ex 1022 "Init" 1023 "Fehler" ;
VAL_ 128 MO_Mom_m_ex 1022 "Init" 1023 "Fehler" ;
VAL_ 128 MO_Mom_Verlust 1022 "Init" 1023 "Fehler" ;
VAL_ 128 MO_Mom_Begrenzung 1022 "Init" 1023 "Fehler" ;
VAL_ 128 MO_Mom_Fahrerwunsch 1022 "Init" 1023 "Fehler" ;
VAL_ 128 MO_Kickdown 0 "kein Kickdown" 1 "Kickdown" ;
VAL_ 128 MO_KD_Fehler 1 "eingetragen" 0 "nicht eingetragen" ;
VAL_ 129 MO_Mom_ZWR 1022 "Init" 1023 "Fehler" ;
VAL_ 129 MO_Mom_Soll 1022 "Init" 1023 "Fehler" ;
VAL_ 129 MO_Mom_Ist 1022 "Init" 1023 "Fehler" ;
VAL_ 261 MO_QBit_Fahrpedalwerte_01 0 "gültiger Wert" 1 "Ersatz-, Init- oder Fehlerwert" ;
VAL_ 261 MO_QBit_Motormomente 0 "gültiger Wert" 1 "Ersatz-, Init- oder Fehlerwert" ;
VAL_ 261 MO_QBit_Fahrer_bremst 0 "gültiger Wert" 1 "Ersatz-, Init- oder Fehlerwert" ;
VAL_ 261 MO_QBit_Drehzahl_01 0 "gültiger Wert" 1 "Ersatz-, Init- oder Fehlerwert" ;
VAL_ 261 MO_Drehzahl_01 65535 "Fehler" ;
VAL_ 261 MO_Moment_im_Leerlauf 0 "kein Leergas" 1 "Leergas" ;
VAL_ 261 MO_Interlock 0 "Interlockschalter nicht betätigt" 1 "Interlockschalter betätigt" ;
VAL_ 261 MO_BLS 0 "kein Bremsen" 1 "Bremse betätigt" ;
VAL_ 261 MO_Fahrer_bremst 0 "kein Bremsen" 1 "Bremse betätigt" ;
VAL_ 261 MO_Kuppl_schalter 0 "Schalter sagt ausgekuppelt" 1 "Schalter sagt eingekuppelt" ;
VAL_ 261 MO_Timeout_ESP 1 "Timeout" 0 "Empfang i.O." ;
VAL_ 261 MO_Motor_laeuft 0 "Motor läuft nicht" 1 "Motor läuft autark und stabil und darf mechanisch belastet werden" ;
VAL_ 261 MO_Solldrehz_Leerlauf 255 "Fehler" ;
VAL_ 261 MO_Fahrpedalrohwert_01 255 "Fehler" ;
VAL_ 261 MO_erste_Ungenauschwelle 1 "Momente ungenauer >8%" 0 "genau" ;
VAL_ 261 MO_QBit_Stressfaktor 0 "gültiger Wert" 1 "Ersatz-, Init- oder Fehlerwert" ;
VAL_ 263 MO_Anzeigedrehz 4095 "Fehler" ;
VAL_ 263 MO_Ladedruck 511 "Fehler" ;
VAL_ 263 MO_KVS_Ueberlauf 0 "kein Ueberlauf" 1 "Kraftstoffverbrauchsignale mindestens 1x übergelaufen" ;
VAL_ 782 MO_Klima_Eingr 3 "Klimakompressor aufgrund der Heissleuchtenvorwarnung ausschalten" 1 "Klimakompressor ausschalten" 0 "kein Eingriff" 2 "Klimakompressor Leistungsreduzierung" ;
VAL_ 782 MO_Status_Normalbetrieb 0 "kein Normalbetrieb" 1 "Normalbetrieb erreicht" ;
VAL_ 782 MO_Prio_MIN_Wunschdrehzahl 0 "Wunsch" 1 "Zwang" ;
VAL_ 782 MO_Freig_Anlass 1 "Startfreigabe" 0 "Start nicht zulässig" ;
VAL_ 782 MO_Aussp_Anlass 0 "Motor läuft nicht stabil" 1 "Anlasser ausspuren (Motor läuft stabil)" ;
VAL_ 782 MO_MAX_Wunschdrehzahl 511 "Fehler" ;
VAL_ 782 MO_Prio_MAX_Wunschdrehzahl 0 "Wunsch" 1 "Zwang" ;
VAL_ 782 MO_Luftpfad_aktiv 1 "Eingriff über Luftpfad" 0 "kein Eingriff oder nur Eingriff über Zündpfad" ;
VAL_ 782 MO_v_Begrenz_Aktiv 1 "aktiv" 0 "inaktiv" ;
VAL_ 782 MO_v_Begrenz_Aktivierbar 0 "V-Begrenzung nicht möglich" 1 "V-Begrenzung möglich" ;
VAL_ 782 MO_Verbot_EKP 1 "Ansteuerung verboten" 0 "Ansteuerung zugelassen" ;
VAL_ 782 MO_Anf_Pruefimpuls 1 "Anforderung" 0 "keine Anforderung" ;
VAL_ 782 MO_Anf_KL75 0 "Anforderung KL75 ausschalten" 1 "Anforderung KL75 einschalten" ;
VAL_ 782 MO_Handshake_STH 0 "keine EKP-Ansteuerung durch STH-Anforderung" 1 "EKP-Ansteuerung durch STH-Anforderung" ;
VAL_ 782 MO_MIN_Wunschdrehzahl 255 "Fehler" ;
VAL_ 1088 WIV_Anzeige_aktiv 1 "WIV Anzeige aktiv" 0 "Anzeige aus" ;
VAL_ 1088 MO_Systemlampe 1 "Lampe ein" 0 "Lampe aus" ;
VAL_ 1088 MO_OBD2_Lampe 0 "Lampe aus" 1 "Lampe ein" ;
VAL_ 1088 MO_Heissleuchte 0 "Lampe aus" 1 "Lampe ein" ;
VAL_ 1088 MO_Partikel_Lampe 1 "Lampe ein" 0 "Lampe aus" ;
VAL_ 1088 WIV_Oelstand_nicht_vorhanden 0 "Ölstand vorhanden" 1 "Ölstand nicht vorhanden" ;
VAL_ 1088 WIV_nachfuellanzeige_ein 1 "Nachfüllanzeige" 0 "keine Nachfüllanzeige" ;
VAL_ 1088 WIV_Check_Oil 1 "Anzeige 'Check Oil'" 0 "keine Anzeige" ;
VAL_ 1088 MO_Tankdeckel_Lampe 1 "Lampe ein" 0 "Lampe aus" ;
VAL_ 1088 MO_Text_Tankdeckelwarn 1 "Anzeige Text Tankdeckelwarnung im Kombi" 0 "kein Text" ;
VAL_ 1088 MO_Avus_Motorschutz 2 "Drehzahlwarnung Stufe 2" 1 "Drehzahlwarnung Stufe 1" 0 "keine Warnung" 3 "Drehzahlwarnung Stufe 3" ;
VAL_ 1600 MO_QBit_Ansaugluft_Temp 0 "gültiger Wert" 1 "Ersatz-, Init- oder Fehlerwert" ;
VAL_ 1600 MO_QBit_Oel_Temp 0 "gültiger Wert" 1 "Ersatz-, Init- oder Fehlerwert" ;
VAL_ 1600 MO_QBit_Kuehlmittel_Temp 0 "gültiger Wert" 1 "Ersatz-, Init- oder Fehlerwert" ;
VAL_ 1600 MO_Ansaugluft_Temp 254 "Init" 255 "Fehler" ;
VAL_ 1600 MO_Oel_Temp 254 "Init" 255 "Fehler" ;
VAL_ 1600 MO_Kuehlmittel_Temp 254 "Init" 255 "Fehler" ;
VAL_ 1600 MO_Hoeheninfo 255 "Fehler" ;
VAL_ 1600 MO_Kennfeldk 0 "keine Kennfeldkühlung vorhanden" 1 "Kennfeldkühlung vorhanden" ;
VAL_ 1600 MO_Versionsinfo 0 "zum Projektbeginn 'aufgeräumter CAN' " ;
VAL_ 135 MO_QBit_Drehzahl_02 0 "gültiger Wert" 1 "Ersatz-, Init- oder Fehlerwert" ;
VAL_ 135 MO_QBit_Fahrpedalwerte_02 0 "gültiger Wert" 1 "Ersatz-, Init- oder Fehlerwert" ;
VAL_ 135 MO_Status_Zylabschalt 0 "alle Zylinder brennen" 1 "mindestens ein Zylinder wurde abgeschaltet" ;
VAL_ 135 MO_Drehzahl_02 65535 "Fehler" ;
VAL_ 135 MO_Fahrpedalrohwert_02 255 "Fehler" ;
VAL_ 1607 MO_ITM_Kuehlmittel_Temp 0 "nicht_verbaut" 2 "Fehler" ;
VAL_ 1607 MO_E85_Sensor 13 "nicht_verbaut" 15 "Fehler" ;
VAL_ 1607 SCR_Anz_Motorstarts 15 "keine Einschränkung (Anzeige Reichweite)" ;
VAL_ 1607 SCR_Reichweite 32767 "Init" ;
VAL_ 1607 SCR_Warnstufe_1 0 "nicht aktiv" 1 "Warnstufe 1 aktiv" ;
VAL_ 1607 SCR_Warnstufe_2 0 "nicht aktiv" 1 "Warnstufe 2 aktiv" ;
VAL_ 1607 SCR_Text 0 "kein Text" 1 "Warntext 1" 2 "Warntext 2" 3 "Hinweistext (nur AUDI)" 4 "Reserve" 5 "Warntext 'SCR-Systemfehler Stufe 1'" 6 "Warntext 'SCR-Systemfehler Stufe 2'" ;
VAL_ 1607 SCR_Akustik 0 "keine Akustik" 1 "Akustik 1" 2 "Akustik 2" 3 "Akustik_bei_Hinweis_(VW)" ;
VAL_ 1607 MO_Kraftstofffilter_Wasser 0 "keine_Anzeige" 1 "Abscheidevolumen_erschoepft" ;
VAL_ 1607 SCR_Systemfehler 0 "Warnung_nicht_aktiv" 1 "Warnung_aktiv" ;
VAL_ 1607 SCR_Inducement_Strategie 0 "Restart_Strategie" 1 "Reduced_Drivability_Strategie" ;
VAL_ 1607 MO_CO2_Faktor 0 "nicht_verbaut" 4095 "Fehler" ;
VAL_ 1607 MO_MKB_MUX 0 "MKB_01" 1 "MKB_02" 2 "MKB_03" 3 "MKB_04" ;
VAL_ 1607 MO_MKB_01 0 "Minus" 1 "A" 2 "B" 3 "C" 4 "D" 5 "E" 6 "F" 7 "G" 8 "H" 9 "I" 10 "J" 11 "K" 12 "L" 13 "M" 14 "N" 15 "O" 16 "P" 17 "Q" 18 "R" 19 "S" 20 "T" 21 "U" 22 "V" 23 "W" 24 "X" 25 "Y" 26 "Z" 27 "Leerzeichen" 28 "Leerzeichen" 29 "Leerzeichen" 30 "Leerzeichen" 31 "Unterstrich" ;
VAL_ 1607 MO_MKB_02 0 "Minus" 1 "A" 2 "B" 3 "C" 4 "D" 5 "E" 6 "F" 7 "G" 8 "H" 9 "I" 10 "J" 11 "K" 12 "L" 13 "M" 14 "N" 15 "O" 16 "P" 17 "Q" 18 "R" 19 "S" 20 "T" 21 "U" 22 "V" 23 "W" 24 "X" 25 "Y" 26 "Z" 27 "Leerzeichen" 28 "Leerzeichen" 29 "Leerzeichen" 30 "Leerzeichen" 31 "Unterstrich" ;
VAL_ 1607 MO_MKB_03 0 "Minus" 1 "A" 2 "B" 3 "C" 4 "D" 5 "E" 6 "F" 7 "G" 8 "H" 9 "I" 10 "J" 11 "K" 12 "L" 13 "M" 14 "N" 15 "O" 16 "P" 17 "Q" 18 "R" 19 "S" 20 "T" 21 "U" 22 "V" 23 "W" 24 "X" 25 "Y" 26 "Z" 27 "Leerzeichen" 28 "Leerzeichen" 29 "Leerzeichen" 30 "Leerzeichen" 31 "Unterstrich" ;
VAL_ 1607 MO_MKB_04 0 "Minus" 1 "A" 2 "B" 3 "C" 4 "D" 5 "E" 6 "F" 7 "G" 8 "H" 9 "I" 10 "J" 11 "K" 12 "L" 13 "M" 14 "N" 15 "O" 16 "P" 17 "Q" 18 "R" 19 "S" 20 "T" 21 "U" 22 "V" 23 "W" 24 "X" 25 "Y" 26 "Z" 27 "Leerzeichen" 28 "Leerzeichen" 29 "Leerzeichen" 30 "Leerzeichen" 31 "Unterstrich" ;
